VERSION ""

NS_ :

BS_:

BU_: BCM ELL ELR ERL ERR KHD N3P NAG NAP NCL NCP NPR NSP NVO PLG RSH RSL RSR SGW

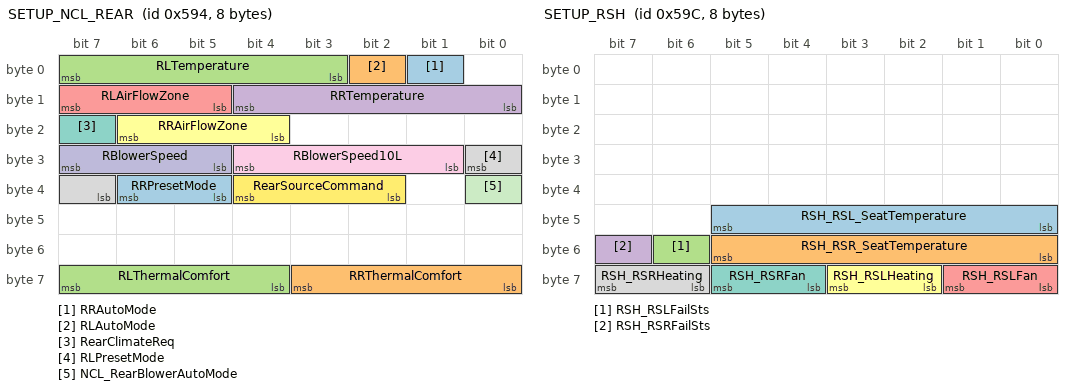
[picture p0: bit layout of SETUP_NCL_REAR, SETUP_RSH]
BO_ 1428 SETUP_NCL_REAR: 8 NCL
 SG_ RRAutoMode : 1|1@0+ (1,0) [0|1] ""  SGW
 SG_ RLAutoMode : 2|1@0+ (1,0) [0|1] ""  SGW
 SG_ RLTemperature : 7|5@0+ (0.5,15.5) [15.5|28.5] ""  SGW
 SG_ RRTemperature : 12|5@0+ (0.5,15.5) [15.5|28.5] ""  SGW
 SG_ RLAirFlowZone : 15|3@0+ (1,0) [0|7] ""  SGW
 SG_ RRAirFlowZone : 22|3@0+ (1,0) [0|7] ""  SGW
 SG_ RearClimateReq : 23|1@0+ (1,0) [0|1] ""  SGW
 SG_ RLPresetMode : 24|2@0+ (1,0) [0|3] ""  SGW
 SG_ RBlowerSpeed10L : 28|4@0+ (1,0) [0|15] ""  SGW
 SG_ RBlowerSpeed : 31|3@0+ (1,0) [0|7] ""  SGW
 SG_ NCL_RearBlowerAutoMode : 32|1@0+ (1,0) [0|1] ""  SGW
 SG_ RearSourceCommand : 36|3@0+ (1,0) [0|7] ""  SGW
 SG_ RRPresetMode : 38|2@0+ (1,0) [0|3] ""  SGW
 SG_ RRThermalComfort : 59|4@0+ (1,0) [0|15] ""  SGW
 SG_ RLThermalComfort : 63|4@0+ (1,0) [0|15] ""  SGW

BO_ 1429 SETUP_RSL: 8 RSL
 SG_ RSL_SeatTemperature : 1|6@0+ (1,-10) [-10|50] ""  NCL,SGW
 SG_ RSLHeating : 5|2@0+ (1,0) [0|3] ""  NCL,SGW
 SG_ RSLFans : 7|2@0+ (1,0) [0|3] ""  NCL,SGW

BO_ 1430 SETUP_RSR: 8 RSR
 SG_ RSR_SeatTemperature : 1|6@0+ (1,-10) [-10|50] ""  NCL,SGW
 SG_ RSRHeating : 5|2@0+ (1,0) [0|3] ""  NCL,SGW
 SG_ RSRFans : 7|2@0+ (1,0) [0|3] ""  NCL,SGW

BO_ 1431 SETUP_RSL_V3: 8 RSL
 SG_ RearSeatLeftBackRestPos : 18|11@0+ (1,0) [0|2047] ""  SGW
 SG_ RearSeatLeftLongitudinalPos : 39|11@0+ (1,0) [0|2047] ""  SGW
 SG_ RearSeatLeftTiltPos : 44|10@0+ (1,0) [0|1023] ""  SGW
 SG_ RearSeatLeftLiftPos : 50|11@0+ (1,0) [0|2047] ""  SGW

BO_ 1432 SETUP_RSR_V3: 8 RSR
 SG_ RearSeatRightBackRestPos : 18|11@0+ (1,0) [0|2047] ""  SGW
 SG_ RearSeatRightLongitudinalPos : 39|11@0+ (1,0) [0|2047] ""  SGW
 SG_ RearSeatRightTiltPos : 44|10@0+ (1,0) [0|1023] ""  SGW
 SG_ RearSeatRightLiftPos : 50|11@0+ (1,0) [0|2047] ""  SGW

BO_ 1436 SETUP_RSH: 8 RSH
 SG_ RSH_RSL_SeatTemperature : 45|6@0+ (1,-10) [-10|50] ""  NCL,SGW
 SG_ RSH_RSR_SeatTemperature : 53|6@0+ (1,-10) [-10|50] ""  NCL,SGW
 SG_ RSH_RSLFailSts : 54|1@0+ (1,0) [0|1] ""  SGW
 SG_ RSH_RSRFailSts : 55|1@0+ (1,0) [0|1] ""  SGW
 SG_ RSH_RSLFan : 57|2@0+ (1,0) [0|3] ""  NCL,SGW
 SG_ RSH_RSLHeating : 59|2@0+ (1,0) [0|3] ""  NCL,SGW
 SG_ RSH_RSRFan : 61|2@0+ (1,0) [0|3] ""  NCL,SGW
 SG_ RSH_RSRHeating : 63|2@0+ (1,0) [0|3] ""  NCL,SGW

BO_ 1441 PWT_STATUS_2: 8 SGW
 SG_ CRC_PWT_STATUS_2 : 7|8@0+ (1,0) [0|255] "" Vector__XXX
 SG_ ReducePowerAssist : 9|1@0+ (1,0) [0|1] "" Vector__XXX
 SG_ BatteryDisconnectionWarning : 10|1@0+ (1,0) [0|1] "" Vector__XXX
 SG_ VCU_EnergyProfileRqt : 13|3@0+ (1,0) [0|7] ""  NCL
 SG_ VehicleNotInUse : 15|2@0+ (1,0) [0|3] "" Vector__XXX
 SG_ EManettinoSts : 18|3@0+ (1,0) [0|7] ""  NCL
 SG_ EManettinoFailSts : 19|1@0+ (1,0) [0|1] ""  NCL
 SG_ EManettinoTransitionInfo : 22|3@0+ (1,0) [0|7] "" Vector__XXX
 SG_ MVLoadEnable_NPR : 23|1@0+ (1,0) [0|1] ""  NPR
 SG_ BatteryVoltageLevel : 30|7@0+ (0.16,0) [0|18] "volt"  KHD
 SG_ CruiseControlSts : 31|1@0+ (1,0) [0|1] "" Vector__XXX
 SG_ CruiseControlLampSts : 33|2@0+ (1,0) [0|3] "" Vector__XXX
 SG_ RechargeSts : 34|1@0+ (1,0) [0|1] "" Vector__XXX
 SG_ MsgCnt_PWT_STATUS_2 : 38|4@0+ (1,0) [0|15] "" Vector__XXX
 SG_ BatteryVoltageLevelFailSts : 39|1@0+ (1,0) [0|1] ""  KHD
 SG_ EngineSts : 45|2@0+ (1,0) [0|3] "" Vector__XXX
 SG_ StopStartSts : 47|2@0+ (1,0) [0|3] "" Vector__XXX
 SG_ PowertrainSts : 50|3@0+ (1,0) [0|7] "" Vector__XXX
 SG_ EDriveSts : 54|2@0+ (1,0) [0|3] "" Vector__XXX
 SG_ TargetSpeed : 63|8@0+ (1,0) [0|255] "km/h" Vector__XXX

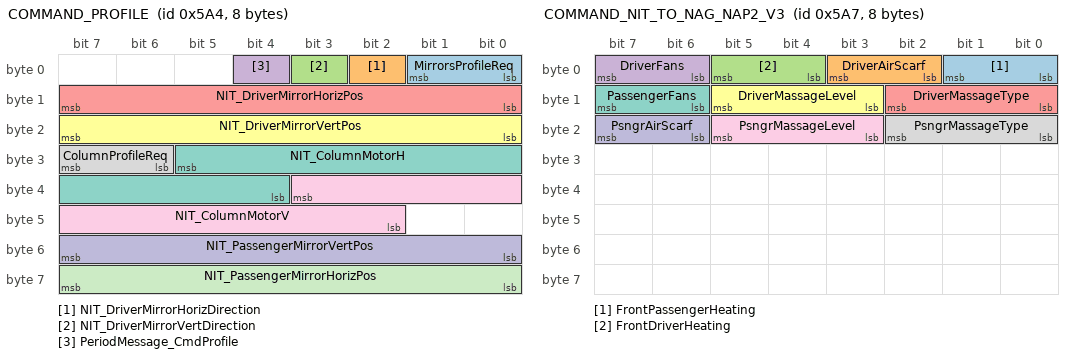
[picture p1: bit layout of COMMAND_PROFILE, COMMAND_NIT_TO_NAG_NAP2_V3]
BO_ 1444 COMMAND_PROFILE: 8 SGW
 SG_ MirrorsProfileReq : 1|2@0+ (1,0) [0|3] ""  BCM
 SG_ NIT_DriverMirrorHorizDirection : 2|1@0+ (1,0) [0|1] ""  BCM
 SG_ NIT_DriverMirrorVertDirection : 3|1@0+ (1,0) [0|1] ""  BCM
 SG_ PeriodMessage_CmdProfile : 4|1@0+ (1,0) [0|1] ""  BCM,NAG
 SG_ NIT_DriverMirrorHorizPos : 15|8@0+ (1,0) [0|255] ""  BCM
 SG_ NIT_DriverMirrorVertPos : 23|8@0+ (1,0) [0|255] ""  BCM
 SG_ NIT_ColumnMotorH : 29|10@0+ (1,0) [0|1023] ""  NAG
 SG_ ColumnProfileReq : 31|2@0+ (1,0) [0|3] ""  NAG
 SG_ NIT_ColumnMotorV : 35|10@0+ (1,0) [0|1023] ""  NAG
 SG_ NIT_PassengerMirrorVertPos : 55|8@0+ (1,0) [0|255] ""  BCM
 SG_ NIT_PassengerMirrorHorizPos : 63|8@0+ (1,0) [0|255] ""  BCM

BO_ 1446 COMMAND_NIT_TO_NBC: 8 SGW
 SG_ NITAmbientLightNightDay : 0|1@0+ (1,0) [0|1] ""  BCM
 SG_ NITAmbientLightNightDaySwitch : 1|1@0+ (1,0) [0|1] ""  BCM
 SG_ NITAmbientLightIntensityNight : 4|3@0+ (1,0) [0|7] ""  BCM
 SG_ NITAmbientLightIntensityDay : 7|3@0+ (1,0) [0|7] ""  BCM
 SG_ MirrorMovementReqCntrl : 8|1@0+ (1,0) [0|1] ""  BCM
 SG_ NITAmbientLightNightEnable : 10|1@0+ (1,0) [0|1] ""  BCM
 SG_ NITAmbientLightDayEnable : 11|1@0+ (1,0) [0|1] ""  BCM
 SG_ NITAmbientLightColour : 15|4@0+ (1,0) [0|15] ""  BCM
 SG_ NIT_DimmingLevelRoof2 : 34|3@0+ (1,0) [0|7] ""  BCM
 SG_ NIT_DimmingLevelRoof1 : 37|3@0+ (1,0) [0|7] ""  BCM
 SG_ IDC_Deactivation_DoorOpening_Swi : 40|1@0+ (1,0) [0|1] ""  BCM
 SG_ NITFailSts : 41|1@0+ (1,0) [0|1] ""  BCM
 SG_ NIT_DimmingLevelRoof4 : 44|3@0+ (1,0) [0|7] ""  BCM
 SG_ NIT_DimmingLevelRoof3 : 47|3@0+ (1,0) [0|7] ""  BCM
 SG_ NIT_DimmingLevelRoof6 : 50|3@0+ (1,0) [0|7] ""  BCM
 SG_ NIT_DimmingLevelRoof5 : 53|3@0+ (1,0) [0|7] ""  BCM
 SG_ IDC_Spot_RH_Button_Rear : 54|1@0+ (1,0) [0|1] ""  BCM
 SG_ IDC_Spot_LH_Button_Rear : 55|1@0+ (1,0) [0|1] ""  BCM
 SG_ ChargeButtonReq : 61|3@0+ (1,0) [0|7] ""  BCM
 SG_ IDC_RearLightCommand_Left : 62|1@0+ (1,0) [0|1] ""  BCM
 SG_ IDC_RearLightCommand_Right : 63|1@0+ (1,0) [0|1] ""  BCM

BO_ 1447 COMMAND_NIT_TO_NAG_NAP2_V3: 8 SGW
 SG_ FrontPassengerHeating : 1|2@0+ (1,0) [0|3] ""  NAG,NAP
 SG_ DriverAirScarf : 3|2@0+ (1,0) [0|3] ""  NAG,NAP
 SG_ FrontDriverHeating : 5|2@0+ (1,0) [0|3] ""  NAG,NAP
 SG_ DriverFans : 7|2@0+ (1,0) [0|3] ""  NAG,NAP
 SG_ DriverMassageType : 10|3@0+ (1,0) [0|7] ""  NAG,NAP
 SG_ DriverMassageLevel : 13|3@0+ (1,0) [0|7] ""  NAG,NAP
 SG_ PassengerFans : 15|2@0+ (1,0) [0|3] ""  NAG,NAP
 SG_ PsngrMassageType : 18|3@0+ (1,0) [0|7] ""  NAG,NAP
 SG_ PsngrMassageLevel : 21|3@0+ (1,0) [0|7] ""  NAG,NAP
 SG_ PsngrAirScarf : 23|2@0+ (1,0) [0|3] ""  NAG,NAP

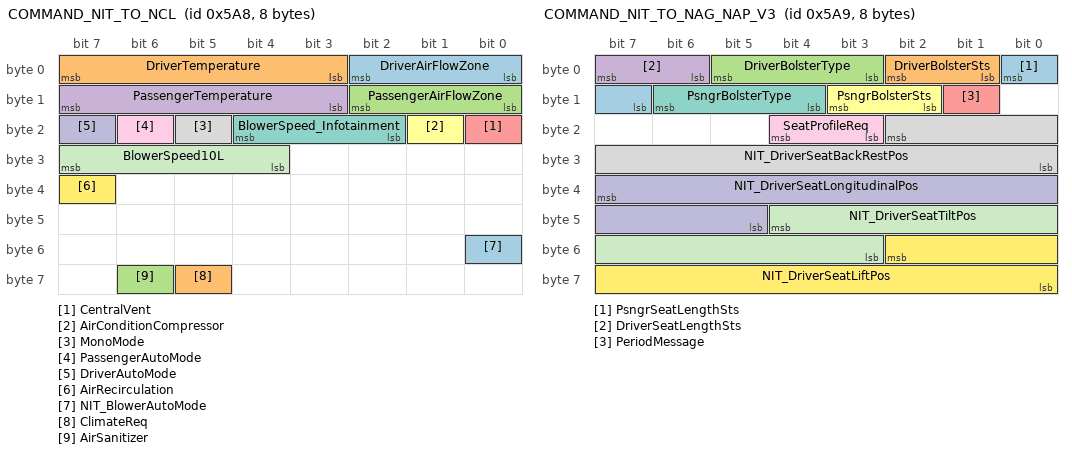
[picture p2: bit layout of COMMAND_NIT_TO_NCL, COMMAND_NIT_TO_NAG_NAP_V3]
BO_ 1448 COMMAND_NIT_TO_NCL: 8 SGW
 SG_ DriverAirFlowZone : 2|3@0+ (1,0) [0|7] ""  NCL
 SG_ DriverTemperature : 7|5@0+ (0.5,15.5) [15.5|28.5] ""  NCL
 SG_ PassengerAirFlowZone : 10|3@0+ (1,0) [0|7] ""  NCL
 SG_ PassengerTemperature : 15|5@0+ (0.5,15.5) [15.5|28.5] ""  NCL
 SG_ CentralVent : 16|1@0+ (1,0) [0|1] ""  NCL
 SG_ AirConditionCompressor : 17|1@0+ (1,0) [0|1] ""  NCL
 SG_ BlowerSpeed_Infotainment : 20|3@0+ (1,0) [0|7] ""  NCL
 SG_ MonoMode : 21|1@0+ (1,0) [0|1] ""  NCL
 SG_ PassengerAutoMode : 22|1@0+ (1,0) [0|1] ""  NCL
 SG_ DriverAutoMode : 23|1@0+ (1,0) [0|1] ""  NCL
 SG_ BlowerSpeed10L : 31|4@0+ (1,0) [0|15] ""  NCL
 SG_ AirRecirculation : 39|1@0+ (1,0) [0|1] ""  NCL
 SG_ NIT_BlowerAutoMode : 48|1@0+ (1,0) [0|1] ""  NCL
 SG_ ClimateReq : 61|1@0+ (1,0) [0|1] ""  NCL
 SG_ AirSanitizer : 62|1@0+ (1,0) [0|1] ""  NCL

BO_ 1449 COMMAND_NIT_TO_NAG_NAP_V3: 8 SGW
 SG_ PsngrSeatLengthSts : 0|2@0+ (1,0) [0|3] ""  NAG,NAP
 SG_ DriverBolsterSts : 2|2@0+ (1,0) [0|3] ""  NAG,NAP
 SG_ DriverBolsterType : 5|3@0+ (1,0) [0|7] ""  NAG,NAP
 SG_ DriverSeatLengthSts : 7|2@0+ (1,0) [0|3] ""  NAG,NAP
 SG_ PeriodMessage : 9|1@0+ (1,0) [0|1] ""  NAG,NAP
 SG_ PsngrBolsterSts : 11|2@0+ (1,0) [0|3] ""  NAG,NAP
 SG_ PsngrBolsterType : 14|3@0+ (1,0) [0|7] ""  NAG,NAP
 SG_ NIT_DriverSeatBackRestPos : 18|11@0+ (1,0) [0|2047] ""  NAG
 SG_ SeatProfileReq : 20|2@0+ (1,0) [0|3] ""  NAG
 SG_ NIT_DriverSeatLongitudinalPos : 39|11@0+ (1,0) [0|2047] ""  NAG
 SG_ NIT_DriverSeatTiltPos : 44|10@0+ (1,0) [0|1023] ""  NAG
 SG_ NIT_DriverSeatLiftPos : 50|11@0+ (1,0) [0|2047] ""  NAG

BO_ 1450 SETUP_NCL: 8 NCL
 SG_ AirRecirculation : 0|1@0+ (1,0) [0|1] ""  SGW
 SG_ PassengerAutoMode : 1|1@0+ (1,0) [0|1] ""  SGW
 SG_ DriverAutoMode : 2|1@0+ (1,0) [0|1] ""  SGW
 SG_ DriverTemperature : 7|5@0+ (0.5,15.5) [15.5|28.5] ""  SGW
 SG_ PassengerTemperature : 12|5@0+ (0.5,15.5) [15.5|28.5] ""  SGW
 SG_ DriverAirFlowZone : 15|3@0+ (1,0) [0|7] ""  SGW
 SG_ AirConditionCompressor : 16|1@0+ (1,0) [0|1] ""  SGW
 SG_ BlowerSpeed : 19|3@0+ (1,0) [0|7] ""  BCM,SGW
 SG_ PassengerAirFlowZone : 22|3@0+ (1,0) [0|7] ""  SGW
 SG_ MonoMode : 23|1@0+ (1,0) [0|1] ""  SGW
 SG_ BlowerSpeed10L : 28|4@0+ (1,0) [0|15] ""  SGW
 SG_ CentralVent : 29|1@0+ (1,0) [0|1] ""  SGW
 SG_ NCL_BlowerAutoMode : 33|1@0+ (1,0) [0|1] ""  SGW
 SG_ SourceCommand : 36|3@0+ (1,0) [0|7] ""  SGW
 SG_ Temp_Req_Down_Driver : 43|4@0+ (1,0) [0|15] ""  SGW
 SG_ Temp_Req_Up_Driver : 47|4@0+ (1,0) [0|15] ""  SGW
 SG_ AirSanitizer : 52|1@0+ (1,0) [0|1] ""  SGW
 SG_ ClimateReq : 56|1@0+ (1,0) [0|1] ""  SGW

BO_ 1451 COMMAND_NIT_TO_RSL_RSR: 8 SGW
 SG_ NIT_RLHeating : 5|2@0+ (1,0) [0|3] ""  RSH,RSL,RSR
 SG_ NIT_RLFans : 7|2@0+ (1,0) [0|3] ""  RSH,RSL,RSR
 SG_ NIT_RRHeating : 13|2@0+ (1,0) [0|3] ""  RSH,RSL,RSR
 SG_ NIT_RRFans : 15|2@0+ (1,0) [0|3] ""  RSH,RSL,RSR

BO_ 1452 COMMAND_NIT_TO_NCL_REAR: 8 SGW
 SG_ NIT_RLAirFlowZone : 2|3@0+ (1,0) [0|7] ""  NCL
 SG_ NIT_RLTemperature : 7|5@0+ (0.5,15.5) [15.5|28.5] ""  NCL
 SG_ NIT_RRAirFlowZone : 10|3@0+ (1,0) [0|7] ""  NCL
 SG_ NIT_RRTemperature : 15|5@0+ (0.5,15.5) [15.5|28.5] ""  NCL
 SG_ RearClimateReq : 16|1@0+ (1,0) [0|1] ""  NCL
 SG_ NIT_RearBlowerSpeed : 20|3@0+ (1,0) [0|7] ""  NCL
 SG_ NIT_RRAutoMode : 22|1@0+ (1,0) [0|1] ""  NCL
 SG_ NIT_RLAutoMode : 23|1@0+ (1,0) [0|1] ""  NCL
 SG_ NIT_RRPresetMode : 25|2@0+ (1,0) [0|3] ""  NCL
 SG_ NIT_RLPresetMode : 27|2@0+ (1,0) [0|3] ""  NCL
 SG_ NIT_RearBlowerSpeed10L : 31|4@0+ (1,0) [0|15] ""  NCL
 SG_ NIT_RLAirFlowZonePersPreset : 33|3@0+ (1,0) [0|7] ""  NCL
 SG_ NIT_RLTemperaturePersPreset : 38|5@0+ (0.5,15.5) [15.5|28.5] ""  NCL
 SG_ NIT_RearBlowerAutoMode : 39|1@0+ (1,0) [0|1] ""  NCL
 SG_ NIT_RRAirFlowZonePersPreset : 42|3@0+ (1,0) [0|7] ""  NCL
 SG_ NIT_RearBlowerSpeed10LPersPreset : 46|4@0+ (1,0) [0|15] ""  NCL
 SG_ NIT_RRTemperaturePersPreset : 55|5@0+ (0.5,15.5) [15.5|28.5] ""  NCL

BO_ 1454 COMMAND_MKF_TO_NBC: 8 Vector__XXX
 SG_ MKF_DimmingLevelRoof1 : 6|3@0+ (1,0) [0|7] ""  NCL
 SG_ MKF_RimHeatingCommand : 7|1@0+ (1,0) [0|1] ""  NCL

BO_ 1457 SETUP_NBC: 8 BCM
 SG_ NBCAmbientLightNightDay : 0|1@0+ (1,0) [0|1] ""  SGW
 SG_ NBCAmbientLightNightDaySwitch : 1|1@0+ (1,0) [0|1] ""  SGW
 SG_ NBCAmbientLightIntensityNight : 4|3@0+ (1,0) [0|7] ""  SGW
 SG_ NBCAmbientLightIntensityDay : 7|3@0+ (1,0) [0|7] ""  SGW
 SG_ NBCAmbientLightDayEnable : 8|1@0+ (1,0) [0|1] ""  SGW
 SG_ NBC_DimmingLevelRoof1 : 11|3@0+ (1,0) [0|7] ""  NCL,SGW
 SG_ NBCAmbientLightColour : 15|4@0+ (1,0) [0|15] ""  SGW
 SG_ NBCAmbientLightNightEnable : 17|1@0+ (1,0) [0|1] ""  SGW
 SG_ NBC_DimmingLevelRoof3 : 20|3@0+ (1,0) [0|7] ""  SGW
 SG_ NBC_DimmingLevelRoof2 : 23|3@0+ (1,0) [0|7] ""  SGW
 SG_ NBCAmbientLightResponseError : 24|1@0+ (1,0) [0|1] ""  SGW
 SG_ NBCAmbientLightEnable : 25|1@0+ (1,0) [0|1] ""  SGW
 SG_ NBC_DimmingLevelRoof5 : 28|3@0+ (1,0) [0|7] ""  SGW
 SG_ NBC_DimmingLevelRoof4 : 31|3@0+ (1,0) [0|7] ""  SGW
 SG_ NBCAmbientLightGenericFailSts : 32|1@0+ (1,0) [0|1] ""  SGW
 SG_ NBCAmbientLightCurrentFailSts : 33|1@0+ (1,0) [0|1] ""  SGW
 SG_ WiperWaterLevelLampSts : 34|1@0+ (1,0) [0|1] ""  SGW
 SG_ WiperWaterLowLevel : 35|1@0+ (1,0) [0|1] ""  SGW
 SG_ NBC_DimmingLevelRoof6 : 39|3@0+ (1,0) [0|7] ""  SGW
 SG_ NVDFailSts : 43|1@0+ (1,0) [0|1] ""  SGW

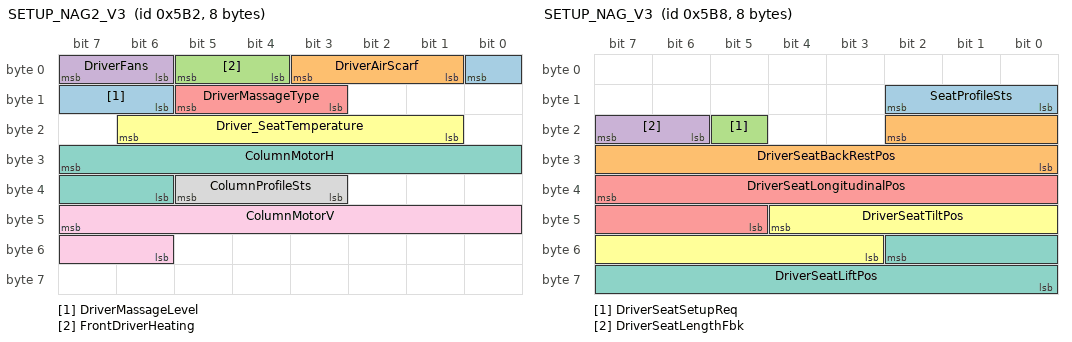
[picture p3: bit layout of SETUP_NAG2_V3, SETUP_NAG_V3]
BO_ 1458 SETUP_NAG2_V3: 8 NAG
 SG_ DriverMassageLevel : 0|3@0+ (1,0) [0|7] ""  NCL,SGW
 SG_ DriverAirScarf : 3|3@0+ (1,0) [0|7] ""  SGW
 SG_ FrontDriverHeating : 5|2@0+ (1,0) [0|3] ""  NCL,SGW
 SG_ DriverFans : 7|2@0+ (1,0) [0|3] ""  NCL,SGW
 SG_ DriverMassageType : 13|3@0+ (1,0) [0|7] ""  SGW
 SG_ Driver_SeatTemperature : 22|6@0+ (1,-10) [-10|50] ""  NCL,SGW
 SG_ ColumnMotorH : 31|10@0+ (1,0) [0|1023] ""  SGW
 SG_ ColumnProfileSts : 37|3@0+ (1,0) [0|7] ""  SGW
 SG_ ColumnMotorV : 47|10@0+ (1,0) [0|1023] ""  SGW

BO_ 1463 SETUP_NAP2: 8 NAP
 SG_ PsngrMassageLevel : 0|3@0+ (1,0) [0|7] ""  NCL,SGW
 SG_ PsngrAirScarf : 3|3@0+ (1,0) [0|7] ""  SGW
 SG_ FrontPassengerHeating : 5|2@0+ (1,0) [0|3] ""  NCL,SGW
 SG_ PassengerFans : 7|2@0+ (1,0) [0|3] ""  NCL,SGW
 SG_ PsngrMassageType : 13|3@0+ (1,0) [0|7] ""  SGW
 SG_ Psngr_SeatTemperature : 22|6@0+ (1,-10) [-10|50] ""  NCL,SGW

BO_ 1464 SETUP_NAG_V3: 8 NAG
 SG_ SeatProfileSts : 10|3@0+ (1,0) [0|7] ""  SGW
 SG_ DriverSeatBackRestPos : 18|11@0+ (1,0) [0|2047] ""  SGW
 SG_ DriverSeatSetupReq : 21|1@0+ (1,0) [0|1] ""  SGW
 SG_ DriverSeatLengthFbk : 23|2@0+ (1,0) [0|3] ""  SGW
 SG_ DriverSeatLongitudinalPos : 39|11@0+ (1,0) [0|2047] ""  SGW
 SG_ DriverSeatTiltPos : 44|10@0+ (1,0) [0|1023] ""  SGW
 SG_ DriverSeatLiftPos : 50|11@0+ (1,0) [0|2047] ""  SGW

BO_ 1465 SETUP_NAP_V3: 8 NAP
 SG_ PsngrSeatBackRestPos : 18|11@0+ (1,0) [0|2047] ""  SGW
 SG_ PsngrSeatSetupReq : 21|1@0+ (1,0) [0|1] ""  SGW
 SG_ PsngrSeatLengthFbk : 23|2@0+ (1,0) [0|3] ""  SGW
 SG_ PsngrSeatLongitudinalPos : 39|11@0+ (1,0) [0|2047] ""  SGW
 SG_ PsngrSeatTiltPos : 44|10@0+ (1,0) [0|1023] ""  SGW
 SG_ PsngrSeatLiftPos : 50|11@0+ (1,0) [0|2047] ""  SGW

BO_ 1485 HVB_HMI_STS: 8 SGW
 SG_ CRC_HVB_HMI_STS : 7|8@0+ (1,0) [0|255] ""  NCL
 SG_ LongParkingInfoForDisplay : 10|3@0+ (1,0) [0|7] "" Vector__XXX
 SG_ HVBBuzzerReq : 11|1@0+ (1,0) [0|1] "" Vector__XXX
 SG_ MsgCnt_HVB_HMI_STS : 15|4@0+ (1,0) [0|14] ""  NCL
 SG_ HVBChargeWarningForDisplay : 20|5@0+ (1,0) [0|31] "" Vector__XXX
 SG_ LongParkingSts : 21|1@0+ (1,0) [0|1] "" Vector__XXX
 SG_ HVBSOC_Status_HMI : 23|2@0+ (1,0) [0|3] "" Vector__XXX
 SG_ HVB_SOC_BEV_HMI : 31|8@0+ (0.392156862745098,0) [0|100] "%"  NCL
 SG_ HVB_TemperatureFailSts : 33|2@0+ (1,0) [0|3] "" Vector__XXX
 SG_ BatPrecondSts : 35|2@0+ (1,0) [0|3] "" Vector__XXX
 SG_ HVSysWarningForDisplay : 39|4@0+ (1,0) [0|15] "" Vector__XXX
 SG_ BatEstTimeToTarget : 46|7@0+ (1,0) [0|127] "min" Vector__XXX
 SG_ MILrequest : 47|1@0+ (1,0) [0|1] "" Vector__XXX
 SG_ BatPrecondProgress : 55|8@0+ (0.5,0) [0|127.5] "%" Vector__XXX
 SG_ HVBWarningForDisplay : 60|5@0+ (1,0) [0|31] "" Vector__XXX
 SG_ HVBStatus : 62|2@0+ (1,0) [0|3] "" Vector__XXX
 SG_ HVBSOC_Status_China_HMI : 63|1@0+ (1,0) [0|1] "" Vector__XXX

BO_ 1533 LIN_MIRROR_FEEDBACK: 8 BCM
 SG_ Fdbk_Pos_Hor_LH_Exmi : 7|8@0+ (1,0) [0|255] "Position Value"  SGW
 SG_ Fdbk_Pos_Ver_LH_Exmi : 15|8@0+ (1,0) [0|255] "Position Value"  SGW
 SG_ Fdbk_Pos_Hor_RH_Exmi : 23|8@0+ (1,0) [0|255] "Position Value"  SGW
 SG_ Fdbk_Pos_Ver_RH_Exmi : 31|8@0+ (1,0) [0|255] "Position Value"  SGW
 SG_ MirrorsProfileSts : 37|3@0+ (1,0) [0|7] ""  SGW

BO_ 1539 TRIP_A_E_B: 8 SGW
 SG_ TotalOdometer : 11|20@0+ (1,0) [0|999999] "km"  BCM,ELL,ELR,ERL,ERR,KHD,N3P,NCL,NCP,NPR,RSH

BO_ 1566 NIT_TO_NVO_DEBUG_MESSAGE: 8 SGW
 SG_ CommandWord : 7|8@0+ (1,0) [0|255] "" Vector__XXX
 SG_ CommandParameter1 : 15|8@0+ (1,0) [0|255] "" Vector__XXX
 SG_ CommandParameter2 : 23|8@0+ (1,0) [0|255] "" Vector__XXX
 SG_ CommandParameter3 : 31|8@0+ (1,0) [0|255] "" Vector__XXX
 SG_ CommandParameter4 : 39|8@0+ (1,0) [0|255] "" Vector__XXX
 SG_ CommandParameter5 : 47|8@0+ (1,0) [0|255] "" Vector__XXX
 SG_ CommandParameter6 : 55|8@0+ (1,0) [0|255] "" Vector__XXX

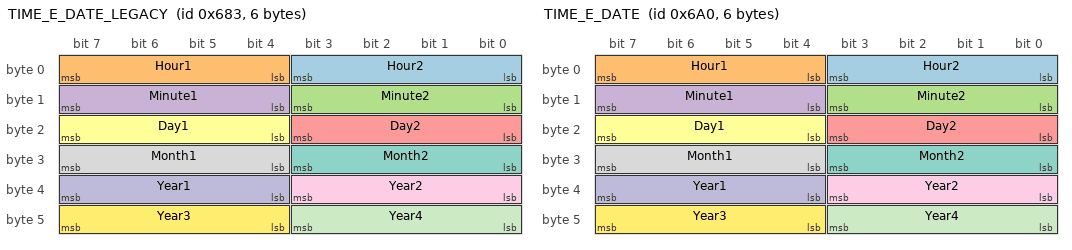
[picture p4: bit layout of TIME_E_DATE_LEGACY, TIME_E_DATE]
BO_ 1667 TIME_E_DATE_LEGACY: 6 BCM
 SG_ Hour2 : 3|4@0+ (1,0) [0|9] ""  ELL,ELR,ERL,ERR
 SG_ Hour1 : 7|4@0+ (1,0) [0|9] ""  ELL,ELR,ERL,ERR
 SG_ Minute2 : 11|4@0+ (1,0) [0|9] ""  ELL,ELR,ERL,ERR
 SG_ Minute1 : 15|4@0+ (1,0) [0|9] ""  ELL,ELR,ERL,ERR
 SG_ Day2 : 19|4@0+ (1,0) [0|9] ""  ELL,ELR,ERL,ERR
 SG_ Day1 : 23|4@0+ (1,0) [0|9] ""  ELL,ELR,ERL,ERR
 SG_ Month2 : 27|4@0+ (1,0) [0|9] ""  ELL,ELR,ERL,ERR
 SG_ Month1 : 31|4@0+ (1,0) [0|9] ""  ELL,ELR,ERL,ERR
 SG_ Year2 : 35|4@0+ (1,0) [0|9] ""  ELL,ELR,ERL,ERR
 SG_ Year1 : 39|4@0+ (1,0) [0|9] ""  ELL,ELR,ERL,ERR
 SG_ Year4 : 43|4@0+ (1,0) [0|9] ""  ELL,ELR,ERL,ERR
 SG_ Year3 : 47|4@0+ (1,0) [0|9] ""  ELL,ELR,ERL,ERR

BO_ 1671 NCL_TO_AUDIO_MSG1: 8 NCL
 SG_ LateralVentRgt : 21|6@0+ (2,0) [0|126] ""  SGW
 SG_ LateralVentLft : 29|6@0+ (2,0) [0|126] ""  SGW
 SG_ CentralVentRgt : 39|8@0+ (1,0) [0|255] ""  SGW
 SG_ CentralVentLft : 47|8@0+ (1,0) [0|255] ""  SGW
 SG_ BlwrPWMRr : 55|8@0+ (1,0) [0|255] ""  SGW
 SG_ BlwrPWM : 63|8@0+ (1,0) [0|255] ""  SGW

BO_ 1672 NCL_TO_AUDIO_MSG2: 8 NCL
 SG_ RHVACDistrib : 37|6@0+ (2,0) [0|126] ""  SGW
 SG_ TunnelDistrib : 45|6@0+ (2,0) [0|126] ""  SGW
 SG_ FloorRgt : 53|6@0+ (2,0) [0|126] ""  SGW
 SG_ FloorLft : 61|6@0+ (2,0) [0|126] ""  SGW

BO_ 1673 NCL_INFO: 8 NCL
 SG_ AirQualityIndexExternal : 0|9@0+ (1,0) [0|511] ""  SGW
 SG_ CabinTemperature : 23|8@0+ (1,-40) [-40|100] ""  NAG,NAP,SGW
 SG_ DriverCabinTemperatureFbk : 31|8@0+ (0.5,-20) [-20|60] "°C"  SGW
 SG_ PassengerCabinTemperatureFbk : 39|8@0+ (0.5,-20) [-20|60] "°C"  SGW
 SG_ NCL_EnergyProfileFbk : 42|3@0+ (1,0) [0|7] ""  SGW
 SG_ RLCabinTemperatureFbk : 55|8@0+ (0.5,-20) [-20|60] ""  SGW
 SG_ RRCabinTemperatureFbk : 63|8@0+ (0.5,-20) [-20|60] ""  SGW

BO_ 1674 NCL_Message2: 8 NCL
 SG_ CabTempFilt : 40|7@0+ (1,0) [0|127] "°C" Vector__XXX

BO_ 1696 TIME_E_DATE: 6 SGW
 SG_ Hour2 : 3|4@0+ (1,0) [0|9] ""  ELL,ELR,ERL,ERR,KHD,N3P,NCL,NCP,RSH
 SG_ Hour1 : 7|4@0+ (1,0) [0|9] ""  ELL,ELR,ERL,ERR,KHD,N3P,NCL,NCP,RSH
 SG_ Minute2 : 11|4@0+ (1,0) [0|9] ""  ELL,ELR,ERL,ERR,KHD,N3P,NCL,NCP,RSH
 SG_ Minute1 : 15|4@0+ (1,0) [0|9] ""  ELL,ELR,ERL,ERR,KHD,N3P,NCL,NCP,RSH
 SG_ Day2 : 19|4@0+ (1,0) [0|9] ""  ELL,ELR,ERL,ERR,KHD,N3P,NCL,NCP,RSH
 SG_ Day1 : 23|4@0+ (1,0) [0|9] ""  ELL,ELR,ERL,ERR,KHD,N3P,NCL,NCP,RSH
 SG_ Month2 : 27|4@0+ (1,0) [0|9] ""  ELL,ELR,ERL,ERR,KHD,N3P,NCL,NCP,RSH
 SG_ Month1 : 31|4@0+ (1,0) [0|9] ""  ELL,ELR,ERL,ERR,KHD,N3P,NCL,NCP,RSH
 SG_ Year2 : 35|4@0+ (1,0) [0|9] ""  ELL,ELR,ERL,ERR,KHD,N3P,NCL,NCP,RSH
 SG_ Year1 : 39|4@0+ (1,0) [0|9] ""  ELL,ELR,ERL,ERR,KHD,N3P,NCL,NCP,RSH
 SG_ Year4 : 43|4@0+ (1,0) [0|9] ""  ELL,ELR,ERL,ERR,KHD,N3P,NCL,NCP,RSH
 SG_ Year3 : 47|4@0+ (1,0) [0|9] ""  ELL,ELR,ERL,ERR,KHD,N3P,NCL,NCP,RSH

BO_ 1726 NIT_VEHICLE_SETUP_3: 8 SGW
 SG_ CabinLightNightDaySwitch : 8|1@0+ (1,0) [0|1] ""  BCM
 SG_ CabinLight_Feet_Enable : 9|1@0+ (1,0) [0|1] ""  BCM
 SG_ CabinLight_DoorPanel_Enable : 10|1@0+ (1,0) [0|1] ""  BCM
 SG_ AutoDoorsAlert : 11|1@0+ (1,0) [0|1] ""  BCM
 SG_ EManettinoPreset : 14|3@0+ (1,0) [0|7] ""  BCM
 SG_ SmartOverbrakingEnable : 15|1@0+ (1,0) [0|1] ""  BCM
 SG_ CabinLight_Feet_Level : 19|4@0+ (1,0) [0|15] ""  BCM
 SG_ CabinLight_DoorPanel_Level : 23|4@0+ (1,0) [0|15] ""  BCM
 SG_ InternalLightEnable : 24|1@0+ (1,0) [0|1] ""  BCM
 SG_ ChargePlugAutoUnlock : 27|2@0+ (1,0) [0|3] ""  BCM
 SG_ ActiveProfile : 31|4@0+ (1,0) [0|15] ""  BCM
 SG_ User_Max_SOC : 38|7@0+ (1,0) [0|100] "%"  BCM
 SG_ PassiveEntryEnable : 39|1@0+ (1,0) [0|1] ""  BCM
 SG_ PresentProfile : 41|11@0+ (1,0) [0|2047] ""  BCM
 SG_ PersonalDataConsentSts : 57|2@0+ (1,0) [0|3] ""  BCM
 SG_ StealthModeActive : 58|1@0+ (1,0) [0|1] ""  BCM
 SG_ User_SOC_Preset : 60|2@0+ (1,0) [0|3] ""  BCM
 SG_ ChargeFlapUnlock : 61|1@0+ (1,0) [0|1] ""  BCM
 SG_ AntiTiltAlarmCommand : 62|1@0+ (1,0) [0|1] ""  BCM

BO_ 1728 EOL_CONFIGURATION_V4: 8 BCM
 SG_ BatteryType : 13|4@0+ (1,0) [0|15] ""  NAG,NAP,RSL,RSR
 SG_ Profile : 36|1@0+ (1,0) [0|1] ""  NAG

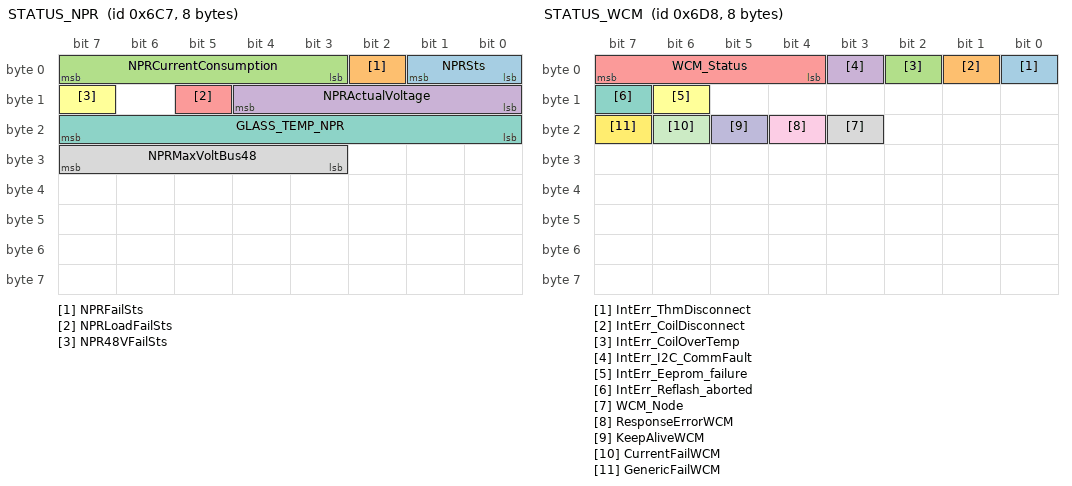
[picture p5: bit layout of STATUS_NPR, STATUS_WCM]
BO_ 1735 STATUS_NPR: 8 NPR
 SG_ NPRSts : 1|2@0+ (1,0) [0|3] ""  NCL,SGW
 SG_ NPRFailSts : 2|1@0+ (1,0) [0|1] ""  NCL,SGW
 SG_ NPRCurrentConsumption : 7|5@0+ (1,0) [0|31] "A"  SGW
 SG_ NPRActualVoltage : 12|5@0+ (2,0) [0|62] "V"  NCL,SGW
 SG_ NPRLoadFailSts : 13|1@0+ (1,0) [0|1] ""  SGW
 SG_ NPR48VFailSts : 15|1@0+ (1,0) [0|1] ""  SGW
 SG_ GLASS_TEMP_NPR : 23|8@0+ (0.5,-40) [-40|87.5] "°C"  NCL,SGW
 SG_ NPRMaxVoltBus48 : 31|5@0+ (2,0) [0|62] "V"  NCL,SGW

BO_ 1752 STATUS_WCM: 8 SGW
 SG_ IntErr_ThmDisconnect : 0|1@0+ (1,0) [0|1] "" Vector__XXX
 SG_ IntErr_CoilDisconnect : 1|1@0+ (1,0) [0|1] "" Vector__XXX
 SG_ IntErr_CoilOverTemp : 2|1@0+ (1,0) [0|1] "" Vector__XXX
 SG_ IntErr_I2C_CommFault : 3|1@0+ (1,0) [0|1] "" Vector__XXX
 SG_ WCM_Status : 7|4@0+ (1,0) [0|15] "" Vector__XXX
 SG_ IntErr_Eeprom_failure : 14|1@0+ (1,0) [0|1] "" Vector__XXX
 SG_ IntErr_Reflash_aborted : 15|1@0+ (1,0) [0|1] "" Vector__XXX
 SG_ WCM_Node : 19|1@0+ (1,0) [0|1] "" Vector__XXX
 SG_ ResponseErrorWCM : 20|1@0+ (1,0) [0|1] "" Vector__XXX
 SG_ KeepAliveWCM : 21|1@0+ (1,0) [0|1] "" Vector__XXX
 SG_ CurrentFailWCM : 22|1@0+ (1,0) [0|1] "" Vector__XXX
 SG_ GenericFailWCM : 23|1@0+ (1,0) [0|1] "" Vector__XXX

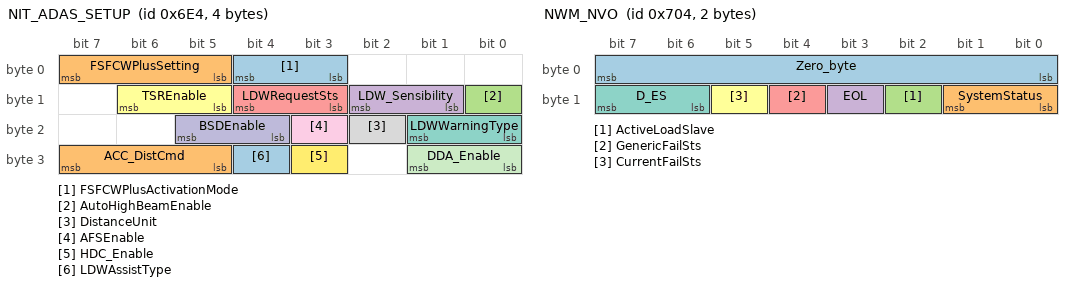
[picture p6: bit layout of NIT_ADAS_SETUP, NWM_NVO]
BO_ 1764 NIT_ADAS_SETUP: 4 SGW
 SG_ FSFCWPlusActivationMode : 4|2@0+ (1,0) [0|3] "" Vector__XXX
 SG_ FSFCWPlusSetting : 7|3@0+ (1,0) [0|7] "" Vector__XXX
 SG_ AutoHighBeamEnable : 8|1@0+ (1,0) [0|1] ""  BCM
 SG_ LDW_Sensibility : 10|2@0+ (1,0) [0|3] "" Vector__XXX
 SG_ LDWRequestSts : 12|2@0+ (1,0) [0|3] "" Vector__XXX
 SG_ TSREnable : 14|2@0+ (1,0) [0|3] "" Vector__XXX
 SG_ LDWWarningType : 17|2@0+ (1,0) [0|3] "" Vector__XXX
 SG_ DistanceUnit : 18|1@0+ (1,0) [0|1] "" Vector__XXX
 SG_ AFSEnable : 19|1@0+ (1,0) [0|1] ""  BCM
 SG_ BSDEnable : 21|2@0+ (1,0) [0|3] "" Vector__XXX
 SG_ DDA_Enable : 25|2@0+ (1,0) [0|3] "" Vector__XXX
 SG_ HDC_Enable : 27|1@0+ (1,0) [0|1] ""  NVO
 SG_ LDWAssistType : 28|1@0+ (1,0) [0|1] "" Vector__XXX
 SG_ ACC_DistCmd : 31|3@0+ (1,0) [0|7] "" Vector__XXX

BO_ 1767 NIT_VEHICLE_SETUP: 8 SGW
 SG_ LanguageSelection : 5|6@0+ (1,0) [0|63] ""  BCM
 SG_ TemperatureUnit : 6|1@0+ (1,0) [0|1] ""  BCM,NCL
 SG_ DistanceUnit : 7|1@0+ (1,0) [0|1] ""  BCM
 SG_ AutomaticMirrorFoldingEnable : 8|1@0+ (1,0) [0|1] ""  BCM
 SG_ HourMode : 9|1@0+ (1,0) [0|1] ""  BCM
 SG_ WiperRLSSensibility : 11|2@0+ (1,0) [0|3] ""  BCM
 SG_ WelcomeInCarEnable : 12|1@0+ (1,0) [0|1] ""  BCM
 SG_ BuzzerVolumeWarning : 15|3@0+ (1,0) [0|7] ""  BCM
 SG_ SpeedThreshold : 21|6@0+ (5,0) [0|250] "Km/h or mph"  BCM
 SG_ LockTimeout : 25|2@0+ (1,0) [0|3] ""  BCM
 SG_ ResetTripAReq : 26|1@0+ (1,0) [0|1] ""  BCM
 SG_ DriverDoorUnlockEnable : 27|1@0+ (1,0) [0|1] ""  BCM
 SG_ SpeedLockDoorEnable : 28|1@0+ (1,0) [0|1] ""  BCM
 SG_ ExternalLightSensorLevel : 33|2@0+ (1,0) [0|3] ""  BCM
 SG_ SpeedThresholdEnable : 34|1@0+ (1,0) [0|1] ""  BCM
 SG_ WalkAwayEnabled : 35|1@0+ (1,0) [0|1] ""  BCM
 SG_ GloveBoxUnlockEnable : 39|1@0+ (1,0) [0|1] ""  BCM
 SG_ Stop_GoEnable : 40|1@0+ (1,0) [0|1] ""  BCM,NSP
 SG_ EngineSpeedDisplayLedEnable : 43|1@0+ (1,0) [0|1] ""  BCM
 SG_ SnowChainMode : 44|1@0+ (1,0) [0|1] ""  BCM
 SG_ PressureUnit : 46|1@0+ (1,0) [0|1] ""  BCM
 SG_ RPMAreaColor : 50|3@0+ (1,0) [0|7] ""  BCM
 SG_ NTPCalibrationReqSts : 51|1@0+ (1,0) [0|1] ""  BCM
 SG_ EmergencyStopSignallingEnable : 54|1@0+ (1,0) [0|1] ""  BCM
 SG_ RearAutoDoorAlert : 56|1@0+ (1,0) [0|1] ""  BCM,ERL,ERR
 SG_ MirrorAutoTiltEnable : 57|1@0+ (1,0) [0|1] ""  BCM
 SG_ SpeedLimitSignEnable : 58|1@0+ (1,0) [0|1] ""  BCM
 SG_ TrafficChangeEnable : 62|2@0+ (1,0) [0|3] ""  BCM
 SG_ AutolockEnable : 63|1@0+ (1,0) [0|1] ""  BCM

BO_ 1772 NIT_VEHICLE_SETUP_2: 8 SGW
 SG_ SingleDoorUnlockEnable : 8|1@0+ (1,0) [0|1] ""  BCM
 SG_ LongParkingSetting : 17|2@0+ (1,0) [0|3] "" Vector__XXX
 SG_ FeetLightKeyOnActivation : 23|2@0+ (1,0) [0|3] ""  BCM
 SG_ AmbientLightEnable : 24|1@0+ (1,0) [0|1] ""  BCM
 SG_ ShowOnDisplay_Seats : 26|2@0+ (1,0) [0|3] "" Vector__XXX
 SG_ ShowOnDisplay_Climate : 28|2@0+ (1,0) [0|3] "" Vector__XXX
 SG_ ShowOnDisplay_Time_Temperature : 29|1@0+ (1,0) [0|1] "" Vector__XXX
 SG_ EasyEntrySet : 31|2@0+ (1,0) [0|3] ""  NAG
 SG_ NIT_PassengerExtendedClimate : 33|2@0+ (1,0) [0|3] "" Vector__XXX
 SG_ NIT_DriverExtendedClimate : 35|2@0+ (1,0) [0|3] "" Vector__XXX
 SG_ RimHeating_Profile : 37|1@0+ (1,0) [0|1] ""  NCL
 SG_ LiftGateAlertEnable : 39|1@0+ (1,0) [0|1] ""  PLG
 SG_ NIT_RearPassengerExtendedClimate : 47|2@0+ (1,0) [0|3] "" Vector__XXX
 SG_ Battery_Saving : 48|1@0+ (1,0) [0|1] "" Vector__XXX
 SG_ RimHeatingCommand : 52|1@0+ (1,0) [0|1] ""  BCM
 SG_ GmeterReset : 53|1@0+ (1,0) [0|1] "" Vector__XXX
 SG_ SoundFeedbackLevel : 55|2@0+ (1,0) [0|3] "" Vector__XXX
 SG_ LongParkingUserAction : 63|1@0+ (1,0) [0|1] "" Vector__XXX

BO_ 1792 NWM_NBC: 6 BCM
 SG_ Zero_byte : 7|8@0+ (1,0) [0|0] ""  ELL,ELR,ERL,ERR,KHD,N3P,NAG,NAP,NCL,NCP,NPR,NSP,NVO,PLG,RSH,RSL,RSR,SGW
 SG_ SystemCommand : 9|2@0+ (1,0) [0|3] ""  ELL,ELR,ERL,ERR,KHD,N3P,NAG,NAP,NCL,NCP,NPR,NSP,NVO,PLG,RSH,RSL,RSR,SGW
 SG_ ActiveLoadMaster : 10|1@0+ (1,0) [0|1] ""  ELL,ELR,ERL,ERR,KHD,N3P,NAG,NAP,NCL,NCP,NPR,NSP,NVO,PLG,RSH,RSL,RSR,SGW
 SG_ EOL : 11|1@0+ (1,0) [0|1] ""  ELL,ELR,ERL,ERR,KHD,N3P,NAG,NAP,NCL,NCP,NPR,NSP,NVO,PLG,RSH,RSL,RSR,SGW
 SG_ GenericFailSts : 12|1@0+ (1,0) [0|1] ""  ELL,ELR,ERL,ERR,KHD,N3P,NAG,NAP,NCL,NCP,NPR,NSP,NVO,PLG,RSH,RSL,RSR,SGW
 SG_ P_ES : 13|1@0+ (1,0) [0|1] ""  ELL,ELR,ERL,ERR,KHD,N3P,NAG,NAP,NCL,NCP,NPR,NSP,NVO,PLG,RSH,RSL,RSR,SGW
 SG_ D_ES : 15|2@0+ (1,0) [0|3] ""  ELL,ELR,ERL,ERR,KHD,N3P,NAG,NAP,NCL,NCP,NPR,NSP,NVO,PLG,RSH,RSL,RSR,SGW
 SG_ Node_24 : 16|1@0+ (1,0) [0|1] ""  ELL,ELR,ERL,ERR,KHD,N3P,NAG,NAP,NCL,NCP,NPR,NSP,NVO,PLG,RSH,RSL,RSR,SGW
 SG_ Node_25 : 17|1@0+ (1,0) [0|1] ""  ELL,ELR,ERL,ERR,KHD,N3P,NAG,NAP,NCL,NCP,NPR,NSP,NVO,PLG,RSH,RSL,RSR,SGW
 SG_ Node_26 : 18|1@0+ (1,0) [0|1] ""  ELL,ELR,ERL,ERR,KHD,N3P,NAG,NAP,NCL,NCP,NPR,NSP,NVO,PLG,RSH,RSL,RSR,SGW
 SG_ Node_27 : 19|1@0+ (1,0) [0|1] ""  ELL,ELR,ERL,ERR,KHD,N3P,NAG,NAP,NCL,NCP,NPR,NSP,NVO,PLG,RSH,RSL,RSR,SGW
 SG_ Node_28 : 20|1@0+ (1,0) [0|1] ""  ELL,ELR,ERL,ERR,KHD,N3P,NAG,NAP,NCL,NCP,NPR,NSP,NVO,PLG,RSH,RSL,RSR,SGW
 SG_ Node_29 : 21|1@0+ (1,0) [0|1] ""  ELL,ELR,ERL,ERR,KHD,N3P,NAG,NAP,NCL,NCP,NPR,NSP,NVO,PLG,RSH,RSL,RSR,SGW
 SG_ Node_30 : 22|1@0+ (1,0) [0|1] ""  ELL,ELR,ERL,ERR,KHD,N3P,NAG,NAP,NCL,NCP,NPR,NSP,NVO,PLG,RSH,RSL,RSR,SGW
 SG_ Node_31 : 23|1@0+ (1,0) [0|1] ""  ELL,ELR,ERL,ERR,KHD,N3P,NAG,NAP,NCL,NCP,NPR,NSP,NVO,PLG,RSH,RSL,RSR,SGW
 SG_ Node_16 : 24|1@0+ (1,0) [0|1] ""  ELL,ELR,ERL,ERR,KHD,N3P,NAG,NAP,NCL,NCP,NPR,NSP,NVO,PLG,RSH,RSL,RSR,SGW
 SG_ Node_17 : 25|1@0+ (1,0) [0|1] ""  ELL,ELR,ERL,ERR,KHD,N3P,NAG,NAP,NCL,NCP,NPR,NSP,NVO,PLG,RSH,RSL,RSR,SGW
 SG_ Node_18 : 26|1@0+ (1,0) [0|1] ""  ELL,ELR,ERL,ERR,KHD,N3P,NAG,NAP,NCL,NCP,NPR,NSP,NVO,PLG,RSH,RSL,RSR,SGW
 SG_ Node_19 : 27|1@0+ (1,0) [0|1] ""  ELL,ELR,ERL,ERR,KHD,N3P,NAG,NAP,NCL,NCP,NPR,NSP,NVO,PLG,RSH,RSL,RSR,SGW
 SG_ Node_20 : 28|1@0+ (1,0) [0|1] ""  ELL,ELR,ERL,ERR,KHD,N3P,NAG,NAP,NCL,NCP,NPR,NSP,NVO,PLG,RSH,RSL,RSR,SGW
 SG_ Node_21 : 29|1@0+ (1,0) [0|1] ""  ELL,ELR,ERL,ERR,KHD,N3P,NAG,NAP,NCL,NCP,NPR,NSP,NVO,PLG,RSH,RSL,RSR,SGW
 SG_ Node_22 : 30|1@0+ (1,0) [0|1] ""  ELL,ELR,ERL,ERR,KHD,N3P,NAG,NAP,NCL,NCP,NPR,NSP,NVO,PLG,RSH,RSL,RSR,SGW
 SG_ Node_23 : 31|1@0+ (1,0) [0|1] ""  ELL,ELR,ERL,ERR,KHD,N3P,NAG,NAP,NCL,NCP,NPR,NSP,NVO,PLG,RSH,RSL,RSR,SGW
 SG_ Node_08 : 32|1@0+ (1,0) [0|1] ""  ELL,ELR,ERL,ERR,KHD,N3P,NAG,NAP,NCL,NCP,NPR,NSP,NVO,PLG,RSH,RSL,RSR,SGW
 SG_ Node_09 : 33|1@0+ (1,0) [0|1] ""  ELL,ELR,ERL,ERR,KHD,N3P,NAG,NAP,NCL,NCP,NPR,NSP,NVO,PLG,RSH,RSL,RSR,SGW
 SG_ Node_10 : 34|1@0+ (1,0) [0|1] ""  ELL,ELR,ERL,ERR,KHD,N3P,NAG,NAP,NCL,NCP,NPR,NSP,NVO,PLG,RSH,RSL,RSR,SGW
 SG_ Node_11 : 35|1@0+ (1,0) [0|1] ""  ELL,ELR,ERL,ERR,KHD,N3P,NAG,NAP,NCL,NCP,NPR,NSP,NVO,PLG,RSH,RSL,RSR,SGW
 SG_ Node_12 : 36|1@0+ (1,0) [0|1] ""  ELL,ELR,ERL,ERR,KHD,N3P,NAG,NAP,NCL,NCP,NPR,NSP,NVO,PLG,RSH,RSL,RSR,SGW
 SG_ Node_13 : 37|1@0+ (1,0) [0|1] ""  ELL,ELR,ERL,ERR,KHD,N3P,NAG,NAP,NCL,NCP,NPR,NSP,NVO,PLG,RSH,RSL,RSR,SGW
 SG_ Node_14 : 38|1@0+ (1,0) [0|1] ""  ELL,ELR,ERL,ERR,KHD,N3P,NAG,NAP,NCL,NCP,NPR,NSP,NVO,PLG,RSH,RSL,RSR,SGW
 SG_ Node_15 : 39|1@0+ (1,0) [0|1] ""  ELL,ELR,ERL,ERR,KHD,N3P,NAG,NAP,NCL,NCP,NPR,NSP,NVO,PLG,RSH,RSL,RSR,SGW
 SG_ Node_00 : 40|1@0+ (1,0) [0|1] ""  ELL,ELR,ERL,ERR,KHD,N3P,NAG,NAP,NCL,NCP,NPR,NSP,NVO,PLG,RSH,RSL,RSR,SGW
 SG_ Node_01 : 41|1@0+ (1,0) [0|1] ""  ELL,ELR,ERL,ERR,KHD,N3P,NAG,NAP,NCL,NCP,NPR,NSP,NVO,PLG,RSH,RSL,RSR,SGW
 SG_ Node_02 : 42|1@0+ (1,0) [0|1] ""  ELL,ELR,ERL,ERR,KHD,N3P,NAG,NAP,NCL,NCP,NPR,NSP,NVO,PLG,RSH,RSL,RSR,SGW
 SG_ Node_03 : 43|1@0+ (1,0) [0|1] ""  ELL,ELR,ERL,ERR,KHD,N3P,NAG,NAP,NCL,NCP,NPR,NSP,NVO,PLG,RSH,RSL,RSR,SGW
 SG_ Node_04 : 44|1@0+ (1,0) [0|1] ""  ELL,ELR,ERL,ERR,KHD,N3P,NAG,NAP,NCL,NCP,NPR,NSP,NVO,PLG,RSH,RSL,RSR,SGW
 SG_ Node_05 : 45|1@0+ (1,0) [0|1] ""  ELL,ELR,ERL,ERR,KHD,N3P,NAG,NAP,NCL,NCP,NPR,NSP,NVO,PLG,RSH,RSL,RSR,SGW
 SG_ Node_06 : 46|1@0+ (1,0) [0|1] ""  ELL,ELR,ERL,ERR,KHD,N3P,NAG,NAP,NCL,NCP,NPR,NSP,NVO,PLG,RSH,RSL,RSR,SGW
 SG_ Node_07 : 47|1@0+ (1,0) [0|1] ""  ELL,ELR,ERL,ERR,KHD,N3P,NAG,NAP,NCL,NCP,NPR,NSP,NVO,PLG,RSH,RSL,RSR,SGW

BO_ 1796 NWM_NVO: 2 NVO
 SG_ Zero_byte : 7|8@0+ (1,0) [0|0] ""  BCM
 SG_ SystemStatus : 9|2@0+ (1,0) [0|3] ""  BCM
 SG_ ActiveLoadSlave : 10|1@0+ (1,0) [0|1] ""  BCM
 SG_ EOL : 11|1@0+ (1,0) [0|1] ""  BCM
 SG_ GenericFailSts : 12|1@0+ (1,0) [0|1] ""  BCM
 SG_ CurrentFailSts : 13|1@0+ (1,0) [0|1] ""  BCM
 SG_ D_ES : 15|2@0+ (1,0) [0|3] ""  BCM

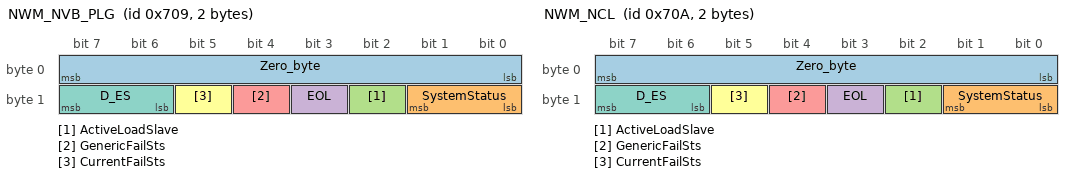
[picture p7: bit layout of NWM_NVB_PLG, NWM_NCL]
BO_ 1801 NWM_NVB_PLG: 2 PLG
 SG_ Zero_byte : 7|8@0+ (1,0) [0|0] ""  BCM
 SG_ SystemStatus : 9|2@0+ (1,0) [0|3] ""  BCM
 SG_ ActiveLoadSlave : 10|1@0+ (1,0) [0|1] ""  BCM
 SG_ EOL : 11|1@0+ (1,0) [0|1] ""  BCM
 SG_ GenericFailSts : 12|1@0+ (1,0) [0|1] ""  BCM
 SG_ CurrentFailSts : 13|1@0+ (1,0) [0|1] ""  BCM
 SG_ D_ES : 15|2@0+ (1,0) [0|3] ""  BCM

BO_ 1802 NWM_NCL: 2 NCL
 SG_ Zero_byte : 7|8@0+ (1,0) [0|0] ""  BCM
 SG_ SystemStatus : 9|2@0+ (1,0) [0|3] ""  BCM
 SG_ ActiveLoadSlave : 10|1@0+ (1,0) [0|1] ""  BCM
 SG_ EOL : 11|1@0+ (1,0) [0|1] ""  BCM
 SG_ GenericFailSts : 12|1@0+ (1,0) [0|1] ""  BCM
 SG_ CurrentFailSts : 13|1@0+ (1,0) [0|1] ""  BCM
 SG_ D_ES : 15|2@0+ (1,0) [0|3] ""  BCM

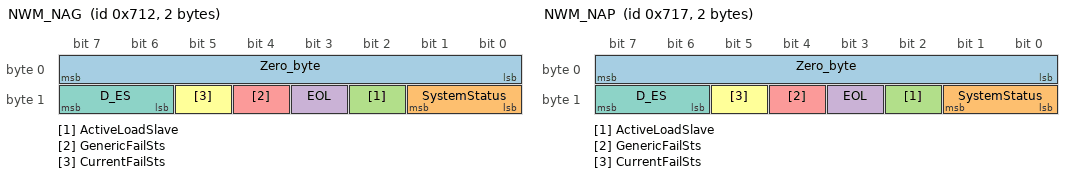
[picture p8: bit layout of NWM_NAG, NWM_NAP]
BO_ 1810 NWM_NAG: 2 NAG
 SG_ Zero_byte : 7|8@0+ (1,0) [0|0] ""  BCM
 SG_ SystemStatus : 9|2@0+ (1,0) [0|3] ""  BCM
 SG_ ActiveLoadSlave : 10|1@0+ (1,0) [0|1] ""  BCM
 SG_ EOL : 11|1@0+ (1,0) [0|1] ""  BCM
 SG_ GenericFailSts : 12|1@0+ (1,0) [0|1] ""  BCM
 SG_ CurrentFailSts : 13|1@0+ (1,0) [0|1] ""  BCM
 SG_ D_ES : 15|2@0+ (1,0) [0|3] ""  BCM

BO_ 1815 NWM_NAP: 2 NAP
 SG_ Zero_byte : 7|8@0+ (1,0) [0|0] ""  BCM
 SG_ SystemStatus : 9|2@0+ (1,0) [0|3] ""  BCM
 SG_ ActiveLoadSlave : 10|1@0+ (1,0) [0|1] ""  BCM
 SG_ EOL : 11|1@0+ (1,0) [0|1] ""  BCM
 SG_ GenericFailSts : 12|1@0+ (1,0) [0|1] ""  BCM
 SG_ CurrentFailSts : 13|1@0+ (1,0) [0|1] ""  BCM
 SG_ D_ES : 15|2@0+ (1,0) [0|3] ""  BCM

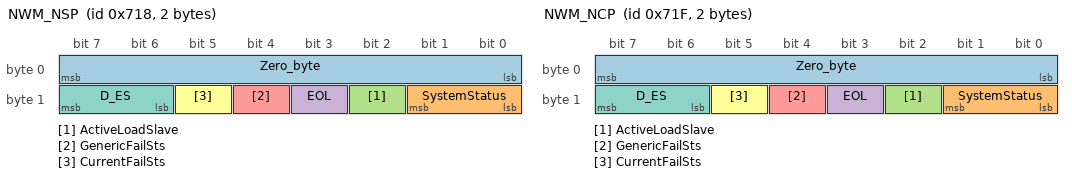
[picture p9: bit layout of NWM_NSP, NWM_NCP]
BO_ 1816 NWM_NSP: 2 NSP
 SG_ Zero_byte : 7|8@0+ (1,0) [0|0] ""  BCM
 SG_ SystemStatus : 9|2@0+ (1,0) [0|3] ""  BCM
 SG_ ActiveLoadSlave : 10|1@0+ (1,0) [0|1] ""  BCM
 SG_ EOL : 11|1@0+ (1,0) [0|1] ""  BCM
 SG_ GenericFailSts : 12|1@0+ (1,0) [0|1] ""  BCM
 SG_ CurrentFailSts : 13|1@0+ (1,0) [0|1] ""  BCM
 SG_ D_ES : 15|2@0+ (1,0) [0|3] ""  BCM

BO_ 1823 NWM_NCP: 2 NCP
 SG_ Zero_byte : 7|8@0+ (1,0) [0|0] ""  BCM
 SG_ SystemStatus : 9|2@0+ (1,0) [0|3] ""  BCM
 SG_ ActiveLoadSlave : 10|1@0+ (1,0) [0|1] ""  BCM
 SG_ EOL : 11|1@0+ (1,0) [0|1] ""  BCM
 SG_ GenericFailSts : 12|1@0+ (1,0) [0|1] ""  BCM
 SG_ CurrentFailSts : 13|1@0+ (1,0) [0|1] ""  BCM
 SG_ D_ES : 15|2@0+ (1,0) [0|3] ""  BCM

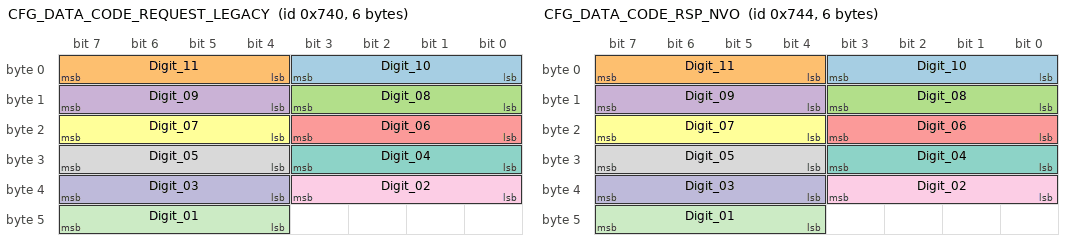
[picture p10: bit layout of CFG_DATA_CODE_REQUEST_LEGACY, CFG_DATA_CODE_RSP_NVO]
BO_ 1856 CFG_DATA_CODE_REQUEST_LEGACY: 6 BCM
 SG_ Digit_10 : 3|4@0+ (1,0) [0|15] ""  ELL,ELR,ERL,ERR,NSP,PLG,SGW
 SG_ Digit_11 : 7|4@0+ (1,0) [0|15] ""  ELL,ELR,ERL,ERR,NSP,PLG,SGW
 SG_ Digit_08 : 11|4@0+ (1,0) [0|15] ""  ELL,ELR,ERL,ERR,NSP,PLG,SGW
 SG_ Digit_09 : 15|4@0+ (1,0) [0|15] ""  ELL,ELR,ERL,ERR,NSP,PLG,SGW
 SG_ Digit_06 : 19|4@0+ (1,0) [0|15] ""  ELL,ELR,ERL,ERR,NSP,PLG,SGW
 SG_ Digit_07 : 23|4@0+ (1,0) [0|15] ""  ELL,ELR,ERL,ERR,NSP,PLG,SGW
 SG_ Digit_04 : 27|4@0+ (1,0) [0|15] ""  ELL,ELR,ERL,ERR,NSP,PLG,SGW
 SG_ Digit_05 : 31|4@0+ (1,0) [0|15] ""  ELL,ELR,ERL,ERR,NSP,PLG,SGW
 SG_ Digit_02 : 35|4@0+ (1,0) [0|15] ""  ELL,ELR,ERL,ERR,NSP,PLG,SGW
 SG_ Digit_03 : 39|4@0+ (1,0) [0|15] ""  ELL,ELR,ERL,ERR,NSP,PLG,SGW
 SG_ Digit_01 : 47|4@0+ (1,0) [0|15] ""  ELL,ELR,ERL,ERR,NSP,PLG,SGW

BO_ 1860 CFG_DATA_CODE_RSP_NVO: 6 NVO
 SG_ Digit_10 : 3|4@0+ (1,0) [0|15] ""  BCM
 SG_ Digit_11 : 7|4@0+ (1,0) [0|15] ""  BCM
 SG_ Digit_08 : 11|4@0+ (1,0) [0|15] ""  BCM
 SG_ Digit_09 : 15|4@0+ (1,0) [0|15] ""  BCM
 SG_ Digit_06 : 19|4@0+ (1,0) [0|15] ""  BCM
 SG_ Digit_07 : 23|4@0+ (1,0) [0|15] ""  BCM
 SG_ Digit_04 : 27|4@0+ (1,0) [0|15] ""  BCM
 SG_ Digit_05 : 31|4@0+ (1,0) [0|15] ""  BCM
 SG_ Digit_02 : 35|4@0+ (1,0) [0|15] ""  BCM
 SG_ Digit_03 : 39|4@0+ (1,0) [0|15] ""  BCM
 SG_ Digit_01 : 47|4@0+ (1,0) [0|15] ""  BCM

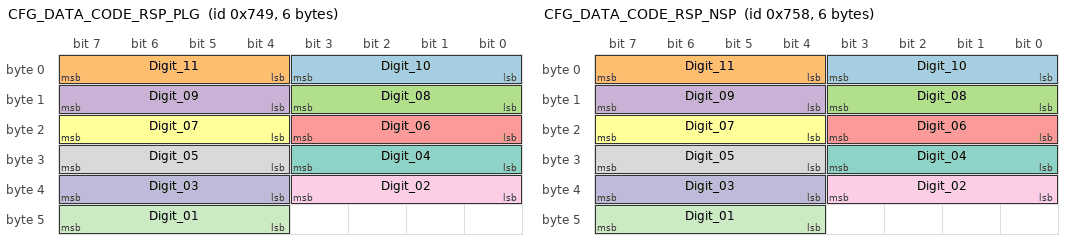
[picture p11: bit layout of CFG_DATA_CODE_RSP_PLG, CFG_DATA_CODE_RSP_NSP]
BO_ 1865 CFG_DATA_CODE_RSP_PLG: 6 PLG
 SG_ Digit_10 : 3|4@0+ (1,0) [0|9] ""  BCM
 SG_ Digit_11 : 7|4@0+ (1,0) [0|15] ""  BCM
 SG_ Digit_08 : 11|4@0+ (1,0) [0|15] ""  BCM
 SG_ Digit_09 : 15|4@0+ (1,0) [0|15] ""  BCM
 SG_ Digit_06 : 19|4@0+ (1,0) [0|15] ""  BCM
 SG_ Digit_07 : 23|4@0+ (1,0) [0|15] ""  BCM
 SG_ Digit_04 : 27|4@0+ (1,0) [0|15] ""  BCM
 SG_ Digit_05 : 31|4@0+ (1,0) [0|15] ""  BCM
 SG_ Digit_02 : 35|4@0+ (1,0) [0|15] ""  BCM
 SG_ Digit_03 : 39|4@0+ (1,0) [0|15] ""  BCM
 SG_ Digit_01 : 47|4@0+ (1,0) [0|15] ""  BCM

BO_ 1880 CFG_DATA_CODE_RSP_NSP: 6 NSP
 SG_ Digit_10 : 3|4@0+ (1,0) [0|15] ""  BCM
 SG_ Digit_11 : 7|4@0+ (1,0) [0|15] ""  BCM
 SG_ Digit_08 : 11|4@0+ (1,0) [0|15] ""  BCM
 SG_ Digit_09 : 15|4@0+ (1,0) [0|15] ""  BCM
 SG_ Digit_06 : 19|4@0+ (1,0) [0|15] ""  BCM
 SG_ Digit_07 : 23|4@0+ (1,0) [0|15] ""  BCM
 SG_ Digit_04 : 27|4@0+ (1,0) [0|15] ""  BCM
 SG_ Digit_05 : 31|4@0+ (1,0) [0|15] ""  BCM
 SG_ Digit_02 : 35|4@0+ (1,0) [0|15] ""  BCM
 SG_ Digit_03 : 39|4@0+ (1,0) [0|15] ""  BCM
 SG_ Digit_01 : 47|4@0+ (1,0) [0|15] ""  BCM

BO_ 2510948864 NCL_Debug1: 8 NCL
 SG_ ModAirTempFiltLft : 7|8@0- (1,0) [-128|127] "°C" Vector__XXX
 SG_ ModAirTempTargRrRgt : 15|8@0- (1,0) [-128|127] "°C" Vector__XXX
 SG_ ModAirTempFiltRgt : 23|8@0- (1,0) [-128|127] "°C" Vector__XXX
 SG_ ModAirTempFiltRrLft : 31|8@0- (1,0) [-128|127] "°C" Vector__XXX
 SG_ ModAirTempTargLft : 39|8@0- (1,0) [-128|127] "°C" Vector__XXX
 SG_ ModAirTempTargRrLft : 47|8@0- (1,0) [-128|127] "°C" Vector__XXX
 SG_ ModAirTempTargRgt : 55|8@0- (1,0) [-128|127] "°C" Vector__XXX
 SG_ ModAirTempFiltRrRgt : 63|8@0- (1,0) [-128|127] "°C" Vector__XXX

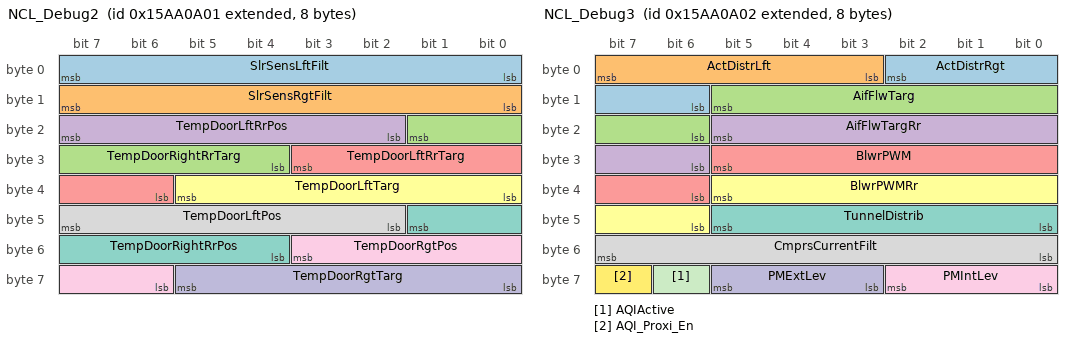
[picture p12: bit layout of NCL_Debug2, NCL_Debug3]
BO_ 2510948865 NCL_Debug2: 8 NCL
 SG_ SlrSensLftFilt : 7|8@0+ (4,0) [0|1020] "" Vector__XXX
 SG_ SlrSensRgtFilt : 15|8@0+ (4,0) [0|1020] "" Vector__XXX
 SG_ TempDoorRightRrTarg : 17|6@0+ (2,0) [0|126] "" Vector__XXX
 SG_ TempDoorLftRrPos : 23|6@0+ (2,0) [0|126] "" Vector__XXX
 SG_ TempDoorLftRrTarg : 27|6@0+ (2,0) [0|126] "" Vector__XXX
 SG_ TempDoorLftTarg : 37|6@0+ (2,0) [0|126] "" Vector__XXX
 SG_ TempDoorRightRrPos : 41|6@0+ (2,0) [0|126] "" Vector__XXX
 SG_ TempDoorLftPos : 47|6@0+ (2,0) [0|126] "" Vector__XXX
 SG_ TempDoorRgtPos : 51|6@0+ (2,0) [0|126] "" Vector__XXX
 SG_ TempDoorRgtTarg : 61|6@0+ (2,0) [0|126] "" Vector__XXX

BO_ 2510948866 NCL_Debug3: 8 NCL
 SG_ ActDistrRgt : 2|5@0+ (1,0) [0|31] "" Vector__XXX
 SG_ ActDistrLft : 7|5@0+ (1,0) [0|31] "" Vector__XXX
 SG_ AifFlwTarg : 13|8@0+ (2,0) [0|510] "m3/h" Vector__XXX
 SG_ AifFlwTargRr : 21|8@0+ (2,0) [0|510] "m3/h" Vector__XXX
 SG_ BlwrPWM : 29|8@0+ (1,0) [0|255] "" Vector__XXX
 SG_ BlwrPWMRr : 37|8@0+ (1,0) [0|255] "" Vector__XXX
 SG_ TunnelDistrib : 45|6@0+ (2,0) [0|126] "" Vector__XXX
 SG_ CmprsCurrentFilt : 55|8@0+ (4,0) [0|1020] "" Vector__XXX
 SG_ PMIntLev : 58|3@0+ (1,0) [0|7] "" Vector__XXX
 SG_ PMExtLev : 61|3@0+ (1,0) [0|7] "" Vector__XXX
 SG_ AQIActive : 62|1@0+ (1,0) [0|1] "" Vector__XXX
 SG_ AQI_Proxi_En : 63|1@0+ (1,0) [0|1] "" Vector__XXX

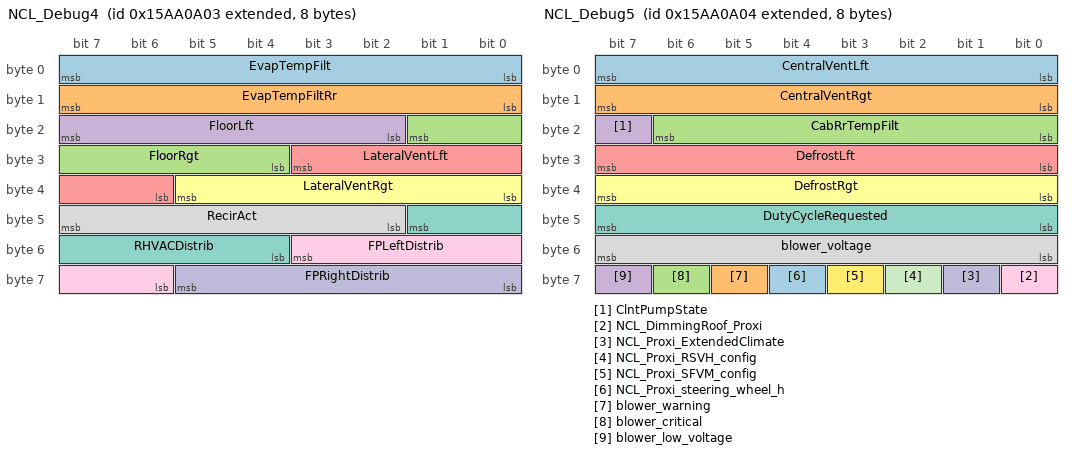
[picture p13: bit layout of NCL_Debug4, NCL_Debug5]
BO_ 2510948867 NCL_Debug4: 8 NCL
 SG_ EvapTempFilt : 7|8@0- (0.5,0) [-64|63.5] "°C" Vector__XXX
 SG_ EvapTempFiltRr : 15|8@0- (0.5,0) [-64|63.5] "°C" Vector__XXX
 SG_ FloorRgt : 17|6@0+ (2,0) [0|126] "" Vector__XXX
 SG_ FloorLft : 23|6@0+ (2,0) [0|126] "" Vector__XXX
 SG_ LateralVentLft : 27|6@0+ (2,0) [0|126] "" Vector__XXX
 SG_ LateralVentRgt : 37|6@0+ (2,0) [0|126] "" Vector__XXX
 SG_ RHVACDistrib : 41|6@0+ (2,0) [0|126] "" Vector__XXX
 SG_ RecirAct : 47|6@0+ (2,0) [0|126] "" Vector__XXX
 SG_ FPLeftDistrib : 51|6@0+ (2,0) [0|126] "" Vector__XXX
 SG_ FPRightDistrib : 61|6@0+ (2,0) [0|126] "" Vector__XXX

BO_ 2510948868 NCL_Debug5: 8 NCL
 SG_ CentralVentLft : 7|8@0+ (1,0) [0|255] "" Vector__XXX
 SG_ CentralVentRgt : 15|8@0+ (1,0) [0|255] "" Vector__XXX
 SG_ CabRrTempFilt : 22|7@0+ (1,0) [0|127] "°C" Vector__XXX
 SG_ ClntPumpState : 23|1@0+ (1,0) [0|1] "" Vector__XXX
 SG_ DefrostLft : 31|8@0+ (1,0) [0|255] "" Vector__XXX
 SG_ DefrostRgt : 39|8@0+ (1,0) [0|255] "" Vector__XXX
 SG_ DutyCycleRequested : 47|8@0+ (1,0) [0|255] "" Vector__XXX
 SG_ blower_voltage : 55|8@0+ (1,0) [0|255] "" Vector__XXX
 SG_ NCL_DimmingRoof_Proxi : 56|1@0+ (1,0) [0|1] "" Vector__XXX
 SG_ NCL_Proxi_ExtendedClimate : 57|1@0+ (1,0) [0|1] "" Vector__XXX
 SG_ NCL_Proxi_RSVH_config : 58|1@0+ (1,0) [0|1] "" Vector__XXX
 SG_ NCL_Proxi_SFVM_config : 59|1@0+ (1,0) [0|1] "" Vector__XXX
 SG_ NCL_Proxi_steering_wheel_h : 60|1@0+ (1,0) [0|1] "" Vector__XXX
 SG_ blower_warning : 61|1@0+ (1,0) [0|1] "" Vector__XXX
 SG_ blower_critical : 62|1@0+ (1,0) [0|1] "" Vector__XXX
 SG_ blower_low_voltage : 63|1@0+ (1,0) [0|1] "" Vector__XXX

BO_ 2510948869 NCL_Debug6: 8 NCL
 SG_ EvapTempTarget00 m0 : 7|16@0- (0.00390625,0) [-128|127] "°C" Vector__XXX
 SG_ EvapTempTarget01 m1 : 7|16@0- (0.00390625,0) [-128|127] "°C" Vector__XXX
 SG_ EvapTempTarget02 m2 : 7|16@0- (0.00390625,0) [-128|127] "°C" Vector__XXX
 SG_ CompState00 m0 : 23|8@0+ (1,0) [0|255] "" Vector__XXX
 SG_ CompState01 m1 : 23|8@0+ (1,0) [0|255] "" Vector__XXX
 SG_ CompState02 m2 : 23|8@0+ (1,0) [0|255] "" Vector__XXX
 SG_ BattVolt00 m0 : 31|8@0+ (0.1,0) [0|25.5] "" Vector__XXX
 SG_ BattVolt01 m1 : 31|8@0+ (0.1,0) [0|25.5] "" Vector__XXX
 SG_ BattVolt02 m2 : 31|8@0+ (0.1,0) [0|25.5] "" Vector__XXX
 SG_ RawRightWaterValve00 m0 : 39|10@0+ (1,0) [0|1023] "" Vector__XXX
 SG_ RawRightWaterValve01 m1 : 39|10@0+ (1,0) [0|1023] "" Vector__XXX
 SG_ blowerRr_rpm_fbck02 m2 : 39|8@0+ (1,0) [0|255] "rpm" Vector__XXX
 SG_ RawLeftWaterValve00 m0 : 45|10@0+ (1,0) [0|1023] "" Vector__XXX
 SG_ RawLeftWaterValve01 m1 : 45|10@0+ (1,0) [0|1023] "" Vector__XXX
 SG_ blower_rpm_fbck02 m2 : 47|8@0+ (1,0) [0|255] "rpm" Vector__XXX
 SG_ MMI_Temp_Count02 m2 : 51|4@0+ (1,0) [0|15] "count" Vector__XXX
 SG_ RawPowerModule00 m0 : 51|10@0+ (1,0) [0|1023] "" Vector__XXX
 SG_ RawPowerModule01 m1 : 51|10@0+ (1,0) [0|1023] "" Vector__XXX
 SG_ Roof_Present02 m2 : 52|1@0+ (1,0) [0|1] "" Vector__XXX
 SG_ EVDC_enabled02 m2 : 53|1@0+ (1,0) [0|1] "" Vector__XXX
 SG_ stop_and_start02 m2 : 54|1@0+ (1,0) [0|1] "" Vector__XXX
 SG_ driver_side02 m2 : 55|1@0+ (1,0) [0|1] "" Vector__XXX
 SG_ CarModel M : 57|2@0+ (1,0) [0|3] "" Vector__XXX
 SG_ MMI_buttons_type_2_count02 m2 : 60|3@0+ (1,0) [0|7] "" Vector__XXX
 SG_ MMI_buttons_type_1_count02 m2 : 63|3@0+ (1,0) [0|7] "" Vector__XXX

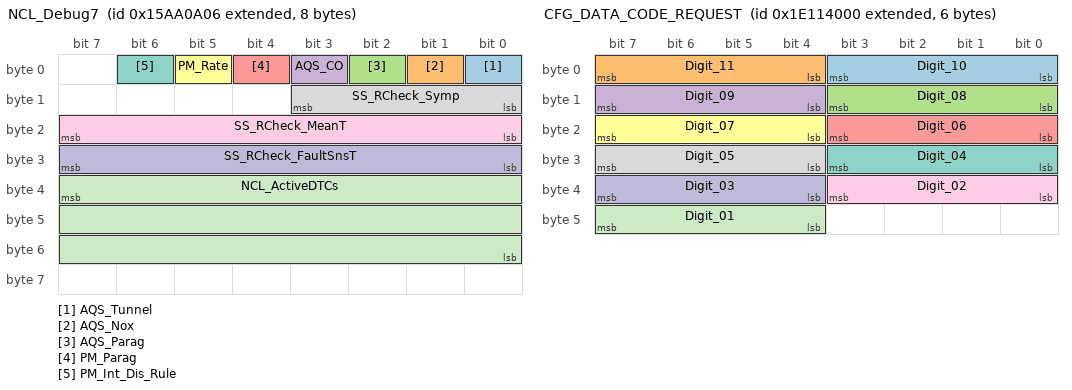
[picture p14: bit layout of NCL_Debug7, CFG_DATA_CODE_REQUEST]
BO_ 2510948870 NCL_Debug7: 8 NCL
 SG_ AQS_Tunnel : 0|1@0+ (1,0) [0|1] "" Vector__XXX
 SG_ AQS_Nox : 1|1@0+ (1,0) [0|1] "" Vector__XXX
 SG_ AQS_Parag : 2|1@0+ (1,0) [0|1] "" Vector__XXX
 SG_ AQS_CO : 3|1@0+ (1,0) [0|1] "" Vector__XXX
 SG_ PM_Parag : 4|1@0+ (1,0) [0|1] "" Vector__XXX
 SG_ PM_Rate : 5|1@0+ (1,0) [0|1] "" Vector__XXX
 SG_ PM_Int_Dis_Rule : 6|1@0+ (1,0) [0|1] "" Vector__XXX
 SG_ SS_RCheck_Symp : 11|4@0+ (1,0) [0|15] "" Vector__XXX
 SG_ SS_RCheck_MeanT : 23|8@0- (1,0) [-128|127] "" Vector__XXX
 SG_ SS_RCheck_FaultSnsT : 31|8@0- (1,0) [-128|127] "" Vector__XXX
 SG_ NCL_ActiveDTCs : 39|24@0+ (1,0) [0|16777215] "" Vector__XXX

BO_ 2510948871 NCL_Debug8: 8 NCL
 SG_ TPDU_NCL_Dbg_08 : 7|64@0+ (1,0) [0|1.84467440737096E+019] "" Vector__XXX

BO_ 2564425969 UDS_SGW_NCL_PhyReq_Data: 8 SGW
 SG_ UDS_SGW_NCL_PhyReq_Data : 7|64@0+ (1,0) [0|1.84467440737096E+019] ""  NCL

BO_ 2564426225 UDS_SGW_RCL_PhyReq_Data: 8 SGW
 SG_ UDS_SGW_RCL_PhyReq_Data : 7|64@0+ (1,0) [0|1.84467440737096E+019] ""  NCL

BO_ 2564430577 UDS_SGW_NAG_PhyReq_Data: 8 SGW
 SG_ UDS_SGW_NAG_PhysReq_Data : 7|64@0+ (1,0) [0|1.84467440737096E+019] ""  NAG

BO_ 2564444657 UDS_SGW_NPR_PhyReq_Data: 8 SGW
 SG_ UDS_SGW_NPR_PhyReq_Data : 7|64@0+ (1,0) [0|1.84467440737096E+019] ""  NPR

BO_ 2564447985 UDS_SGW_RSL_PhyReq_Data: 8 SGW
 SG_ UDS_SGW_RSL_PhyReq_Data : 7|64@0+ (1,0) [0|1.84467440737096E+019] ""  RSL

BO_ 2564448241 UDS_SGW_RSR_PhyReq_Data: 8 SGW
 SG_ UDS_SGW_RSR_PhyReq_Data : 7|64@0+ (1,0) [0|1.84467440737096E+019] ""  RSR

BO_ 2564449265 UDS_SGW_KHD_PhyReq_Data: 8 SGW
 SG_ UDS_SGW_KHD_PhysReq_Data : 7|64@0+ (1,0) [0|1.84467440737096E+019] ""  KHD

BO_ 2564453105 UDS_SGW_ELR_PhyReq_Data: 8 SGW
 SG_ UDS_SGW_ELR_PhysReq_Data : 7|64@0+ (1,0) [0|1.84467440737096E+019] ""  ELR

BO_ 2564453361 UDS_SGW_ELL_PhyReq_Data: 8 SGW
 SG_ UDS_SGW_ELL_PhysReq_Data : 7|64@0+ (1,0) [0|1.84467440737096E+019] ""  ELL

BO_ 2564455665 UDS_SGW_ERL_PhyReq_Data: 8 SGW
 SG_ UDS_SGW_ERL_PhysReq_Data : 7|64@0+ (1,0) [0|1.84467440737096E+019] ""  ERL

BO_ 2564455921 UDS_SGW_ERR_PhyReq_Data: 8 SGW
 SG_ UDS_SGW_ERR_PhysReq_Data : 7|64@0+ (1,0) [0|1.84467440737096E+019] ""  ERR

BO_ 2564458225 UDS_SGW_NSP_PhyReq_Data: 8 SGW
 SG_ UDS_SGW_NSP_PhyReq_Data : 7|64@0+ (1,0) [0|1.84467440737096E+019] ""  NSP

BO_ 2564459249 UDS_SGW_PLG_PhyReq_Data: 8 SGW
 SG_ UDS_SGW_PLG_PhyReq_Data : 7|64@0+ (1,0) [0|1.84467440737096E+019] ""  PLG

BO_ 2564460529 UDS_SGW_NVO_PhyReq_Data: 8 SGW
 SG_ UDS_SGW_NVO_PhyReq_Data : 7|64@0+ (1,0) [0|1.84467440737096E+019] ""  NVO

BO_ 2564463601 UDS_SGW_NAP_PhyReq_Data: 8 SGW
 SG_ UDS_SGW_NAP_PhyReq_Data : 7|64@0+ (1,0) [0|1.84467440737096E+019] ""  NAP

BO_ 2564481777 UDS_SGW_N3P_PhyReq_Data: 8 SGW
 SG_ UDS_SGW_N3P_PhysReq_Data : 7|64@0+ (1,0) [0|1.84467440737096E+019] ""  N3P

BO_ 2564482033 UDS_SGW_RSH_PhyReq_Data: 8 SGW
 SG_ UDS_SGW_RSH_PhyReq_Data : 7|64@0+ (1,0) [0|1.84467440737096E+019] ""  RSH

BO_ 2564485384 UDS_NCL_SGW_PhyRes_Data: 8 NCL
 SG_ UDS_NCL_SGW_PhyRes_Data : 7|64@0+ (1,0) [0|1.84467440737096E+019] ""  SGW

BO_ 2564485385 UDS_RCL_SGW_PhyRes_Data: 8 NCL
 SG_ UDS_RCL_SGW_PhyRes_Data : 7|64@0+ (1,0) [0|1.84467440737096E+019] ""  SGW

BO_ 2564485402 UDS_NAG_SGW_PhyRes_Data: 8 NAG
 SG_ UDS_NAG_SGW_PhyRes_Data : 7|64@0+ (1,0) [0|1.84467440737096E+019] ""  SGW

BO_ 2564485457 UDS_NPR_SGW_PhyRes_Data: 8 NPR
 SG_ UDS_NPR_SGW_PhyRes_Data : 7|64@0+ (1,0) [0|1.84467440737096E+019] ""  SGW

BO_ 2564485470 UDS_RSL_SGW_PhyRes_Data: 8 RSL
 SG_ UDS_RSL_SGW_PhyRes_Data : 7|64@0+ (1,0) [0|1.84467440737096E+019] ""  SGW

BO_ 2564485471 UDS_RSR_SGW_PhyRes_Data: 8 RSR
 SG_ UDS_RSR_SGW_PhyRes_Data : 7|64@0+ (1,0) [0|1.84467440737096E+019] ""  SGW

BO_ 2564485475 UDS_KHD_SGW_PhyRes_Data: 8 KHD
 SG_ UDS_KHD_SGW_PhyRes_Data : 7|64@0+ (1,0) [0|1.84467440737096E+019] ""  SGW

BO_ 2564485490 UDS_ELR_SGW_PhyRes_Data: 8 ELR
 SG_ UDS_ELR_SGW_PhyRes_Data : 7|64@0+ (1,0) [0|1.84467440737096E+019] ""  SGW

BO_ 2564485491 UDS_ELL_SGW_PhyRes_Data: 8 ELL
 SG_ UDS_ELL_SGW_PhyRes_Data : 7|64@0+ (1,0) [0|1.84467440737096E+019] ""  SGW

BO_ 2564485500 UDS_ERL_SGW_PhyRes_Data: 8 ERL
 SG_ UDS_ERL_SGW_PhyRes_Data : 7|64@0+ (1,0) [0|1.84467440737096E+019] ""  SGW

BO_ 2564485501 UDS_ERR_SGW_PhyRes_Data: 8 ERR
 SG_ UDS_ERR_SGW_PhyRes_Data : 7|64@0+ (1,0) [0|1.84467440737096E+019] ""  SGW

BO_ 2564485510 UDS_NSP_SGW_PhyRes_Data: 8 NSP
 SG_ UDS_NSP_SGW_PhyRes_Data : 7|64@0+ (1,0) [0|1.84467440737096E+019] ""  SGW

BO_ 2564485514 UDS_PLG_SGW_PhyRes_Data: 8 PLG
 SG_ UDS_PLG_SGW_PhyRes_Data : 7|64@0+ (1,0) [0|1.84467440737096E+019] ""  SGW

BO_ 2564485519 UDS_NVO_SGW_PhyRes_Data: 8 NVO
 SG_ UDS_NVO_SGW_PhyRes_Data : 7|64@0+ (1,0) [0|1.84467440737096E+019] ""  SGW

BO_ 2564485531 UDS_NAP_SGW_PhyRes_Data: 8 NAP
 SG_ UDS_NAP_SGW_PhyRes_Data : 7|64@0+ (1,0) [0|1.84467440737096E+019] ""  SGW

BO_ 2564485602 UDS_N3P_SGW_PhyRes_Data_BH_CAN: 8 N3P
 SG_ UDS_N3P_SGW_PhyRes_Data : 7|64@0+ (1,0) [0|1.84467440737096E+019] ""  SGW

BO_ 2564485603 UDS_RSH_SGW_PhyRes_Data: 8 RSH
 SG_ UDS_RSH_SGW_PhyRes_Data : 7|64@0+ (1,0) [0|1.84467440737096E+019] ""  SGW

BO_ 2564554481 UDS_SGW_to_ALL_Func_Data: 8 SGW
 SG_ UDS_OBD_to_ALL_FunctionalRequest : 7|64@0+ (1,0) [0|1.84467440737096E+019] ""  ELL,ELR,ERL,ERR,KHD,N3P,NAG,NAP,NCL,NPR,NSP,NVO,PLG,RSH,RSL,RSR

BO_ 2651930624 CFG_DATA_CODE_REQUEST: 6 BCM
 SG_ Digit_10 : 3|4@0+ (1,0) [0|15] ""  NCL,NSP,NVO
 SG_ Digit_11 : 7|4@0+ (1,0) [0|15] ""  NCL,NSP,NVO
 SG_ Digit_08 : 11|4@0+ (1,0) [0|15] ""  NCL,NSP,NVO
 SG_ Digit_09 : 15|4@0+ (1,0) [0|15] ""  NCL,NSP,NVO
 SG_ Digit_06 : 19|4@0+ (1,0) [0|15] ""  NCL,NSP,NVO
 SG_ Digit_07 : 23|4@0+ (1,0) [0|15] ""  NCL,NSP,NVO
 SG_ Digit_04 : 27|4@0+ (1,0) [0|15] ""  NCL,NSP,NVO
 SG_ Digit_05 : 31|4@0+ (1,0) [0|15] ""  NCL,NSP,NVO
 SG_ Digit_02 : 35|4@0+ (1,0) [0|15] ""  NCL,NSP,NVO
 SG_ Digit_03 : 39|4@0+ (1,0) [0|15] ""  NCL,NSP,NVO
 SG_ Digit_01 : 47|4@0+ (1,0) [0|15] ""  NCL,NSP,NVO

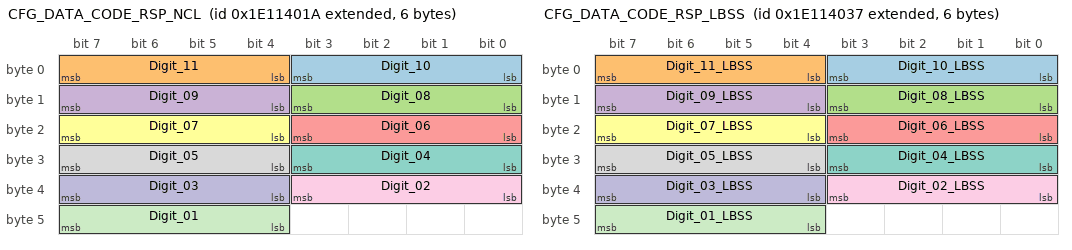
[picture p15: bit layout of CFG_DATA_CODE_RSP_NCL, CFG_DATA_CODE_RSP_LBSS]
BO_ 2651930650 CFG_DATA_CODE_RSP_NCL: 6 NCL
 SG_ Digit_10 : 3|4@0+ (1,0) [0|15] ""  BCM
 SG_ Digit_11 : 7|4@0+ (1,0) [0|15] ""  BCM
 SG_ Digit_08 : 11|4@0+ (1,0) [0|15] ""  BCM
 SG_ Digit_09 : 15|4@0+ (1,0) [0|15] ""  BCM
 SG_ Digit_06 : 19|4@0+ (1,0) [0|15] ""  BCM
 SG_ Digit_07 : 23|4@0+ (1,0) [0|15] ""  BCM
 SG_ Digit_04 : 27|4@0+ (1,0) [0|15] ""  BCM
 SG_ Digit_05 : 31|4@0+ (1,0) [0|15] ""  BCM
 SG_ Digit_02 : 35|4@0+ (1,0) [0|15] ""  BCM
 SG_ Digit_03 : 39|4@0+ (1,0) [0|15] ""  BCM
 SG_ Digit_01 : 47|4@0+ (1,0) [0|15] ""  BCM

BO_ 2651930679 CFG_DATA_CODE_RSP_LBSS: 6 SGW
 SG_ Digit_10_LBSS : 3|4@0+ (1,0) [0|15] ""  BCM
 SG_ Digit_11_LBSS : 7|4@0+ (1,0) [0|15] ""  BCM
 SG_ Digit_08_LBSS : 11|4@0+ (1,0) [0|15] ""  BCM
 SG_ Digit_09_LBSS : 15|4@0+ (1,0) [0|15] ""  BCM
 SG_ Digit_06_LBSS : 19|4@0+ (1,0) [0|15] ""  BCM
 SG_ Digit_07_LBSS : 23|4@0+ (1,0) [0|15] ""  BCM
 SG_ Digit_04_LBSS : 27|4@0+ (1,0) [0|15] ""  BCM
 SG_ Digit_05_LBSS : 31|4@0+ (1,0) [0|15] ""  BCM
 SG_ Digit_02_LBSS : 35|4@0+ (1,0) [0|15] ""  BCM
 SG_ Digit_03_LBSS : 39|4@0+ (1,0) [0|15] ""  BCM
 SG_ Digit_01_LBSS : 47|4@0+ (1,0) [0|15] ""  BCM

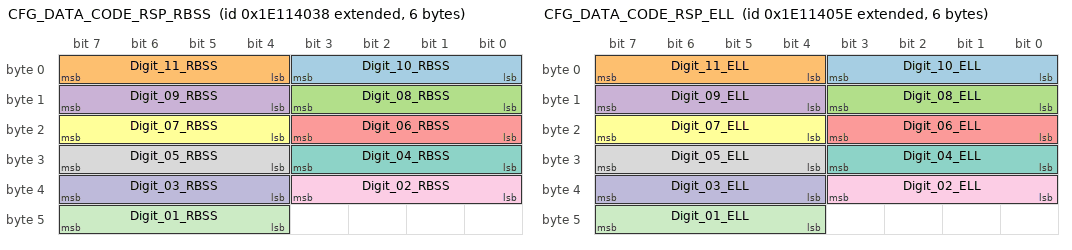
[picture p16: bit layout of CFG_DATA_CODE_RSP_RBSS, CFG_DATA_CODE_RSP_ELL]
BO_ 2651930680 CFG_DATA_CODE_RSP_RBSS: 6 SGW
 SG_ Digit_10_RBSS : 3|4@0+ (1,0) [0|15] ""  BCM
 SG_ Digit_11_RBSS : 7|4@0+ (1,0) [0|15] ""  BCM
 SG_ Digit_08_RBSS : 11|4@0+ (1,0) [0|15] ""  BCM
 SG_ Digit_09_RBSS : 15|4@0+ (1,0) [0|15] ""  BCM
 SG_ Digit_06_RBSS : 19|4@0+ (1,0) [0|15] ""  BCM
 SG_ Digit_07_RBSS : 23|4@0+ (1,0) [0|15] ""  BCM
 SG_ Digit_04_RBSS : 27|4@0+ (1,0) [0|15] ""  BCM
 SG_ Digit_05_RBSS : 31|4@0+ (1,0) [0|15] ""  BCM
 SG_ Digit_02_RBSS : 35|4@0+ (1,0) [0|15] ""  BCM
 SG_ Digit_03_RBSS : 39|4@0+ (1,0) [0|15] ""  BCM
 SG_ Digit_01_RBSS : 47|4@0+ (1,0) [0|15] ""  BCM

BO_ 2651930718 CFG_DATA_CODE_RSP_ELL: 6 ELL
 SG_ Digit_10_ELL : 3|4@0+ (1,0) [0|15] ""  BCM
 SG_ Digit_11_ELL : 7|4@0+ (1,0) [0|15] ""  BCM
 SG_ Digit_08_ELL : 11|4@0+ (1,0) [0|15] ""  BCM
 SG_ Digit_09_ELL : 15|4@0+ (1,0) [0|15] ""  BCM
 SG_ Digit_06_ELL : 19|4@0+ (1,0) [0|15] ""  BCM
 SG_ Digit_07_ELL : 23|4@0+ (1,0) [0|15] ""  BCM
 SG_ Digit_04_ELL : 27|4@0+ (1,0) [0|15] ""  BCM
 SG_ Digit_05_ELL : 31|4@0+ (1,0) [0|15] ""  BCM
 SG_ Digit_02_ELL : 35|4@0+ (1,0) [0|15] ""  BCM
 SG_ Digit_03_ELL : 39|4@0+ (1,0) [0|15] ""  BCM
 SG_ Digit_01_ELL : 47|4@0+ (1,0) [0|15] ""  BCM

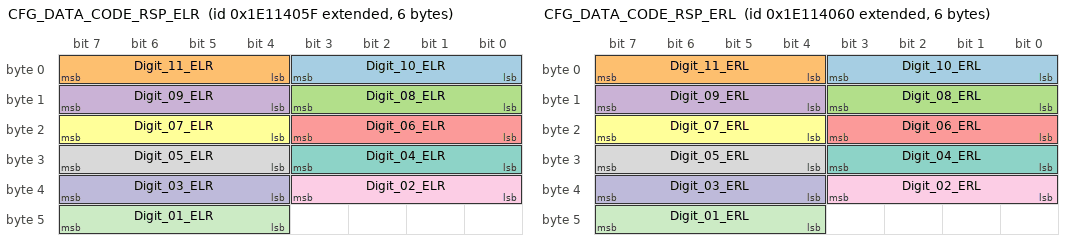
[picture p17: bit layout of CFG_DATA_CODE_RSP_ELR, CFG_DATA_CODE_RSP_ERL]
BO_ 2651930719 CFG_DATA_CODE_RSP_ELR: 6 ELR
 SG_ Digit_10_ELR : 3|4@0+ (1,0) [0|15] ""  BCM
 SG_ Digit_11_ELR : 7|4@0+ (1,0) [0|15] ""  BCM
 SG_ Digit_08_ELR : 11|4@0+ (1,0) [0|15] ""  BCM
 SG_ Digit_09_ELR : 15|4@0+ (1,0) [0|15] ""  BCM
 SG_ Digit_06_ELR : 19|4@0+ (1,0) [0|9] ""  BCM
 SG_ Digit_07_ELR : 23|4@0+ (1,0) [0|15] ""  BCM
 SG_ Digit_04_ELR : 27|4@0+ (1,0) [0|15] ""  BCM
 SG_ Digit_05_ELR : 31|4@0+ (1,0) [0|15] ""  BCM
 SG_ Digit_02_ELR : 35|4@0+ (1,0) [0|15] ""  BCM
 SG_ Digit_03_ELR : 39|4@0+ (1,0) [0|15] ""  BCM
 SG_ Digit_01_ELR : 47|4@0+ (1,0) [0|15] ""  BCM

BO_ 2651930720 CFG_DATA_CODE_RSP_ERL: 6 ERL
 SG_ Digit_10_ERL : 3|4@0+ (1,0) [0|15] ""  BCM
 SG_ Digit_11_ERL : 7|4@0+ (1,0) [0|15] ""  BCM
 SG_ Digit_08_ERL : 11|4@0+ (1,0) [0|15] ""  BCM
 SG_ Digit_09_ERL : 15|4@0+ (1,0) [0|15] ""  BCM
 SG_ Digit_06_ERL : 19|4@0+ (1,0) [0|15] ""  BCM
 SG_ Digit_07_ERL : 23|4@0+ (1,0) [0|15] ""  BCM
 SG_ Digit_04_ERL : 27|4@0+ (1,0) [0|15] ""  BCM
 SG_ Digit_05_ERL : 31|4@0+ (1,0) [0|15] ""  BCM
 SG_ Digit_02_ERL : 35|4@0+ (1,0) [0|15] ""  BCM
 SG_ Digit_03_ERL : 39|4@0+ (1,0) [0|15] ""  BCM
 SG_ Digit_01_ERL : 47|4@0+ (1,0) [0|15] ""  BCM

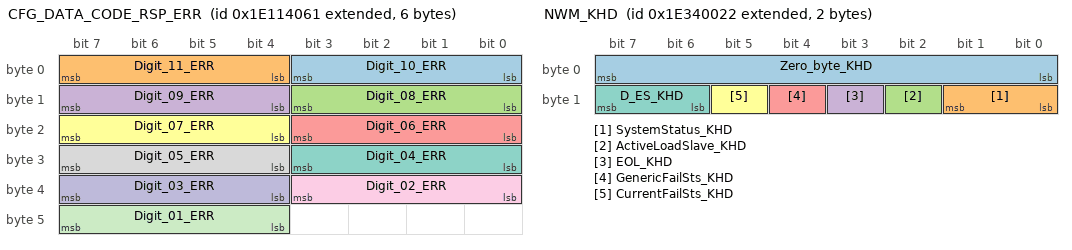
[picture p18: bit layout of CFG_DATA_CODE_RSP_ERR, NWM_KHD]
BO_ 2651930721 CFG_DATA_CODE_RSP_ERR: 6 ERR
 SG_ Digit_10_ERR : 3|4@0+ (1,0) [0|15] ""  BCM
 SG_ Digit_11_ERR : 7|4@0+ (1,0) [0|15] ""  BCM
 SG_ Digit_08_ERR : 11|4@0+ (1,0) [0|15] ""  BCM
 SG_ Digit_09_ERR : 15|4@0+ (1,0) [0|15] ""  BCM
 SG_ Digit_06_ERR : 19|4@0+ (1,0) [0|15] ""  BCM
 SG_ Digit_07_ERR : 23|4@0+ (1,0) [0|15] ""  BCM
 SG_ Digit_04_ERR : 27|4@0+ (1,0) [0|15] ""  BCM
 SG_ Digit_05_ERR : 31|4@0+ (1,0) [0|15] ""  BCM
 SG_ Digit_02_ERR : 35|4@0+ (1,0) [0|15] ""  BCM
 SG_ Digit_03_ERR : 39|4@0+ (1,0) [0|15] ""  BCM
 SG_ Digit_01_ERR : 47|4@0+ (1,0) [0|15] ""  BCM

BO_ 2654208034 NWM_KHD: 2 KHD
 SG_ Zero_byte_KHD : 7|8@0+ (1,0) [0|0] ""  BCM
 SG_ SystemStatus_KHD : 9|2@0+ (1,0) [0|3] ""  BCM
 SG_ ActiveLoadSlave_KHD : 10|1@0+ (1,0) [0|1] ""  BCM
 SG_ EOL_KHD : 11|1@0+ (1,0) [0|1] ""  BCM
 SG_ GenericFailSts_KHD : 12|1@0+ (1,0) [0|1] ""  BCM
 SG_ CurrentFailSts_KHD : 13|1@0+ (1,0) [0|1] ""  BCM
 SG_ D_ES_KHD : 15|2@0+ (1,0) [0|3] ""  BCM

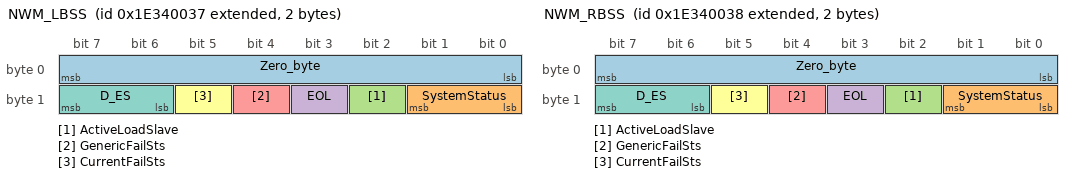
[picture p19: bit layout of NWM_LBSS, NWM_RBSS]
BO_ 2654208055 NWM_LBSS: 2 SGW
 SG_ Zero_byte : 7|8@0+ (1,0) [0|0] ""  BCM
 SG_ SystemStatus : 9|2@0+ (1,0) [0|3] ""  BCM
 SG_ ActiveLoadSlave : 10|1@0+ (1,0) [0|1] ""  BCM
 SG_ EOL : 11|1@0+ (1,0) [0|1] ""  BCM
 SG_ GenericFailSts : 12|1@0+ (1,0) [0|1] ""  BCM
 SG_ CurrentFailSts : 13|1@0+ (1,0) [0|1] ""  BCM
 SG_ D_ES : 15|2@0+ (1,0) [0|3] ""  BCM

BO_ 2654208056 NWM_RBSS: 2 SGW
 SG_ Zero_byte : 7|8@0+ (1,0) [0|0] ""  BCM
 SG_ SystemStatus : 9|2@0+ (1,0) [0|3] ""  BCM
 SG_ ActiveLoadSlave : 10|1@0+ (1,0) [0|1] ""  BCM
 SG_ EOL : 11|1@0+ (1,0) [0|1] ""  BCM
 SG_ GenericFailSts : 12|1@0+ (1,0) [0|1] ""  BCM
 SG_ CurrentFailSts : 13|1@0+ (1,0) [0|1] ""  BCM
 SG_ D_ES : 15|2@0+ (1,0) [0|3] ""  BCM

BO_ 2654208081 NWM_RSL: 2 RSL
 SG_ Zero_byte_RSL : 7|8@0+ (1,0) [0|0] ""  BCM
 SG_ SystemStatus_RSL : 9|2@0+ (1,0) [0|3] ""  BCM
 SG_ ActiveLoadSlave_RSL : 10|1@0+ (1,0) [0|1] ""  BCM
 SG_ EOL_RSL : 11|1@0+ (1,0) [0|1] ""  BCM
 SG_ GenericFailSts_RSL : 12|1@0+ (1,0) [0|1] ""  BCM
 SG_ CurrentFailSts_RSL : 13|1@0+ (1,0) [0|1] ""  BCM
 SG_ D_ES_RSL : 15|2@0+ (1,0) [0|3] ""  BCM

BO_ 2654208082 NWM_RSR: 2 RSR
 SG_ Zero_byte_RSR : 7|8@0+ (1,0) [0|0] ""  BCM
 SG_ SystemStatus_RSR : 9|2@0+ (1,0) [0|3] ""  BCM
 SG_ ActiveLoadSlave_RSR : 10|1@0+ (1,0) [0|1] ""  BCM
 SG_ EOL_RSR : 11|1@0+ (1,0) [0|1] ""  BCM
 SG_ GenericFailSts_RSR : 12|1@0+ (1,0) [0|1] ""  BCM
 SG_ CurrentFailSts_RSR : 13|1@0+ (1,0) [0|1] ""  BCM
 SG_ D_ES_RSR : 15|2@0+ (1,0) [0|3] ""  BCM

BO_ 2654208094 NWM_ELL: 2 ELL
 SG_ Zero_byte_ELL : 7|8@0+ (1,0) [0|0] ""  BCM
 SG_ SystemStatus_ELL : 9|2@0+ (1,0) [0|3] ""  BCM
 SG_ ActiveLoadSlave_ELL : 10|1@0+ (1,0) [0|1] ""  BCM
 SG_ EOL_ELL : 11|1@0+ (1,0) [0|1] ""  BCM
 SG_ GenericFailSts_ELL : 12|1@0+ (1,0) [0|1] ""  BCM
 SG_ CurrentFailSts_ELL : 13|1@0+ (1,0) [0|1] ""  BCM
 SG_ D_ES_ELL : 15|2@0+ (1,0) [0|3] ""  BCM

BO_ 2654208095 NWM_ELR: 2 ELR
 SG_ Zero_byte_ELR : 7|8@0+ (1,0) [0|0] ""  BCM
 SG_ SystemStatus_ELR : 9|2@0+ (1,0) [0|3] ""  BCM
 SG_ ActiveLoadSlave_ELR : 10|1@0+ (1,0) [0|1] ""  BCM
 SG_ EOL_ELR : 11|1@0+ (1,0) [0|1] ""  BCM
 SG_ GenericFailSts_ELR : 12|1@0+ (1,0) [0|1] ""  BCM
 SG_ CurrentFailSts_ELR : 13|1@0+ (1,0) [0|1] ""  BCM
 SG_ D_ES_ELR : 15|2@0+ (1,0) [0|3] ""  BCM

BO_ 2654208096 NWM_ERL: 2 ERL
 SG_ Zero_byte_ERL : 7|8@0+ (1,0) [0|0] ""  BCM
 SG_ SystemStatus_ERL : 9|2@0+ (1,0) [0|3] ""  BCM
 SG_ ActiveLoadSlave_ERL : 10|1@0+ (1,0) [0|1] ""  BCM
 SG_ EOL_ERL : 11|1@0+ (1,0) [0|1] ""  BCM
 SG_ GenericFailSts_ERL : 12|1@0+ (1,0) [0|1] ""  BCM
 SG_ CurrentFailSts_ERL : 13|1@0+ (1,0) [0|1] ""  BCM
 SG_ D_ES_ERL : 15|2@0+ (1,0) [0|3] ""  BCM

BO_ 2654208097 NWM_ERR: 2 ERR
 SG_ Zero_byte_ERR : 7|8@0+ (1,0) [0|0] ""  BCM
 SG_ SystemStatus_ERR : 9|2@0+ (1,0) [0|3] ""  BCM
 SG_ ActiveLoadSlave_ERR : 10|1@0+ (1,0) [0|1] ""  BCM
 SG_ EOL_ERR : 11|1@0+ (1,0) [0|1] ""  BCM
 SG_ GenericFailSts_ERR : 12|1@0+ (1,0) [0|1] ""  BCM
 SG_ CurrentFailSts_ERR : 13|1@0+ (1,0) [0|1] ""  BCM
 SG_ D_ES_ERR : 15|2@0+ (1,0) [0|3] ""  BCM

BO_ 2654208120 NWM_NPR: 2 NPR
 SG_ Zero_byte_NPR : 7|8@0+ (1,0) [0|0] ""  BCM
 SG_ SystemStatus_NPR : 9|2@0+ (1,0) [0|3] ""  BCM
 SG_ ActiveLoadSlave_NPR : 10|1@0+ (1,0) [0|1] ""  BCM
 SG_ EOL_NPR : 11|1@0+ (1,0) [0|1] ""  BCM
 SG_ GenericFailSts_NPR : 12|1@0+ (1,0) [0|1] ""  BCM
 SG_ CurrentFailSts_NPR : 13|1@0+ (1,0) [0|1] ""  BCM
 SG_ D_ES_NPR : 15|2@0+ (1,0) [0|3] ""  BCM

BO_ 2654208121 NWM_N3P: 2 N3P
 SG_ Zero_byte_N3P : 7|8@0+ (1,0) [0|0] ""  BCM
 SG_ SystemStatus_N3P : 9|2@0+ (1,0) [0|3] ""  BCM
 SG_ ActiveLoadSlave_N3P : 10|1@0+ (1,0) [0|1] ""  BCM
 SG_ EOL_N3P : 11|1@0+ (1,0) [0|1] ""  BCM
 SG_ GenericFailSts_N3P : 12|1@0+ (1,0) [0|1] ""  BCM
 SG_ CurrentFailSts_N3P : 13|1@0+ (1,0) [0|1] ""  BCM
 SG_ D_ES_N3P : 15|2@0+ (1,0) [0|3] ""  BCM

BO_ 2654208122 NWM_RSH: 2 RSH
 SG_ Zero_byte_RSH : 7|8@0+ (1,0) [0|0] ""  BCM
 SG_ SystemStatus_RSH : 9|2@0+ (1,0) [0|3] ""  BCM
 SG_ ActiveLoadSlave_RSH : 10|1@0+ (1,0) [0|1] ""  BCM
 SG_ EOL_RSH : 11|1@0+ (1,0) [0|1] ""  BCM
 SG_ GenericFailSts_RSH : 12|1@0+ (1,0) [0|1] ""  BCM
 SG_ CurrentFailSts_RSH : 13|1@0+ (1,0) [0|1] ""  BCM
 SG_ D_ES_RSH : 15|2@0+ (1,0) [0|3] ""  BCM

CM_ SG_ 1441 BatteryDisconnectionWarning "signal used to inform the driver to don't disconnect the Battery";
CM_ SG_ 1441 EngineSts "This signal indicates the engine state.";
CM_ SG_ 1441 StopStartSts "Engine restart: active 80 mSec before restart, 3 seconds after engine ON";
CM_ SG_ 1450 CentralVent "HMI: FOCUS represents the CLOSED position while DIFFUSE is the OPENED position. ";
CM_ BO_ 1464 "{For Dlc_SnaxV2: Size = 1}";
CM_ BO_ 1465 "{For Dlc_SnaxV2: Size = 1}";
CM_ SG_ 1485 MILrequest "request mil lamp";
CM_ SG_ 1696 Hour2 "BCD CODED 
Hour always in 24 format";
CM_ SG_ 1696 Hour1 "BCD CODED 
Hour always in 24 format";
CM_ SG_ 1696 Minute2 "BCD CODED";
CM_ SG_ 1696 Minute1 "BCD CODED";
CM_ SG_ 1696 Day2 "BCD CODED";
CM_ SG_ 1696 Day1 "BCD CODED";
CM_ SG_ 1696 Month2 "BCD CODED";
CM_ SG_ 1696 Month1 "BCD CODED";
CM_ SG_ 1696 Year2 "BCD CODED";
CM_ SG_ 1696 Year1 "BCD CODED";
CM_ SG_ 1696 Year4 "BCD CODED";
CM_ SG_ 1696 Year3 "BCD CODED";
CM_ SG_ 1728 BatteryType "PROXI byte 87, bit 0-3";
CM_ SG_ 1752 IntErr_ThmDisconnect "Failure of temp sensors";
CM_ SG_ 1752 IntErr_CoilDisconnect "Charging coil has been disconnected from main board; Error=[1]";
CM_ SG_ 1752 IntErr_CoilOverTemp "WCPM has Overheated;  Error=[1]";
CM_ SG_ 1752 IntErr_I2C_CommFault "Communication failure on internal I2C bus;  Error=[1]";
CM_ SG_ 1752 IntErr_Eeprom_failure "Failed to access the Memory";
CM_ SG_ 1752 IntErr_Reflash_aborted "Failure during reflashing (CRC error)";
CM_ SG_ 1764 LDWWarningType "{For F175: Startup/Default = 1}";
CM_ SG_ 1764 LDWAssistType "{For F175: Startup/Default = 1}";
CM_ SG_ 1767 HourMode "Not present in 937";
CM_ SG_ 1767 BuzzerVolumeWarning "Not present in 937";
CM_ SG_ 1767 SpeedThreshold "Not present in 937";
CM_ SG_ 1767 DriverDoorUnlockEnable "Not present in 937";
CM_ SG_ 1767 SpeedLockDoorEnable "Not present in 937";
CM_ SG_ 1767 ExternalLightSensorLevel "Bit position 26-25 for FIAT 07325";
CM_ SG_ 1767 SpeedThresholdEnable "Bit position 24 for FIAT 07325";
CM_ SG_ 1792 Node_09 "NVB and PLG are mutually exclusive";
CM_ SG_ 1792 Node_11 "NCA and NCR are mutually exclusive";
CM_ SG_ 1792 Node_14 "NIM and HVB are mutually exclusive";
CM_ SG_ 1860 Digit_10 "BCD CODED";
CM_ SG_ 1860 Digit_11 "(MSB) BCD CODED";
CM_ SG_ 1860 Digit_08 "BCD CODED";
CM_ SG_ 1860 Digit_09 "BCD CODED";
CM_ SG_ 1860 Digit_06 "BCD CODED";
CM_ SG_ 1860 Digit_07 "BCD CODED";
CM_ SG_ 1860 Digit_04 "BCD CODED";
CM_ SG_ 1860 Digit_05 "BCD CODED";
CM_ SG_ 1860 Digit_02 "BCD CODED";
CM_ SG_ 1860 Digit_03 "BCD CODED";
CM_ SG_ 1860 Digit_01 "(LSB) BCD CODED";
CM_ SG_ 1865 Digit_10 "BCD CODED";
CM_ SG_ 1865 Digit_11 "(MSB) BCD CODED";
CM_ SG_ 1865 Digit_08 "BCD CODED";
CM_ SG_ 1865 Digit_09 "BCD CODED";
CM_ SG_ 1865 Digit_06 "BCD CODED";
CM_ SG_ 1865 Digit_07 "BCD CODED";
CM_ SG_ 1865 Digit_04 "BCD CODED";
CM_ SG_ 1865 Digit_05 "BCD CODED";
CM_ SG_ 1865 Digit_02 "BCD CODED";
CM_ SG_ 1865 Digit_03 "BCD CODED";
CM_ SG_ 1865 Digit_01 "(LSB) BCD CODED";
CM_ SG_ 1880 Digit_10 "BCD CODED";
CM_ SG_ 1880 Digit_11 "(MSB) BCD CODED";
CM_ SG_ 1880 Digit_08 "BCD CODED";
CM_ SG_ 1880 Digit_09 "BCD CODED";
CM_ SG_ 1880 Digit_06 "BCD CODED";
CM_ SG_ 1880 Digit_07 "BCD CODED";
CM_ SG_ 1880 Digit_04 "BCD CODED";
CM_ SG_ 1880 Digit_05 "BCD CODED";
CM_ SG_ 1880 Digit_02 "BCD CODED";
CM_ SG_ 1880 Digit_03 "BCD CODED";
CM_ SG_ 1880 Digit_01 "(LSB) BCD CODED";
CM_ BO_ 2510948867 "in F173 project NOT used for ECU CAN ID limitation";
CM_ BO_ 2510948868 "in F173 project NOT used for ECU CAN ID limitation";
CM_ SG_ 2510948868 blower_voltage "the blower voltage feedback";
CM_ BO_ 2510948869 "in F173 project NOT used for ECU CAN ID limitation";
CM_ SG_ 2510948869 blowerRr_rpm_fbck02 "the blower rpm command";
CM_ SG_ 2510948869 blower_rpm_fbck02 "the blower rpm feedback";
CM_ BO_ 2510948870 "in F173 project NOT used for ECU CAN ID limitation";
CM_ BO_ 2510948871 "in F173 project NOT used for ECU CAN ID limitation";
CM_ SG_ 2651930650 Digit_10 "BCD CODED";
CM_ SG_ 2651930650 Digit_11 "(MSB) BCD CODED";
CM_ SG_ 2651930650 Digit_08 "BCD CODED";
CM_ SG_ 2651930650 Digit_09 "BCD CODED";
CM_ SG_ 2651930650 Digit_06 "BCD CODED";
CM_ SG_ 2651930650 Digit_07 "BCD CODED";
CM_ SG_ 2651930650 Digit_04 "BCD CODED";
CM_ SG_ 2651930650 Digit_05 "BCD CODED";
CM_ SG_ 2651930650 Digit_02 "BCD CODED";
CM_ SG_ 2651930650 Digit_03 "BCD CODED";
CM_ SG_ 2651930650 Digit_01 "(LSB) BCD CODED";
BA_DEF_ SG_  "GenSigSendType" ENUM  "NotUsed","OnWrite","OnWriteWithRepetition","OnChange","OnChangeWithRepetition","IfActive","IfActiveWithRepetition","NoSigSendType";
BA_DEF_ SG_  "GenSigInactiveValue" INT 0 2147483647;
BA_DEF_ SG_  "GenSigStartValue" INT 0 2147483647;
BA_DEF_ BO_  "DiagState" ENUM  "No","Yes";
BA_DEF_ BO_  "GenMsgDelayTime" INT 0 65535;
BA_DEF_ BO_  "GenMsgCycleTimeFast" INT 0 65535;
BA_DEF_ BO_  "GenMsgStartDelayTime" INT 0 65535;
BA_DEF_ BO_  "GenMsgILSupport" ENUM  "No","Yes";
BA_DEF_ BO_  "GenMsgTimeoutTime" INT 0 10000;
BA_DEF_ BO_  "GenMsgSendType" ENUM  "Cyclic","NotUsed","NotUsed","NotUsed","NotUsed","NotUsed","NotUsed","NotUsed","NoMsgSendType";
BA_DEF_ BO_  "NmMessage" ENUM  "No","Yes";
BA_DEF_ BO_  "Type" ENUM  "P","C","PE","COC","PE_Cntrl","E","E_Cntrl","OC","S","BAF","DC","EM","MM","-";
BA_DEF_ BO_  "Period" INT 0 65535;
BA_DEF_ SG_  "EventTrans" ENUM  "Yes","No";
BA_DEF_ SG_  "Accuracy" STRING ;
BA_DEF_ SG_  "SignalAge" INT 0 100000;
BA_DEF_ SG_  "InitialValue" INT -65536 65535;
BA_DEF_ BO_  "DiagResponse" ENUM  "No","Yes";
BA_DEF_ BO_  "DiagRequest" ENUM  "No","Yes";
BA_DEF_ BO_  "GenMsgCycleTime" INT 0 10000;
BA_DEF_ SG_  "SystemSignalLongSymbol" STRING ;
BA_DEF_DEF_  "GenSigSendType" "NoSigSendType";
BA_DEF_DEF_  "GenSigInactiveValue" 0;
BA_DEF_DEF_  "GenSigStartValue" 0;
BA_DEF_DEF_  "DiagState" "No";
BA_DEF_DEF_  "GenMsgDelayTime" 0;
BA_DEF_DEF_  "GenMsgCycleTimeFast" 0;
BA_DEF_DEF_  "GenMsgStartDelayTime" 0;
BA_DEF_DEF_  "GenMsgILSupport" "No";
BA_DEF_DEF_  "GenMsgTimeoutTime" 0;
BA_DEF_DEF_  "GenMsgSendType" "NoMsgSendType";
BA_DEF_DEF_  "NmMessage" "No";
BA_DEF_DEF_  "Type" "-";
BA_DEF_DEF_  "Period" 0;
BA_DEF_DEF_  "EventTrans" "No";
BA_DEF_DEF_  "Accuracy" "";
BA_DEF_DEF_  "SignalAge" 0;
BA_DEF_DEF_  "InitialValue" 0;
BA_DEF_DEF_  "DiagResponse" "No";
BA_DEF_DEF_  "DiagRequest" "No";
BA_DEF_DEF_  "GenMsgCycleTime" 0;
BA_DEF_DEF_  "SystemSignalLongSymbol" "";
BA_ "Type" BO_ 1428 3;
BA_ "Period" BO_ 1428 100;
BA_ "GenMsgTimeoutTime" BO_ 1428 2500;
BA_ "GenMsgStartDelayTime" BO_ 1428 10;
BA_ "GenMsgSendType" BO_ 1428 0;
BA_ "GenMsgILSupport" BO_ 1428 1;
BA_ "GenMsgCycleTimeFast" BO_ 1428 100;
BA_ "GenMsgCycleTime" BO_ 1428 100;
BA_ "Type" BO_ 1429 3;
BA_ "Period" BO_ 1429 100;
BA_ "GenMsgTimeoutTime" BO_ 1429 2500;
BA_ "GenMsgStartDelayTime" BO_ 1429 10;
BA_ "GenMsgSendType" BO_ 1429 0;
BA_ "GenMsgILSupport" BO_ 1429 1;
BA_ "GenMsgCycleTimeFast" BO_ 1429 100;
BA_ "GenMsgCycleTime" BO_ 1429 100;
BA_ "Type" BO_ 1430 3;
BA_ "Period" BO_ 1430 100;
BA_ "GenMsgTimeoutTime" BO_ 1430 2500;
BA_ "GenMsgStartDelayTime" BO_ 1430 10;
BA_ "GenMsgSendType" BO_ 1430 0;
BA_ "GenMsgILSupport" BO_ 1430 1;
BA_ "GenMsgCycleTimeFast" BO_ 1430 100;
BA_ "GenMsgCycleTime" BO_ 1430 100;
BA_ "Type" BO_ 1431 3;
BA_ "Period" BO_ 1431 100;
BA_ "GenMsgTimeoutTime" BO_ 1431 2500;
BA_ "GenMsgStartDelayTime" BO_ 1431 10;
BA_ "GenMsgSendType" BO_ 1431 0;
BA_ "GenMsgILSupport" BO_ 1431 1;
BA_ "GenMsgCycleTimeFast" BO_ 1431 100;
BA_ "GenMsgCycleTime" BO_ 1431 100;
BA_ "Type" BO_ 1432 3;
BA_ "Period" BO_ 1432 100;
BA_ "GenMsgTimeoutTime" BO_ 1432 2500;
BA_ "GenMsgStartDelayTime" BO_ 1432 10;
BA_ "GenMsgSendType" BO_ 1432 0;
BA_ "GenMsgILSupport" BO_ 1432 1;
BA_ "GenMsgCycleTimeFast" BO_ 1432 100;
BA_ "GenMsgCycleTime" BO_ 1432 100;
BA_ "Type" BO_ 1436 3;
BA_ "Period" BO_ 1436 100;
BA_ "GenMsgTimeoutTime" BO_ 1436 2500;
BA_ "GenMsgStartDelayTime" BO_ 1436 10;
BA_ "GenMsgSendType" BO_ 1436 0;
BA_ "GenMsgILSupport" BO_ 1436 1;
BA_ "GenMsgCycleTime" BO_ 1436 100;
BA_ "Type" BO_ 1441 1;
BA_ "Period" BO_ 1441 50;
BA_ "GenMsgTimeoutTime" BO_ 1441 2500;
BA_ "GenMsgSendType" BO_ 1441 0;
BA_ "GenMsgILSupport" BO_ 1441 1;
BA_ "GenMsgCycleTime" BO_ 1441 50;
BA_ "Type" BO_ 1444 10;
BA_ "Period" BO_ 1444 500;
BA_ "GenMsgTimeoutTime" BO_ 1444 2500;
BA_ "GenMsgSendType" BO_ 1444 0;
BA_ "GenMsgILSupport" BO_ 1444 1;
BA_ "GenMsgCycleTimeFast" BO_ 1444 50;
BA_ "GenMsgCycleTime" BO_ 1444 500;
BA_ "Type" BO_ 1446 5;
BA_ "GenMsgTimeoutTime" BO_ 1446 2500;
BA_ "GenMsgILSupport" BO_ 1446 1;
BA_ "Type" BO_ 1447 5;
BA_ "GenMsgILSupport" BO_ 1447 1;
BA_ "Type" BO_ 1448 5;
BA_ "GenMsgTimeoutTime" BO_ 1448 2500;
BA_ "GenMsgILSupport" BO_ 1448 1;
BA_ "Type" BO_ 1449 10;
BA_ "Period" BO_ 1449 500;
BA_ "GenMsgTimeoutTime" BO_ 1449 2500;
BA_ "GenMsgSendType" BO_ 1449 0;
BA_ "GenMsgILSupport" BO_ 1449 1;
BA_ "GenMsgCycleTimeFast" BO_ 1449 50;
BA_ "GenMsgCycleTime" BO_ 1449 500;
BA_ "Type" BO_ 1450 3;
BA_ "Period" BO_ 1450 100;
BA_ "GenMsgTimeoutTime" BO_ 1450 2500;
BA_ "GenMsgSendType" BO_ 1450 0;
BA_ "GenMsgILSupport" BO_ 1450 1;
BA_ "GenMsgCycleTimeFast" BO_ 1450 100;
BA_ "GenMsgCycleTime" BO_ 1450 100;
BA_ "Type" BO_ 1451 5;
BA_ "GenMsgTimeoutTime" BO_ 1451 2500;
BA_ "GenMsgILSupport" BO_ 1451 1;
BA_ "Type" BO_ 1452 5;
BA_ "GenMsgTimeoutTime" BO_ 1452 2500;
BA_ "GenMsgILSupport" BO_ 1452 1;
BA_ "Type" BO_ 1454 5;
BA_ "GenMsgTimeoutTime" BO_ 1454 2500;
BA_ "GenMsgILSupport" BO_ 1454 1;
BA_ "Type" BO_ 1457 3;
BA_ "Period" BO_ 1457 100;
BA_ "GenMsgTimeoutTime" BO_ 1457 2500;
BA_ "GenMsgSendType" BO_ 1457 0;
BA_ "GenMsgILSupport" BO_ 1457 1;
BA_ "GenMsgCycleTimeFast" BO_ 1457 100;
BA_ "GenMsgCycleTime" BO_ 1457 100;
BA_ "Type" BO_ 1458 3;
BA_ "Period" BO_ 1458 100;
BA_ "GenMsgTimeoutTime" BO_ 1458 2500;
BA_ "GenMsgSendType" BO_ 1458 0;
BA_ "GenMsgILSupport" BO_ 1458 1;
BA_ "GenMsgCycleTimeFast" BO_ 1458 100;
BA_ "GenMsgCycleTime" BO_ 1458 100;
BA_ "Type" BO_ 1463 3;
BA_ "Period" BO_ 1463 100;
BA_ "GenMsgTimeoutTime" BO_ 1463 2500;
BA_ "GenMsgSendType" BO_ 1463 0;
BA_ "GenMsgILSupport" BO_ 1463 1;
BA_ "GenMsgCycleTimeFast" BO_ 1463 100;
BA_ "GenMsgCycleTime" BO_ 1463 100;
BA_ "Type" BO_ 1464 3;
BA_ "Period" BO_ 1464 100;
BA_ "GenMsgTimeoutTime" BO_ 1464 2500;
BA_ "GenMsgSendType" BO_ 1464 0;
BA_ "GenMsgILSupport" BO_ 1464 1;
BA_ "GenMsgCycleTimeFast" BO_ 1464 100;
BA_ "GenMsgCycleTime" BO_ 1464 100;
BA_ "Type" BO_ 1465 3;
BA_ "Period" BO_ 1465 100;
BA_ "GenMsgTimeoutTime" BO_ 1465 2500;
BA_ "GenMsgSendType" BO_ 1465 0;
BA_ "GenMsgILSupport" BO_ 1465 1;
BA_ "GenMsgCycleTimeFast" BO_ 1465 100;
BA_ "GenMsgCycleTime" BO_ 1465 100;
BA_ "Type" BO_ 1485 1;
BA_ "Period" BO_ 1485 500;
BA_ "GenMsgTimeoutTime" BO_ 1485 2500;
BA_ "GenMsgSendType" BO_ 1485 0;
BA_ "GenMsgILSupport" BO_ 1485 1;
BA_ "GenMsgCycleTime" BO_ 1485 500;
BA_ "Type" BO_ 1533 3;
BA_ "Period" BO_ 1533 250;
BA_ "GenMsgTimeoutTime" BO_ 1533 2500;
BA_ "GenMsgSendType" BO_ 1533 0;
BA_ "GenMsgILSupport" BO_ 1533 1;
BA_ "GenMsgCycleTime" BO_ 1533 250;
BA_ "Type" BO_ 1539 3;
BA_ "Period" BO_ 1539 1000;
BA_ "GenMsgTimeoutTime" BO_ 1539 2500;
BA_ "GenMsgSendType" BO_ 1539 0;
BA_ "GenMsgILSupport" BO_ 1539 1;
BA_ "GenMsgCycleTime" BO_ 1539 1000;
BA_ "Type" BO_ 1566 8;
BA_ "GenMsgTimeoutTime" BO_ 1566 2500;
BA_ "GenMsgILSupport" BO_ 1566 1;
BA_ "Type" BO_ 1667 3;
BA_ "Period" BO_ 1667 1000;
BA_ "GenMsgTimeoutTime" BO_ 1667 2500;
BA_ "GenMsgSendType" BO_ 1667 0;
BA_ "GenMsgILSupport" BO_ 1667 1;
BA_ "GenMsgDelayTime" BO_ 1667 10;
BA_ "GenMsgCycleTime" BO_ 1667 1000;
BA_ "Type" BO_ 1671 0;
BA_ "Period" BO_ 1671 1000;
BA_ "GenMsgTimeoutTime" BO_ 1671 2500;
BA_ "GenMsgSendType" BO_ 1671 0;
BA_ "GenMsgILSupport" BO_ 1671 1;
BA_ "GenMsgCycleTime" BO_ 1671 1000;
BA_ "Type" BO_ 1672 0;
BA_ "Period" BO_ 1672 1000;
BA_ "GenMsgTimeoutTime" BO_ 1672 2500;
BA_ "GenMsgSendType" BO_ 1672 0;
BA_ "GenMsgILSupport" BO_ 1672 1;
BA_ "GenMsgCycleTime" BO_ 1672 1000;
BA_ "Type" BO_ 1673 0;
BA_ "Period" BO_ 1673 1000;
BA_ "GenMsgTimeoutTime" BO_ 1673 2500;
BA_ "GenMsgSendType" BO_ 1673 0;
BA_ "GenMsgILSupport" BO_ 1673 1;
BA_ "GenMsgCycleTime" BO_ 1673 1000;
BA_ "Type" BO_ 1674 0;
BA_ "Period" BO_ 1674 1000;
BA_ "GenMsgTimeoutTime" BO_ 1674 2500;
BA_ "GenMsgSendType" BO_ 1674 0;
BA_ "GenMsgILSupport" BO_ 1674 1;
BA_ "GenMsgCycleTime" BO_ 1674 1000;
BA_ "Type" BO_ 1696 3;
BA_ "Period" BO_ 1696 1000;
BA_ "GenMsgTimeoutTime" BO_ 1696 2500;
BA_ "GenMsgSendType" BO_ 1696 0;
BA_ "GenMsgILSupport" BO_ 1696 1;
BA_ "GenMsgDelayTime" BO_ 1696 10;
BA_ "GenMsgCycleTime" BO_ 1696 1000;
BA_ "Type" BO_ 1726 3;
BA_ "Period" BO_ 1726 1000;
BA_ "GenMsgTimeoutTime" BO_ 1726 2500;
BA_ "GenMsgSendType" BO_ 1726 0;
BA_ "GenMsgILSupport" BO_ 1726 1;
BA_ "GenMsgCycleTime" BO_ 1726 1000;
BA_ "Type" BO_ 1728 1;
BA_ "Period" BO_ 1728 1000;
BA_ "GenMsgTimeoutTime" BO_ 1728 2500;
BA_ "GenMsgSendType" BO_ 1728 0;
BA_ "GenMsgILSupport" BO_ 1728 1;
BA_ "GenMsgCycleTime" BO_ 1728 1000;
BA_ "Type" BO_ 1735 1;
BA_ "Period" BO_ 1735 100;
BA_ "GenMsgTimeoutTime" BO_ 1735 2500;
BA_ "GenMsgSendType" BO_ 1735 0;
BA_ "GenMsgCycleTime" BO_ 1735 100;
BA_ "Type" BO_ 1752 1;
BA_ "Period" BO_ 1752 500;
BA_ "GenMsgTimeoutTime" BO_ 1752 2500;
BA_ "GenMsgSendType" BO_ 1752 0;
BA_ "GenMsgILSupport" BO_ 1752 1;
BA_ "GenMsgCycleTime" BO_ 1752 500;
BA_ "Type" BO_ 1764 3;
BA_ "Period" BO_ 1764 1000;
BA_ "GenMsgTimeoutTime" BO_ 1764 2500;
BA_ "GenMsgSendType" BO_ 1764 0;
BA_ "GenMsgILSupport" BO_ 1764 1;
BA_ "GenMsgCycleTime" BO_ 1764 1000;
BA_ "Type" BO_ 1767 3;
BA_ "Period" BO_ 1767 1000;
BA_ "GenMsgTimeoutTime" BO_ 1767 2500;
BA_ "GenMsgSendType" BO_ 1767 0;
BA_ "GenMsgILSupport" BO_ 1767 1;
BA_ "GenMsgCycleTime" BO_ 1767 1000;
BA_ "Type" BO_ 1772 3;
BA_ "Period" BO_ 1772 1000;
BA_ "GenMsgTimeoutTime" BO_ 1772 2500;
BA_ "GenMsgSendType" BO_ 1772 0;
BA_ "GenMsgILSupport" BO_ 1772 1;
BA_ "GenMsgCycleTime" BO_ 1772 1000;
BA_ "Type" BO_ 1792 3;
BA_ "Period" BO_ 1792 1000;
BA_ "NmMessage" BO_ 1792 1;
BA_ "GenMsgTimeoutTime" BO_ 1792 2500;
BA_ "GenMsgSendType" BO_ 1792 0;
BA_ "GenMsgCycleTime" BO_ 1792 1000;
BA_ "Type" BO_ 1796 3;
BA_ "Period" BO_ 1796 1000;
BA_ "NmMessage" BO_ 1796 1;
BA_ "GenMsgTimeoutTime" BO_ 1796 2500;
BA_ "GenMsgSendType" BO_ 1796 0;
BA_ "GenMsgCycleTime" BO_ 1796 1000;
BA_ "Type" BO_ 1801 3;
BA_ "Period" BO_ 1801 1000;
BA_ "NmMessage" BO_ 1801 1;
BA_ "GenMsgTimeoutTime" BO_ 1801 2500;
BA_ "GenMsgSendType" BO_ 1801 0;
BA_ "GenMsgCycleTime" BO_ 1801 1000;
BA_ "Type" BO_ 1802 3;
BA_ "Period" BO_ 1802 1000;
BA_ "NmMessage" BO_ 1802 1;
BA_ "GenMsgTimeoutTime" BO_ 1802 2500;
BA_ "GenMsgSendType" BO_ 1802 0;
BA_ "GenMsgCycleTime" BO_ 1802 1000;
BA_ "Type" BO_ 1810 3;
BA_ "Period" BO_ 1810 1000;
BA_ "NmMessage" BO_ 1810 1;
BA_ "GenMsgTimeoutTime" BO_ 1810 2500;
BA_ "GenMsgSendType" BO_ 1810 0;
BA_ "GenMsgCycleTime" BO_ 1810 1000;
BA_ "Type" BO_ 1815 3;
BA_ "Period" BO_ 1815 1000;
BA_ "NmMessage" BO_ 1815 1;
BA_ "GenMsgTimeoutTime" BO_ 1815 2500;
BA_ "GenMsgSendType" BO_ 1815 0;
BA_ "GenMsgCycleTime" BO_ 1815 1000;
BA_ "Type" BO_ 1816 3;
BA_ "Period" BO_ 1816 1000;
BA_ "NmMessage" BO_ 1816 1;
BA_ "GenMsgTimeoutTime" BO_ 1816 2500;
BA_ "GenMsgSendType" BO_ 1816 0;
BA_ "GenMsgCycleTime" BO_ 1816 1000;
BA_ "Type" BO_ 1823 3;
BA_ "Period" BO_ 1823 1000;
BA_ "NmMessage" BO_ 1823 1;
BA_ "GenMsgTimeoutTime" BO_ 1823 2500;
BA_ "GenMsgSendType" BO_ 1823 0;
BA_ "GenMsgCycleTime" BO_ 1823 1000;
BA_ "Type" BO_ 1856 8;
BA_ "GenMsgTimeoutTime" BO_ 1856 2500;
BA_ "GenMsgILSupport" BO_ 1856 1;
BA_ "Type" BO_ 1860 8;
BA_ "GenMsgTimeoutTime" BO_ 1860 2500;
BA_ "GenMsgILSupport" BO_ 1860 1;
BA_ "Type" BO_ 1865 8;
BA_ "GenMsgTimeoutTime" BO_ 1865 2500;
BA_ "GenMsgILSupport" BO_ 1865 1;
BA_ "Type" BO_ 1880 8;
BA_ "GenMsgTimeoutTime" BO_ 1880 2500;
BA_ "GenMsgILSupport" BO_ 1880 1;
BA_ "Type" BO_ 2510948864 0;
BA_ "Period" BO_ 2510948864 1000;
BA_ "GenMsgTimeoutTime" BO_ 2510948864 2500;
BA_ "GenMsgSendType" BO_ 2510948864 0;
BA_ "GenMsgILSupport" BO_ 2510948864 1;
BA_ "GenMsgCycleTime" BO_ 2510948864 1000;
BA_ "Type" BO_ 2510948865 0;
BA_ "Period" BO_ 2510948865 1000;
BA_ "GenMsgTimeoutTime" BO_ 2510948865 2500;
BA_ "GenMsgSendType" BO_ 2510948865 0;
BA_ "GenMsgILSupport" BO_ 2510948865 1;
BA_ "GenMsgCycleTime" BO_ 2510948865 1000;
BA_ "Type" BO_ 2510948866 0;
BA_ "Period" BO_ 2510948866 1000;
BA_ "GenMsgTimeoutTime" BO_ 2510948866 2500;
BA_ "GenMsgSendType" BO_ 2510948866 0;
BA_ "GenMsgILSupport" BO_ 2510948866 1;
BA_ "GenMsgCycleTime" BO_ 2510948866 1000;
BA_ "Type" BO_ 2510948867 0;
BA_ "Period" BO_ 2510948867 1000;
BA_ "GenMsgTimeoutTime" BO_ 2510948867 2500;
BA_ "GenMsgSendType" BO_ 2510948867 0;
BA_ "GenMsgILSupport" BO_ 2510948867 1;
BA_ "GenMsgCycleTime" BO_ 2510948867 1000;
BA_ "Type" BO_ 2510948868 0;
BA_ "Period" BO_ 2510948868 1000;
BA_ "GenMsgTimeoutTime" BO_ 2510948868 2500;
BA_ "GenMsgSendType" BO_ 2510948868 0;
BA_ "GenMsgILSupport" BO_ 2510948868 1;
BA_ "GenMsgCycleTime" BO_ 2510948868 1000;
BA_ "Type" BO_ 2510948869 0;
BA_ "Period" BO_ 2510948869 500;
BA_ "GenMsgTimeoutTime" BO_ 2510948869 2500;
BA_ "GenMsgSendType" BO_ 2510948869 0;
BA_ "GenMsgILSupport" BO_ 2510948869 1;
BA_ "GenMsgCycleTime" BO_ 2510948869 500;
BA_ "Type" BO_ 2510948870 0;
BA_ "Period" BO_ 2510948870 1000;
BA_ "GenMsgTimeoutTime" BO_ 2510948870 2500;
BA_ "GenMsgSendType" BO_ 2510948870 0;
BA_ "GenMsgILSupport" BO_ 2510948870 1;
BA_ "GenMsgCycleTime" BO_ 2510948870 1000;
BA_ "Type" BO_ 2510948871 0;
BA_ "Period" BO_ 2510948871 1000;
BA_ "GenMsgTimeoutTime" BO_ 2510948871 2500;
BA_ "GenMsgSendType" BO_ 2510948871 0;
BA_ "GenMsgILSupport" BO_ 2510948871 1;
BA_ "GenMsgCycleTime" BO_ 2510948871 1000;
BA_ "Type" BO_ 2564425969 8;
BA_ "DiagRequest" BO_ 2564425969 1;
BA_ "Type" BO_ 2564426225 8;
BA_ "DiagRequest" BO_ 2564426225 1;
BA_ "Type" BO_ 2564430577 8;
BA_ "DiagRequest" BO_ 2564430577 1;
BA_ "Type" BO_ 2564444657 8;
BA_ "DiagRequest" BO_ 2564444657 1;
BA_ "Type" BO_ 2564447985 8;
BA_ "DiagRequest" BO_ 2564447985 1;
BA_ "Type" BO_ 2564448241 8;
BA_ "DiagRequest" BO_ 2564448241 1;
BA_ "Type" BO_ 2564449265 8;
BA_ "DiagRequest" BO_ 2564449265 1;
BA_ "Type" BO_ 2564453105 8;
BA_ "DiagRequest" BO_ 2564453105 1;
BA_ "Type" BO_ 2564453361 8;
BA_ "DiagRequest" BO_ 2564453361 1;
BA_ "Type" BO_ 2564455665 8;
BA_ "DiagRequest" BO_ 2564455665 1;
BA_ "Type" BO_ 2564455921 8;
BA_ "DiagRequest" BO_ 2564455921 1;
BA_ "Type" BO_ 2564458225 8;
BA_ "DiagRequest" BO_ 2564458225 1;
BA_ "Type" BO_ 2564459249 8;
BA_ "DiagRequest" BO_ 2564459249 1;
BA_ "Type" BO_ 2564460529 8;
BA_ "DiagRequest" BO_ 2564460529 1;
BA_ "Type" BO_ 2564463601 8;
BA_ "DiagRequest" BO_ 2564463601 1;
BA_ "Type" BO_ 2564481777 8;
BA_ "DiagRequest" BO_ 2564481777 1;
BA_ "Type" BO_ 2564482033 8;
BA_ "DiagRequest" BO_ 2564482033 1;
BA_ "Type" BO_ 2564485384 8;
BA_ "DiagResponse" BO_ 2564485384 1;
BA_ "Type" BO_ 2564485385 8;
BA_ "DiagResponse" BO_ 2564485385 1;
BA_ "Type" BO_ 2564485402 8;
BA_ "DiagResponse" BO_ 2564485402 1;
BA_ "Type" BO_ 2564485457 8;
BA_ "DiagResponse" BO_ 2564485457 1;
BA_ "Type" BO_ 2564485470 8;
BA_ "DiagResponse" BO_ 2564485470 1;
BA_ "Type" BO_ 2564485471 8;
BA_ "DiagResponse" BO_ 2564485471 1;
BA_ "Type" BO_ 2564485475 8;
BA_ "DiagResponse" BO_ 2564485475 1;
BA_ "Type" BO_ 2564485490 8;
BA_ "DiagResponse" BO_ 2564485490 1;
BA_ "Type" BO_ 2564485491 8;
BA_ "DiagResponse" BO_ 2564485491 1;
BA_ "Type" BO_ 2564485500 8;
BA_ "DiagResponse" BO_ 2564485500 1;
BA_ "Type" BO_ 2564485501 8;
BA_ "DiagResponse" BO_ 2564485501 1;
BA_ "Type" BO_ 2564485510 8;
BA_ "DiagResponse" BO_ 2564485510 1;
BA_ "Type" BO_ 2564485514 8;
BA_ "DiagResponse" BO_ 2564485514 1;
BA_ "Type" BO_ 2564485519 8;
BA_ "DiagResponse" BO_ 2564485519 1;
BA_ "Type" BO_ 2564485531 8;
BA_ "DiagResponse" BO_ 2564485531 1;
BA_ "Type" BO_ 2564485602 8;
BA_ "DiagResponse" BO_ 2564485602 1;
BA_ "Type" BO_ 2564485603 8;
BA_ "DiagResponse" BO_ 2564485603 1;
BA_ "Type" BO_ 2564554481 8;
BA_ "DiagRequest" BO_ 2564554481 1;
BA_ "Type" BO_ 2651930624 8;
BA_ "GenMsgTimeoutTime" BO_ 2651930624 2500;
BA_ "GenMsgILSupport" BO_ 2651930624 1;
BA_ "Type" BO_ 2651930650 8;
BA_ "GenMsgTimeoutTime" BO_ 2651930650 2500;
BA_ "GenMsgILSupport" BO_ 2651930650 1;
BA_ "Type" BO_ 2651930679 8;
BA_ "GenMsgTimeoutTime" BO_ 2651930679 2500;
BA_ "GenMsgILSupport" BO_ 2651930679 1;
BA_ "Type" BO_ 2651930680 8;
BA_ "GenMsgTimeoutTime" BO_ 2651930680 2500;
BA_ "GenMsgILSupport" BO_ 2651930680 1;
BA_ "Type" BO_ 2651930718 8;
BA_ "GenMsgTimeoutTime" BO_ 2651930718 2500;
BA_ "GenMsgILSupport" BO_ 2651930718 1;
BA_ "Type" BO_ 2651930719 8;
BA_ "GenMsgTimeoutTime" BO_ 2651930719 2500;
BA_ "GenMsgILSupport" BO_ 2651930719 1;
BA_ "Type" BO_ 2651930720 8;
BA_ "GenMsgTimeoutTime" BO_ 2651930720 2500;
BA_ "GenMsgILSupport" BO_ 2651930720 1;
BA_ "Type" BO_ 2651930721 8;
BA_ "GenMsgTimeoutTime" BO_ 2651930721 2500;
BA_ "GenMsgILSupport" BO_ 2651930721 1;
BA_ "Type" BO_ 2654208034 3;
BA_ "Period" BO_ 2654208034 1000;
BA_ "NmMessage" BO_ 2654208034 1;
BA_ "GenMsgTimeoutTime" BO_ 2654208034 2500;
BA_ "GenMsgSendType" BO_ 2654208034 0;
BA_ "GenMsgCycleTime" BO_ 2654208034 1000;
BA_ "Type" BO_ 2654208055 3;
BA_ "Period" BO_ 2654208055 1000;
BA_ "NmMessage" BO_ 2654208055 1;
BA_ "GenMsgTimeoutTime" BO_ 2654208055 2500;
BA_ "GenMsgSendType" BO_ 2654208055 0;
BA_ "GenMsgCycleTime" BO_ 2654208055 1000;
BA_ "Type" BO_ 2654208056 3;
BA_ "Period" BO_ 2654208056 1000;
BA_ "NmMessage" BO_ 2654208056 1;
BA_ "GenMsgTimeoutTime" BO_ 2654208056 2500;
BA_ "GenMsgSendType" BO_ 2654208056 0;
BA_ "GenMsgCycleTime" BO_ 2654208056 1000;
BA_ "Type" BO_ 2654208081 3;
BA_ "Period" BO_ 2654208081 1000;
BA_ "NmMessage" BO_ 2654208081 1;
BA_ "GenMsgTimeoutTime" BO_ 2654208081 2500;
BA_ "GenMsgSendType" BO_ 2654208081 0;
BA_ "GenMsgCycleTime" BO_ 2654208081 1000;
BA_ "Type" BO_ 2654208082 3;
BA_ "Period" BO_ 2654208082 1000;
BA_ "NmMessage" BO_ 2654208082 1;
BA_ "GenMsgTimeoutTime" BO_ 2654208082 2500;
BA_ "GenMsgSendType" BO_ 2654208082 0;
BA_ "GenMsgCycleTime" BO_ 2654208082 1000;
BA_ "Type" BO_ 2654208094 3;
BA_ "Period" BO_ 2654208094 1000;
BA_ "NmMessage" BO_ 2654208094 1;
BA_ "GenMsgTimeoutTime" BO_ 2654208094 2500;
BA_ "GenMsgSendType" BO_ 2654208094 0;
BA_ "GenMsgCycleTime" BO_ 2654208094 1000;
BA_ "Type" BO_ 2654208095 3;
BA_ "Period" BO_ 2654208095 1000;
BA_ "NmMessage" BO_ 2654208095 1;
BA_ "GenMsgTimeoutTime" BO_ 2654208095 2500;
BA_ "GenMsgSendType" BO_ 2654208095 0;
BA_ "GenMsgCycleTime" BO_ 2654208095 1000;
BA_ "Type" BO_ 2654208096 3;
BA_ "Period" BO_ 2654208096 1000;
BA_ "NmMessage" BO_ 2654208096 1;
BA_ "GenMsgTimeoutTime" BO_ 2654208096 2500;
BA_ "GenMsgSendType" BO_ 2654208096 0;
BA_ "GenMsgCycleTime" BO_ 2654208096 1000;
BA_ "Type" BO_ 2654208097 3;
BA_ "Period" BO_ 2654208097 1000;
BA_ "NmMessage" BO_ 2654208097 1;
BA_ "GenMsgTimeoutTime" BO_ 2654208097 2500;
BA_ "GenMsgSendType" BO_ 2654208097 0;
BA_ "GenMsgCycleTime" BO_ 2654208097 1000;
BA_ "Type" BO_ 2654208120 3;
BA_ "Period" BO_ 2654208120 1000;
BA_ "NmMessage" BO_ 2654208120 1;
BA_ "GenMsgTimeoutTime" BO_ 2654208120 2500;
BA_ "GenMsgSendType" BO_ 2654208120 0;
BA_ "GenMsgCycleTime" BO_ 2654208120 1000;
BA_ "Type" BO_ 2654208121 3;
BA_ "Period" BO_ 2654208121 1000;
BA_ "NmMessage" BO_ 2654208121 1;
BA_ "GenMsgTimeoutTime" BO_ 2654208121 2500;
BA_ "GenMsgSendType" BO_ 2654208121 0;
BA_ "GenMsgCycleTime" BO_ 2654208121 1000;
BA_ "Type" BO_ 2654208122 3;
BA_ "Period" BO_ 2654208122 1000;
BA_ "NmMessage" BO_ 2654208122 1;
BA_ "GenMsgTimeoutTime" BO_ 2654208122 2500;
BA_ "GenMsgSendType" BO_ 2654208122 0;
BA_ "GenMsgCycleTime" BO_ 2654208122 1000;
BA_ "GenSigSendType" SG_ 1428 RRAutoMode 3;
BA_ "EventTrans" SG_ 1428 RRAutoMode 0;
BA_ "GenSigSendType" SG_ 1428 RLAutoMode 3;
BA_ "EventTrans" SG_ 1428 RLAutoMode 0;
BA_ "GenSigSendType" SG_ 1428 RLTemperature 3;
BA_ "EventTrans" SG_ 1428 RLTemperature 0;
BA_ "GenSigSendType" SG_ 1428 RRTemperature 3;
BA_ "EventTrans" SG_ 1428 RRTemperature 0;
BA_ "GenSigSendType" SG_ 1428 RLAirFlowZone 3;
BA_ "EventTrans" SG_ 1428 RLAirFlowZone 0;
BA_ "GenSigSendType" SG_ 1428 RRAirFlowZone 3;
BA_ "EventTrans" SG_ 1428 RRAirFlowZone 0;
BA_ "GenSigSendType" SG_ 1428 RearClimateReq 3;
BA_ "EventTrans" SG_ 1428 RearClimateReq 0;
BA_ "GenSigSendType" SG_ 1428 RLPresetMode 3;
BA_ "EventTrans" SG_ 1428 RLPresetMode 0;
BA_ "GenSigSendType" SG_ 1428 RBlowerSpeed10L 3;
BA_ "EventTrans" SG_ 1428 RBlowerSpeed10L 0;
BA_ "GenSigSendType" SG_ 1428 NCL_RearBlowerAutoMode 3;
BA_ "EventTrans" SG_ 1428 NCL_RearBlowerAutoMode 0;
BA_ "GenSigSendType" SG_ 1428 RearSourceCommand 3;
BA_ "EventTrans" SG_ 1428 RearSourceCommand 0;
BA_ "GenSigSendType" SG_ 1428 RRPresetMode 3;
BA_ "EventTrans" SG_ 1428 RRPresetMode 0;
BA_ "GenSigSendType" SG_ 1428 RRThermalComfort 3;
BA_ "EventTrans" SG_ 1428 RRThermalComfort 0;
BA_ "GenSigSendType" SG_ 1428 RLThermalComfort 3;
BA_ "EventTrans" SG_ 1428 RLThermalComfort 0;
BA_ "InitialValue" SG_ 1429 RSL_SeatTemperature -10;
BA_ "GenSigSendType" SG_ 1429 RSL_SeatTemperature 3;
BA_ "EventTrans" SG_ 1429 RSL_SeatTemperature 0;
BA_ "GenSigSendType" SG_ 1429 RSLHeating 3;
BA_ "EventTrans" SG_ 1429 RSLHeating 0;
BA_ "GenSigSendType" SG_ 1429 RSLFans 3;
BA_ "EventTrans" SG_ 1429 RSLFans 0;
BA_ "InitialValue" SG_ 1430 RSR_SeatTemperature -10;
BA_ "GenSigSendType" SG_ 1430 RSR_SeatTemperature 3;
BA_ "EventTrans" SG_ 1430 RSR_SeatTemperature 0;
BA_ "GenSigSendType" SG_ 1430 RSRHeating 3;
BA_ "EventTrans" SG_ 1430 RSRHeating 0;
BA_ "GenSigSendType" SG_ 1430 RSRFans 3;
BA_ "EventTrans" SG_ 1430 RSRFans 0;
BA_ "GenSigSendType" SG_ 1431 RearSeatLeftBackRestPos 3;
BA_ "EventTrans" SG_ 1431 RearSeatLeftBackRestPos 0;
BA_ "GenSigSendType" SG_ 1431 RearSeatLeftLongitudinalPos 3;
BA_ "EventTrans" SG_ 1431 RearSeatLeftLongitudinalPos 0;
BA_ "GenSigSendType" SG_ 1431 RearSeatLeftTiltPos 3;
BA_ "EventTrans" SG_ 1431 RearSeatLeftTiltPos 0;
BA_ "GenSigSendType" SG_ 1431 RearSeatLeftLiftPos 3;
BA_ "EventTrans" SG_ 1431 RearSeatLeftLiftPos 0;
BA_ "GenSigSendType" SG_ 1432 RearSeatRightBackRestPos 3;
BA_ "EventTrans" SG_ 1432 RearSeatRightBackRestPos 0;
BA_ "GenSigSendType" SG_ 1432 RearSeatRightLongitudinalPos 3;
BA_ "EventTrans" SG_ 1432 RearSeatRightLongitudinalPos 0;
BA_ "GenSigSendType" SG_ 1432 RearSeatRightTiltPos 3;
BA_ "EventTrans" SG_ 1432 RearSeatRightTiltPos 0;
BA_ "GenSigSendType" SG_ 1432 RearSeatRightLiftPos 3;
BA_ "EventTrans" SG_ 1432 RearSeatRightLiftPos 0;
BA_ "SignalAge" SG_ 1441 BatteryVoltageLevel 1000;
BA_ "Accuracy" SG_ 1441 BatteryVoltageLevel "±0,05V";
BA_ "InitialValue" SG_ 1441 RechargeSts 1;
BA_ "GenSigStartValue" SG_ 1441 RechargeSts 1;
BA_ "GenSigSendType" SG_ 1444 MirrorsProfileReq 3;
BA_ "EventTrans" SG_ 1444 MirrorsProfileReq 0;
BA_ "GenSigSendType" SG_ 1444 NIT_DriverMirrorHorizDirection 3;
BA_ "EventTrans" SG_ 1444 NIT_DriverMirrorHorizDirection 0;
BA_ "GenSigSendType" SG_ 1444 NIT_DriverMirrorVertDirection 3;
BA_ "EventTrans" SG_ 1444 NIT_DriverMirrorVertDirection 0;
BA_ "GenSigSendType" SG_ 1444 PeriodMessage_CmdProfile 5;
BA_ "GenSigSendType" SG_ 1444 NIT_DriverMirrorHorizPos 3;
BA_ "EventTrans" SG_ 1444 NIT_DriverMirrorHorizPos 0;
BA_ "GenSigSendType" SG_ 1444 NIT_DriverMirrorVertPos 3;
BA_ "EventTrans" SG_ 1444 NIT_DriverMirrorVertPos 0;
BA_ "GenSigSendType" SG_ 1444 NIT_ColumnMotorH 3;
BA_ "EventTrans" SG_ 1444 NIT_ColumnMotorH 0;
BA_ "GenSigSendType" SG_ 1444 ColumnProfileReq 3;
BA_ "EventTrans" SG_ 1444 ColumnProfileReq 0;
BA_ "GenSigSendType" SG_ 1444 NIT_ColumnMotorV 3;
BA_ "EventTrans" SG_ 1444 NIT_ColumnMotorV 0;
BA_ "GenSigSendType" SG_ 1444 NIT_PassengerMirrorVertPos 3;
BA_ "EventTrans" SG_ 1444 NIT_PassengerMirrorVertPos 0;
BA_ "GenSigSendType" SG_ 1444 NIT_PassengerMirrorHorizPos 3;
BA_ "EventTrans" SG_ 1444 NIT_PassengerMirrorHorizPos 0;
BA_ "InitialValue" SG_ 1446 NITAmbientLightNightDay 1;
BA_ "GenSigStartValue" SG_ 1446 NITAmbientLightNightDay 1;
BA_ "GenSigSendType" SG_ 1446 NITAmbientLightNightDay 3;
BA_ "EventTrans" SG_ 1446 NITAmbientLightNightDay 0;
BA_ "InitialValue" SG_ 1446 NITAmbientLightNightDaySwitch 1;
BA_ "GenSigStartValue" SG_ 1446 NITAmbientLightNightDaySwitch 1;
BA_ "GenSigSendType" SG_ 1446 NITAmbientLightNightDaySwitch 3;
BA_ "EventTrans" SG_ 1446 NITAmbientLightNightDaySwitch 0;
BA_ "GenSigSendType" SG_ 1446 NITAmbientLightIntensityNight 3;
BA_ "EventTrans" SG_ 1446 NITAmbientLightIntensityNight 0;
BA_ "GenSigSendType" SG_ 1446 NITAmbientLightIntensityDay 3;
BA_ "EventTrans" SG_ 1446 NITAmbientLightIntensityDay 0;
BA_ "GenSigSendType" SG_ 1446 MirrorMovementReqCntrl 3;
BA_ "EventTrans" SG_ 1446 MirrorMovementReqCntrl 0;
BA_ "InitialValue" SG_ 1446 NITAmbientLightNightEnable 1;
BA_ "GenSigStartValue" SG_ 1446 NITAmbientLightNightEnable 1;
BA_ "GenSigSendType" SG_ 1446 NITAmbientLightNightEnable 3;
BA_ "EventTrans" SG_ 1446 NITAmbientLightNightEnable 0;
BA_ "InitialValue" SG_ 1446 NITAmbientLightDayEnable 1;
BA_ "GenSigStartValue" SG_ 1446 NITAmbientLightDayEnable 1;
BA_ "GenSigSendType" SG_ 1446 NITAmbientLightDayEnable 3;
BA_ "EventTrans" SG_ 1446 NITAmbientLightDayEnable 0;
BA_ "GenSigSendType" SG_ 1446 NITAmbientLightColour 3;
BA_ "EventTrans" SG_ 1446 NITAmbientLightColour 0;
BA_ "GenSigSendType" SG_ 1446 NIT_DimmingLevelRoof2 1;
BA_ "EventTrans" SG_ 1446 NIT_DimmingLevelRoof2 0;
BA_ "GenSigSendType" SG_ 1446 NIT_DimmingLevelRoof1 1;
BA_ "EventTrans" SG_ 1446 NIT_DimmingLevelRoof1 0;
BA_ "GenSigSendType" SG_ 1446 IDC_Deactivation_DoorOpening_Swi 3;
BA_ "EventTrans" SG_ 1446 IDC_Deactivation_DoorOpening_Swi 0;
BA_ "SystemSignalLongSymbol" SG_ 1446 IDC_Deactivation_DoorOpening_Swi "IDC_Deactivation_DoorOpening_Switch";
BA_ "GenSigSendType" SG_ 1446 NITFailSts 3;
BA_ "EventTrans" SG_ 1446 NITFailSts 0;
BA_ "GenSigSendType" SG_ 1446 NIT_DimmingLevelRoof4 1;
BA_ "EventTrans" SG_ 1446 NIT_DimmingLevelRoof4 0;
BA_ "GenSigSendType" SG_ 1446 NIT_DimmingLevelRoof3 1;
BA_ "EventTrans" SG_ 1446 NIT_DimmingLevelRoof3 0;
BA_ "GenSigSendType" SG_ 1446 NIT_DimmingLevelRoof6 1;
BA_ "EventTrans" SG_ 1446 NIT_DimmingLevelRoof6 0;
BA_ "GenSigSendType" SG_ 1446 NIT_DimmingLevelRoof5 1;
BA_ "EventTrans" SG_ 1446 NIT_DimmingLevelRoof5 0;
BA_ "GenSigSendType" SG_ 1446 IDC_Spot_RH_Button_Rear 3;
BA_ "EventTrans" SG_ 1446 IDC_Spot_RH_Button_Rear 0;
BA_ "GenSigSendType" SG_ 1446 IDC_Spot_LH_Button_Rear 3;
BA_ "EventTrans" SG_ 1446 IDC_Spot_LH_Button_Rear 0;
BA_ "GenSigSendType" SG_ 1446 ChargeButtonReq 3;
BA_ "EventTrans" SG_ 1446 ChargeButtonReq 0;
BA_ "GenSigSendType" SG_ 1446 IDC_RearLightCommand_Left 3;
BA_ "EventTrans" SG_ 1446 IDC_RearLightCommand_Left 0;
BA_ "GenSigSendType" SG_ 1446 IDC_RearLightCommand_Right 3;
BA_ "EventTrans" SG_ 1446 IDC_RearLightCommand_Right 0;
BA_ "GenSigSendType" SG_ 1447 FrontPassengerHeating 1;
BA_ "EventTrans" SG_ 1447 FrontPassengerHeating 0;
BA_ "GenSigSendType" SG_ 1447 DriverAirScarf 1;
BA_ "EventTrans" SG_ 1447 DriverAirScarf 0;
BA_ "GenSigSendType" SG_ 1447 FrontDriverHeating 1;
BA_ "EventTrans" SG_ 1447 FrontDriverHeating 0;
BA_ "GenSigSendType" SG_ 1447 DriverFans 1;
BA_ "EventTrans" SG_ 1447 DriverFans 0;
BA_ "GenSigSendType" SG_ 1447 DriverMassageType 1;
BA_ "EventTrans" SG_ 1447 DriverMassageType 0;
BA_ "GenSigSendType" SG_ 1447 DriverMassageLevel 1;
BA_ "EventTrans" SG_ 1447 DriverMassageLevel 0;
BA_ "GenSigSendType" SG_ 1447 PassengerFans 1;
BA_ "EventTrans" SG_ 1447 PassengerFans 0;
BA_ "GenSigSendType" SG_ 1447 PsngrMassageType 1;
BA_ "EventTrans" SG_ 1447 PsngrMassageType 0;
BA_ "GenSigSendType" SG_ 1447 PsngrMassageLevel 1;
BA_ "EventTrans" SG_ 1447 PsngrMassageLevel 0;
BA_ "GenSigSendType" SG_ 1447 PsngrAirScarf 1;
BA_ "EventTrans" SG_ 1447 PsngrAirScarf 0;
BA_ "GenSigSendType" SG_ 1448 DriverAirFlowZone 1;
BA_ "EventTrans" SG_ 1448 DriverAirFlowZone 0;
BA_ "InitialValue" SG_ 1448 DriverTemperature 15;
BA_ "GenSigSendType" SG_ 1448 DriverTemperature 1;
BA_ "EventTrans" SG_ 1448 DriverTemperature 0;
BA_ "GenSigSendType" SG_ 1448 PassengerAirFlowZone 1;
BA_ "EventTrans" SG_ 1448 PassengerAirFlowZone 0;
BA_ "InitialValue" SG_ 1448 PassengerTemperature 15;
BA_ "GenSigSendType" SG_ 1448 PassengerTemperature 1;
BA_ "EventTrans" SG_ 1448 PassengerTemperature 0;
BA_ "GenSigSendType" SG_ 1448 CentralVent 1;
BA_ "EventTrans" SG_ 1448 CentralVent 0;
BA_ "GenSigSendType" SG_ 1448 AirConditionCompressor 1;
BA_ "EventTrans" SG_ 1448 AirConditionCompressor 0;
BA_ "GenSigSendType" SG_ 1448 BlowerSpeed_Infotainment 1;
BA_ "EventTrans" SG_ 1448 BlowerSpeed_Infotainment 0;
BA_ "GenSigSendType" SG_ 1448 MonoMode 1;
BA_ "EventTrans" SG_ 1448 MonoMode 0;
BA_ "GenSigSendType" SG_ 1448 PassengerAutoMode 1;
BA_ "EventTrans" SG_ 1448 PassengerAutoMode 0;
BA_ "GenSigSendType" SG_ 1448 DriverAutoMode 1;
BA_ "EventTrans" SG_ 1448 DriverAutoMode 0;
BA_ "GenSigSendType" SG_ 1448 BlowerSpeed10L 1;
BA_ "EventTrans" SG_ 1448 BlowerSpeed10L 0;
BA_ "GenSigSendType" SG_ 1448 AirRecirculation 1;
BA_ "EventTrans" SG_ 1448 AirRecirculation 0;
BA_ "GenSigSendType" SG_ 1448 NIT_BlowerAutoMode 1;
BA_ "EventTrans" SG_ 1448 NIT_BlowerAutoMode 0;
BA_ "GenSigSendType" SG_ 1448 ClimateReq 1;
BA_ "EventTrans" SG_ 1448 ClimateReq 0;
BA_ "GenSigSendType" SG_ 1448 AirSanitizer 1;
BA_ "EventTrans" SG_ 1448 AirSanitizer 0;
BA_ "GenSigSendType" SG_ 1449 PeriodMessage 5;
BA_ "GenSigSendType" SG_ 1449 SeatProfileReq 3;
BA_ "EventTrans" SG_ 1449 SeatProfileReq 0;
BA_ "GenSigSendType" SG_ 1450 AirRecirculation 3;
BA_ "EventTrans" SG_ 1450 AirRecirculation 0;
BA_ "GenSigSendType" SG_ 1450 PassengerAutoMode 3;
BA_ "EventTrans" SG_ 1450 PassengerAutoMode 0;
BA_ "GenSigSendType" SG_ 1450 DriverAutoMode 3;
BA_ "EventTrans" SG_ 1450 DriverAutoMode 0;
BA_ "InitialValue" SG_ 1450 DriverTemperature 15;
BA_ "GenSigSendType" SG_ 1450 DriverTemperature 3;
BA_ "GenSigInactiveValue" SG_ 1450 DriverTemperature 15;
BA_ "EventTrans" SG_ 1450 DriverTemperature 0;
BA_ "InitialValue" SG_ 1450 PassengerTemperature 15;
BA_ "GenSigSendType" SG_ 1450 PassengerTemperature 3;
BA_ "GenSigInactiveValue" SG_ 1450 PassengerTemperature 15;
BA_ "EventTrans" SG_ 1450 PassengerTemperature 0;
BA_ "GenSigSendType" SG_ 1450 DriverAirFlowZone 3;
BA_ "EventTrans" SG_ 1450 DriverAirFlowZone 0;
BA_ "GenSigSendType" SG_ 1450 AirConditionCompressor 3;
BA_ "EventTrans" SG_ 1450 AirConditionCompressor 0;
BA_ "GenSigSendType" SG_ 1450 BlowerSpeed 3;
BA_ "EventTrans" SG_ 1450 BlowerSpeed 0;
BA_ "GenSigSendType" SG_ 1450 PassengerAirFlowZone 3;
BA_ "EventTrans" SG_ 1450 PassengerAirFlowZone 0;
BA_ "GenSigSendType" SG_ 1450 MonoMode 3;
BA_ "EventTrans" SG_ 1450 MonoMode 0;
BA_ "GenSigSendType" SG_ 1450 BlowerSpeed10L 3;
BA_ "EventTrans" SG_ 1450 BlowerSpeed10L 0;
BA_ "GenSigSendType" SG_ 1450 CentralVent 3;
BA_ "EventTrans" SG_ 1450 CentralVent 0;
BA_ "GenSigSendType" SG_ 1450 NCL_BlowerAutoMode 3;
BA_ "EventTrans" SG_ 1450 NCL_BlowerAutoMode 0;
BA_ "GenSigSendType" SG_ 1450 SourceCommand 3;
BA_ "EventTrans" SG_ 1450 SourceCommand 0;
BA_ "GenSigSendType" SG_ 1450 Temp_Req_Down_Driver 3;
BA_ "EventTrans" SG_ 1450 Temp_Req_Down_Driver 0;
BA_ "GenSigSendType" SG_ 1450 Temp_Req_Up_Driver 3;
BA_ "EventTrans" SG_ 1450 Temp_Req_Up_Driver 0;
BA_ "GenSigSendType" SG_ 1450 AirSanitizer 3;
BA_ "EventTrans" SG_ 1450 AirSanitizer 0;
BA_ "GenSigSendType" SG_ 1450 ClimateReq 3;
BA_ "EventTrans" SG_ 1450 ClimateReq 0;
BA_ "GenSigSendType" SG_ 1451 NIT_RLHeating 1;
BA_ "EventTrans" SG_ 1451 NIT_RLHeating 0;
BA_ "GenSigSendType" SG_ 1451 NIT_RLFans 1;
BA_ "EventTrans" SG_ 1451 NIT_RLFans 0;
BA_ "GenSigSendType" SG_ 1451 NIT_RRHeating 1;
BA_ "EventTrans" SG_ 1451 NIT_RRHeating 0;
BA_ "GenSigSendType" SG_ 1451 NIT_RRFans 1;
BA_ "EventTrans" SG_ 1451 NIT_RRFans 0;
BA_ "GenSigSendType" SG_ 1452 NIT_RLAirFlowZone 1;
BA_ "EventTrans" SG_ 1452 NIT_RLAirFlowZone 0;
BA_ "GenSigSendType" SG_ 1452 NIT_RLTemperature 1;
BA_ "EventTrans" SG_ 1452 NIT_RLTemperature 0;
BA_ "GenSigSendType" SG_ 1452 NIT_RRAirFlowZone 1;
BA_ "EventTrans" SG_ 1452 NIT_RRAirFlowZone 0;
BA_ "GenSigSendType" SG_ 1452 NIT_RRTemperature 1;
BA_ "EventTrans" SG_ 1452 NIT_RRTemperature 0;
BA_ "GenSigSendType" SG_ 1452 RearClimateReq 1;
BA_ "EventTrans" SG_ 1452 RearClimateReq 0;
BA_ "GenSigSendType" SG_ 1452 NIT_RearBlowerSpeed 1;
BA_ "EventTrans" SG_ 1452 NIT_RearBlowerSpeed 0;
BA_ "GenSigSendType" SG_ 1452 NIT_RRAutoMode 1;
BA_ "EventTrans" SG_ 1452 NIT_RRAutoMode 0;
BA_ "GenSigSendType" SG_ 1452 NIT_RLAutoMode 1;
BA_ "EventTrans" SG_ 1452 NIT_RLAutoMode 0;
BA_ "GenSigSendType" SG_ 1452 NIT_RRPresetMode 1;
BA_ "EventTrans" SG_ 1452 NIT_RRPresetMode 0;
BA_ "GenSigSendType" SG_ 1452 NIT_RLPresetMode 1;
BA_ "EventTrans" SG_ 1452 NIT_RLPresetMode 0;
BA_ "GenSigSendType" SG_ 1452 NIT_RearBlowerSpeed10L 1;
BA_ "EventTrans" SG_ 1452 NIT_RearBlowerSpeed10L 0;
BA_ "GenSigSendType" SG_ 1452 NIT_RLAirFlowZonePersPreset 1;
BA_ "EventTrans" SG_ 1452 NIT_RLAirFlowZonePersPreset 0;
BA_ "GenSigSendType" SG_ 1452 NIT_RLTemperaturePersPreset 1;
BA_ "EventTrans" SG_ 1452 NIT_RLTemperaturePersPreset 0;
BA_ "GenSigSendType" SG_ 1452 NIT_RearBlowerAutoMode 1;
BA_ "EventTrans" SG_ 1452 NIT_RearBlowerAutoMode 0;
BA_ "GenSigSendType" SG_ 1452 NIT_RRAirFlowZonePersPreset 1;
BA_ "EventTrans" SG_ 1452 NIT_RRAirFlowZonePersPreset 0;
BA_ "GenSigSendType" SG_ 1452 NIT_RearBlowerSpeed10LPersPreset 1;
BA_ "EventTrans" SG_ 1452 NIT_RearBlowerSpeed10LPersPreset 0;
BA_ "GenSigSendType" SG_ 1452 NIT_RRTemperaturePersPreset 1;
BA_ "EventTrans" SG_ 1452 NIT_RRTemperaturePersPreset 0;
BA_ "GenSigSendType" SG_ 1454 MKF_DimmingLevelRoof1 3;
BA_ "EventTrans" SG_ 1454 MKF_DimmingLevelRoof1 0;
BA_ "InitialValue" SG_ 1454 MKF_RimHeatingCommand 1;
BA_ "GenSigStartValue" SG_ 1454 MKF_RimHeatingCommand 1;
BA_ "GenSigSendType" SG_ 1454 MKF_RimHeatingCommand 3;
BA_ "EventTrans" SG_ 1454 MKF_RimHeatingCommand 0;
BA_ "InitialValue" SG_ 1457 NBCAmbientLightNightDay 1;
BA_ "GenSigStartValue" SG_ 1457 NBCAmbientLightNightDay 1;
BA_ "GenSigSendType" SG_ 1457 NBCAmbientLightNightDay 3;
BA_ "EventTrans" SG_ 1457 NBCAmbientLightNightDay 0;
BA_ "InitialValue" SG_ 1457 NBCAmbientLightNightDaySwitch 1;
BA_ "GenSigStartValue" SG_ 1457 NBCAmbientLightNightDaySwitch 1;
BA_ "GenSigSendType" SG_ 1457 NBCAmbientLightNightDaySwitch 3;
BA_ "EventTrans" SG_ 1457 NBCAmbientLightNightDaySwitch 0;
BA_ "GenSigSendType" SG_ 1457 NBCAmbientLightIntensityNight 3;
BA_ "EventTrans" SG_ 1457 NBCAmbientLightIntensityNight 0;
BA_ "GenSigSendType" SG_ 1457 NBCAmbientLightIntensityDay 3;
BA_ "EventTrans" SG_ 1457 NBCAmbientLightIntensityDay 0;
BA_ "InitialValue" SG_ 1457 NBCAmbientLightDayEnable 1;
BA_ "GenSigStartValue" SG_ 1457 NBCAmbientLightDayEnable 1;
BA_ "GenSigSendType" SG_ 1457 NBCAmbientLightDayEnable 3;
BA_ "EventTrans" SG_ 1457 NBCAmbientLightDayEnable 0;
BA_ "GenSigSendType" SG_ 1457 NBC_DimmingLevelRoof1 3;
BA_ "EventTrans" SG_ 1457 NBC_DimmingLevelRoof1 0;
BA_ "GenSigSendType" SG_ 1457 NBCAmbientLightColour 3;
BA_ "EventTrans" SG_ 1457 NBCAmbientLightColour 0;
BA_ "InitialValue" SG_ 1457 NBCAmbientLightNightEnable 1;
BA_ "GenSigStartValue" SG_ 1457 NBCAmbientLightNightEnable 1;
BA_ "GenSigSendType" SG_ 1457 NBCAmbientLightNightEnable 3;
BA_ "EventTrans" SG_ 1457 NBCAmbientLightNightEnable 0;
BA_ "GenSigSendType" SG_ 1457 NBC_DimmingLevelRoof3 3;
BA_ "EventTrans" SG_ 1457 NBC_DimmingLevelRoof3 0;
BA_ "GenSigSendType" SG_ 1457 NBC_DimmingLevelRoof2 3;
BA_ "EventTrans" SG_ 1457 NBC_DimmingLevelRoof2 0;
BA_ "GenSigSendType" SG_ 1457 NBCAmbientLightResponseError 3;
BA_ "EventTrans" SG_ 1457 NBCAmbientLightResponseError 0;
BA_ "InitialValue" SG_ 1457 NBCAmbientLightEnable 1;
BA_ "GenSigStartValue" SG_ 1457 NBCAmbientLightEnable 1;
BA_ "GenSigSendType" SG_ 1457 NBCAmbientLightEnable 3;
BA_ "EventTrans" SG_ 1457 NBCAmbientLightEnable 0;
BA_ "GenSigSendType" SG_ 1457 NBC_DimmingLevelRoof5 3;
BA_ "EventTrans" SG_ 1457 NBC_DimmingLevelRoof5 0;
BA_ "GenSigSendType" SG_ 1457 NBC_DimmingLevelRoof4 3;
BA_ "EventTrans" SG_ 1457 NBC_DimmingLevelRoof4 0;
BA_ "GenSigSendType" SG_ 1457 NBCAmbientLightGenericFailSts 3;
BA_ "EventTrans" SG_ 1457 NBCAmbientLightGenericFailSts 0;
BA_ "GenSigSendType" SG_ 1457 NBCAmbientLightCurrentFailSts 3;
BA_ "EventTrans" SG_ 1457 NBCAmbientLightCurrentFailSts 0;
BA_ "GenSigSendType" SG_ 1457 WiperWaterLevelLampSts 3;
BA_ "EventTrans" SG_ 1457 WiperWaterLevelLampSts 0;
BA_ "GenSigSendType" SG_ 1457 WiperWaterLowLevel 3;
BA_ "EventTrans" SG_ 1457 WiperWaterLowLevel 0;
BA_ "GenSigSendType" SG_ 1457 NBC_DimmingLevelRoof6 3;
BA_ "EventTrans" SG_ 1457 NBC_DimmingLevelRoof6 0;
BA_ "GenSigSendType" SG_ 1457 NVDFailSts 3;
BA_ "EventTrans" SG_ 1457 NVDFailSts 0;
BA_ "GenSigSendType" SG_ 1458 DriverMassageLevel 3;
BA_ "EventTrans" SG_ 1458 DriverMassageLevel 0;
BA_ "GenSigSendType" SG_ 1458 DriverAirScarf 3;
BA_ "EventTrans" SG_ 1458 DriverAirScarf 0;
BA_ "GenSigSendType" SG_ 1458 FrontDriverHeating 3;
BA_ "EventTrans" SG_ 1458 FrontDriverHeating 0;
BA_ "GenSigSendType" SG_ 1458 DriverFans 3;
BA_ "EventTrans" SG_ 1458 DriverFans 0;
BA_ "GenSigSendType" SG_ 1458 DriverMassageType 3;
BA_ "EventTrans" SG_ 1458 DriverMassageType 0;
BA_ "InitialValue" SG_ 1458 Driver_SeatTemperature -10;
BA_ "GenSigSendType" SG_ 1458 Driver_SeatTemperature 3;
BA_ "EventTrans" SG_ 1458 Driver_SeatTemperature 0;
BA_ "GenSigSendType" SG_ 1458 ColumnProfileSts 3;
BA_ "EventTrans" SG_ 1458 ColumnProfileSts 0;
BA_ "GenSigSendType" SG_ 1463 PsngrMassageLevel 3;
BA_ "EventTrans" SG_ 1463 PsngrMassageLevel 0;
BA_ "GenSigSendType" SG_ 1463 PsngrAirScarf 3;
BA_ "EventTrans" SG_ 1463 PsngrAirScarf 0;
BA_ "GenSigSendType" SG_ 1463 FrontPassengerHeating 3;
BA_ "EventTrans" SG_ 1463 FrontPassengerHeating 0;
BA_ "GenSigSendType" SG_ 1463 PassengerFans 3;
BA_ "EventTrans" SG_ 1463 PassengerFans 0;
BA_ "GenSigSendType" SG_ 1463 PsngrMassageType 3;
BA_ "EventTrans" SG_ 1463 PsngrMassageType 0;
BA_ "InitialValue" SG_ 1463 Psngr_SeatTemperature -10;
BA_ "GenSigSendType" SG_ 1463 Psngr_SeatTemperature 3;
BA_ "EventTrans" SG_ 1463 Psngr_SeatTemperature 0;
BA_ "GenSigSendType" SG_ 1464 SeatProfileSts 3;
BA_ "EventTrans" SG_ 1464 SeatProfileSts 0;
BA_ "GenSigSendType" SG_ 1464 DriverSeatSetupReq 3;
BA_ "EventTrans" SG_ 1464 DriverSeatSetupReq 0;
BA_ "GenSigSendType" SG_ 1464 DriverSeatLengthFbk 3;
BA_ "EventTrans" SG_ 1464 DriverSeatLengthFbk 0;
BA_ "GenSigSendType" SG_ 1465 PsngrSeatBackRestPos 3;
BA_ "EventTrans" SG_ 1465 PsngrSeatBackRestPos 0;
BA_ "GenSigSendType" SG_ 1465 PsngrSeatSetupReq 3;
BA_ "EventTrans" SG_ 1465 PsngrSeatSetupReq 0;
BA_ "GenSigSendType" SG_ 1465 PsngrSeatLengthFbk 3;
BA_ "EventTrans" SG_ 1465 PsngrSeatLengthFbk 0;
BA_ "GenSigSendType" SG_ 1465 PsngrSeatLongitudinalPos 3;
BA_ "EventTrans" SG_ 1465 PsngrSeatLongitudinalPos 0;
BA_ "GenSigSendType" SG_ 1465 PsngrSeatTiltPos 3;
BA_ "EventTrans" SG_ 1465 PsngrSeatTiltPos 0;
BA_ "GenSigSendType" SG_ 1465 PsngrSeatLiftPos 3;
BA_ "EventTrans" SG_ 1465 PsngrSeatLiftPos 0;
BA_ "InitialValue" SG_ 1485 LongParkingSts 1;
BA_ "GenSigStartValue" SG_ 1485 LongParkingSts 1;
BA_ "InitialValue" SG_ 1533 Fdbk_Pos_Hor_LH_Exmi 255;
BA_ "GenSigStartValue" SG_ 1533 Fdbk_Pos_Hor_LH_Exmi 255;
BA_ "InitialValue" SG_ 1533 Fdbk_Pos_Ver_LH_Exmi 255;
BA_ "GenSigStartValue" SG_ 1533 Fdbk_Pos_Ver_LH_Exmi 255;
BA_ "InitialValue" SG_ 1533 Fdbk_Pos_Hor_RH_Exmi 255;
BA_ "GenSigStartValue" SG_ 1533 Fdbk_Pos_Hor_RH_Exmi 255;
BA_ "InitialValue" SG_ 1533 Fdbk_Pos_Ver_RH_Exmi 255;
BA_ "GenSigStartValue" SG_ 1533 Fdbk_Pos_Ver_RH_Exmi 255;
BA_ "GenSigSendType" SG_ 1533 MirrorsProfileSts 3;
BA_ "EventTrans" SG_ 1533 MirrorsProfileSts 0;
BA_ "SignalAge" SG_ 1539 TotalOdometer 1000;
BA_ "Accuracy" SG_ 1539 TotalOdometer "N/A";
BA_ "GenSigSendType" SG_ 1566 CommandWord 1;
BA_ "EventTrans" SG_ 1566 CommandWord 0;
BA_ "GenSigSendType" SG_ 1566 CommandParameter1 1;
BA_ "EventTrans" SG_ 1566 CommandParameter1 0;
BA_ "GenSigSendType" SG_ 1566 CommandParameter2 1;
BA_ "EventTrans" SG_ 1566 CommandParameter2 0;
BA_ "GenSigSendType" SG_ 1566 CommandParameter3 1;
BA_ "EventTrans" SG_ 1566 CommandParameter3 0;
BA_ "GenSigSendType" SG_ 1566 CommandParameter4 1;
BA_ "EventTrans" SG_ 1566 CommandParameter4 0;
BA_ "GenSigSendType" SG_ 1566 CommandParameter5 1;
BA_ "EventTrans" SG_ 1566 CommandParameter5 0;
BA_ "GenSigSendType" SG_ 1566 CommandParameter6 1;
BA_ "EventTrans" SG_ 1566 CommandParameter6 0;
BA_ "GenSigStartValue" SG_ 1673 CabinTemperature 40;
BA_ "GenSigSendType" SG_ 1696 Hour2 3;
BA_ "EventTrans" SG_ 1696 Hour2 0;
BA_ "GenSigSendType" SG_ 1696 Hour1 3;
BA_ "EventTrans" SG_ 1696 Hour1 0;
BA_ "GenSigSendType" SG_ 1696 Minute2 3;
BA_ "EventTrans" SG_ 1696 Minute2 0;
BA_ "GenSigSendType" SG_ 1696 Minute1 3;
BA_ "EventTrans" SG_ 1696 Minute1 0;
BA_ "GenSigSendType" SG_ 1696 Day2 3;
BA_ "EventTrans" SG_ 1696 Day2 0;
BA_ "GenSigSendType" SG_ 1696 Day1 3;
BA_ "EventTrans" SG_ 1696 Day1 0;
BA_ "GenSigSendType" SG_ 1696 Month2 3;
BA_ "EventTrans" SG_ 1696 Month2 0;
BA_ "GenSigSendType" SG_ 1696 Month1 3;
BA_ "EventTrans" SG_ 1696 Month1 0;
BA_ "GenSigSendType" SG_ 1696 Year2 3;
BA_ "EventTrans" SG_ 1696 Year2 0;
BA_ "GenSigSendType" SG_ 1696 Year1 3;
BA_ "EventTrans" SG_ 1696 Year1 0;
BA_ "GenSigSendType" SG_ 1696 Year4 3;
BA_ "EventTrans" SG_ 1696 Year4 0;
BA_ "GenSigSendType" SG_ 1696 Year3 3;
BA_ "EventTrans" SG_ 1696 Year3 0;
BA_ "GenSigSendType" SG_ 1726 CabinLightNightDaySwitch 3;
BA_ "EventTrans" SG_ 1726 CabinLightNightDaySwitch 0;
BA_ "GenSigSendType" SG_ 1726 CabinLight_Feet_Enable 3;
BA_ "EventTrans" SG_ 1726 CabinLight_Feet_Enable 0;
BA_ "GenSigSendType" SG_ 1726 CabinLight_DoorPanel_Enable 3;
BA_ "EventTrans" SG_ 1726 CabinLight_DoorPanel_Enable 0;
BA_ "GenSigSendType" SG_ 1726 AutoDoorsAlert 3;
BA_ "EventTrans" SG_ 1726 AutoDoorsAlert 0;
BA_ "GenSigSendType" SG_ 1726 EManettinoPreset 3;
BA_ "EventTrans" SG_ 1726 EManettinoPreset 0;
BA_ "GenSigSendType" SG_ 1726 SmartOverbrakingEnable 3;
BA_ "EventTrans" SG_ 1726 SmartOverbrakingEnable 0;
BA_ "GenSigSendType" SG_ 1726 CabinLight_Feet_Level 3;
BA_ "EventTrans" SG_ 1726 CabinLight_Feet_Level 0;
BA_ "GenSigSendType" SG_ 1726 CabinLight_DoorPanel_Level 3;
BA_ "EventTrans" SG_ 1726 CabinLight_DoorPanel_Level 0;
BA_ "GenSigSendType" SG_ 1726 InternalLightEnable 3;
BA_ "EventTrans" SG_ 1726 InternalLightEnable 0;
BA_ "GenSigSendType" SG_ 1726 ChargePlugAutoUnlock 3;
BA_ "EventTrans" SG_ 1726 ChargePlugAutoUnlock 0;
BA_ "GenSigSendType" SG_ 1726 ActiveProfile 3;
BA_ "EventTrans" SG_ 1726 ActiveProfile 0;
BA_ "GenSigSendType" SG_ 1726 User_Max_SOC 3;
BA_ "EventTrans" SG_ 1726 User_Max_SOC 0;
BA_ "GenSigSendType" SG_ 1726 PassiveEntryEnable 3;
BA_ "EventTrans" SG_ 1726 PassiveEntryEnable 0;
BA_ "GenSigSendType" SG_ 1726 PresentProfile 3;
BA_ "EventTrans" SG_ 1726 PresentProfile 0;
BA_ "GenSigSendType" SG_ 1726 PersonalDataConsentSts 3;
BA_ "EventTrans" SG_ 1726 PersonalDataConsentSts 0;
BA_ "GenSigSendType" SG_ 1726 StealthModeActive 3;
BA_ "EventTrans" SG_ 1726 StealthModeActive 0;
BA_ "GenSigSendType" SG_ 1726 User_SOC_Preset 3;
BA_ "EventTrans" SG_ 1726 User_SOC_Preset 0;
BA_ "GenSigSendType" SG_ 1726 ChargeFlapUnlock 3;
BA_ "EventTrans" SG_ 1726 ChargeFlapUnlock 0;
BA_ "GenSigSendType" SG_ 1726 AntiTiltAlarmCommand 3;
BA_ "EventTrans" SG_ 1726 AntiTiltAlarmCommand 0;
BA_ "GenSigSendType" SG_ 1735 NPRSts 3;
BA_ "EventTrans" SG_ 1735 NPRSts 0;
BA_ "GenSigSendType" SG_ 1735 NPRFailSts 3;
BA_ "EventTrans" SG_ 1735 NPRFailSts 0;
BA_ "GenSigSendType" SG_ 1735 NPRCurrentConsumption 3;
BA_ "EventTrans" SG_ 1735 NPRCurrentConsumption 0;
BA_ "GenSigSendType" SG_ 1735 NPRActualVoltage 3;
BA_ "EventTrans" SG_ 1735 NPRActualVoltage 0;
BA_ "GenSigSendType" SG_ 1735 NPRLoadFailSts 3;
BA_ "EventTrans" SG_ 1735 NPRLoadFailSts 0;
BA_ "GenSigSendType" SG_ 1735 NPR48VFailSts 3;
BA_ "EventTrans" SG_ 1735 NPR48VFailSts 0;
BA_ "GenSigSendType" SG_ 1735 GLASS_TEMP_NPR 3;
BA_ "EventTrans" SG_ 1735 GLASS_TEMP_NPR 0;
BA_ "GenSigSendType" SG_ 1735 NPRMaxVoltBus48 3;
BA_ "EventTrans" SG_ 1735 NPRMaxVoltBus48 0;
BA_ "GenSigSendType" SG_ 1752 WCM_Status 3;
BA_ "EventTrans" SG_ 1752 WCM_Status 0;
BA_ "InitialValue" SG_ 1764 FSFCWPlusActivationMode 3;
BA_ "GenSigStartValue" SG_ 1764 FSFCWPlusActivationMode 3;
BA_ "GenSigSendType" SG_ 1764 FSFCWPlusActivationMode 3;
BA_ "EventTrans" SG_ 1764 FSFCWPlusActivationMode 0;
BA_ "InitialValue" SG_ 1764 FSFCWPlusSetting 4;
BA_ "GenSigStartValue" SG_ 1764 FSFCWPlusSetting 4;
BA_ "GenSigSendType" SG_ 1764 FSFCWPlusSetting 3;
BA_ "EventTrans" SG_ 1764 FSFCWPlusSetting 0;
BA_ "GenSigSendType" SG_ 1764 AutoHighBeamEnable 3;
BA_ "EventTrans" SG_ 1764 AutoHighBeamEnable 0;
BA_ "InitialValue" SG_ 1764 LDW_Sensibility 3;
BA_ "GenSigStartValue" SG_ 1764 LDW_Sensibility 3;
BA_ "GenSigSendType" SG_ 1764 LDW_Sensibility 3;
BA_ "EventTrans" SG_ 1764 LDW_Sensibility 0;
BA_ "GenSigSendType" SG_ 1764 LDWRequestSts 3;
BA_ "EventTrans" SG_ 1764 LDWRequestSts 0;
BA_ "GenSigSendType" SG_ 1764 TSREnable 3;
BA_ "EventTrans" SG_ 1764 TSREnable 0;
BA_ "InitialValue" SG_ 1764 LDWWarningType 3;
BA_ "GenSigStartValue" SG_ 1764 LDWWarningType 3;
BA_ "GenSigSendType" SG_ 1764 LDWWarningType 3;
BA_ "EventTrans" SG_ 1764 LDWWarningType 0;
BA_ "GenSigSendType" SG_ 1764 DistanceUnit 3;
BA_ "EventTrans" SG_ 1764 DistanceUnit 0;
BA_ "GenSigSendType" SG_ 1764 AFSEnable 3;
BA_ "EventTrans" SG_ 1764 AFSEnable 0;
BA_ "InitialValue" SG_ 1764 BSDEnable 3;
BA_ "GenSigStartValue" SG_ 1764 BSDEnable 3;
BA_ "GenSigSendType" SG_ 1764 BSDEnable 3;
BA_ "EventTrans" SG_ 1764 BSDEnable 0;
BA_ "GenSigSendType" SG_ 1764 HDC_Enable 3;
BA_ "EventTrans" SG_ 1764 HDC_Enable 0;
BA_ "InitialValue" SG_ 1764 LDWAssistType 1;
BA_ "GenSigStartValue" SG_ 1764 LDWAssistType 1;
BA_ "GenSigSendType" SG_ 1764 LDWAssistType 3;
BA_ "EventTrans" SG_ 1764 LDWAssistType 0;
BA_ "InitialValue" SG_ 1764 ACC_DistCmd 5;
BA_ "GenSigStartValue" SG_ 1764 ACC_DistCmd 5;
BA_ "GenSigSendType" SG_ 1764 ACC_DistCmd 3;
BA_ "EventTrans" SG_ 1764 ACC_DistCmd 0;
BA_ "GenSigSendType" SG_ 1767 LanguageSelection 3;
BA_ "EventTrans" SG_ 1767 LanguageSelection 0;
BA_ "GenSigSendType" SG_ 1767 TemperatureUnit 3;
BA_ "EventTrans" SG_ 1767 TemperatureUnit 0;
BA_ "GenSigSendType" SG_ 1767 DistanceUnit 3;
BA_ "EventTrans" SG_ 1767 DistanceUnit 0;
BA_ "GenSigSendType" SG_ 1767 AutomaticMirrorFoldingEnable 3;
BA_ "EventTrans" SG_ 1767 AutomaticMirrorFoldingEnable 0;
BA_ "GenSigSendType" SG_ 1767 HourMode 3;
BA_ "EventTrans" SG_ 1767 HourMode 0;
BA_ "GenSigSendType" SG_ 1767 WiperRLSSensibility 3;
BA_ "EventTrans" SG_ 1767 WiperRLSSensibility 0;
BA_ "GenSigSendType" SG_ 1767 WelcomeInCarEnable 3;
BA_ "EventTrans" SG_ 1767 WelcomeInCarEnable 0;
BA_ "InitialValue" SG_ 1767 BuzzerVolumeWarning 4;
BA_ "GenSigStartValue" SG_ 1767 BuzzerVolumeWarning 4;
BA_ "GenSigSendType" SG_ 1767 BuzzerVolumeWarning 3;
BA_ "EventTrans" SG_ 1767 BuzzerVolumeWarning 0;
BA_ "GenSigSendType" SG_ 1767 SpeedThreshold 3;
BA_ "EventTrans" SG_ 1767 SpeedThreshold 0;
BA_ "Accuracy" SG_ 1767 SpeedThreshold "N/A";
BA_ "InitialValue" SG_ 1767 LockTimeout 3;
BA_ "GenSigStartValue" SG_ 1767 LockTimeout 3;
BA_ "GenSigSendType" SG_ 1767 LockTimeout 3;
BA_ "GenSigSendType" SG_ 1767 ResetTripAReq 3;
BA_ "EventTrans" SG_ 1767 ResetTripAReq 0;
BA_ "GenSigSendType" SG_ 1767 DriverDoorUnlockEnable 3;
BA_ "EventTrans" SG_ 1767 DriverDoorUnlockEnable 0;
BA_ "GenSigSendType" SG_ 1767 SpeedLockDoorEnable 3;
BA_ "EventTrans" SG_ 1767 SpeedLockDoorEnable 0;
BA_ "InitialValue" SG_ 1767 ExternalLightSensorLevel 1;
BA_ "GenSigStartValue" SG_ 1767 ExternalLightSensorLevel 1;
BA_ "GenSigSendType" SG_ 1767 ExternalLightSensorLevel 3;
BA_ "EventTrans" SG_ 1767 ExternalLightSensorLevel 0;
BA_ "GenSigSendType" SG_ 1767 SpeedThresholdEnable 3;
BA_ "EventTrans" SG_ 1767 SpeedThresholdEnable 0;
BA_ "InitialValue" SG_ 1767 WalkAwayEnabled 1;
BA_ "GenSigStartValue" SG_ 1767 WalkAwayEnabled 1;
BA_ "GenSigSendType" SG_ 1767 WalkAwayEnabled 3;
BA_ "EventTrans" SG_ 1767 WalkAwayEnabled 0;
BA_ "GenSigSendType" SG_ 1767 GloveBoxUnlockEnable 3;
BA_ "EventTrans" SG_ 1767 GloveBoxUnlockEnable 0;
BA_ "GenSigSendType" SG_ 1767 Stop_GoEnable 3;
BA_ "EventTrans" SG_ 1767 Stop_GoEnable 0;
BA_ "GenSigSendType" SG_ 1767 EngineSpeedDisplayLedEnable 3;
BA_ "EventTrans" SG_ 1767 EngineSpeedDisplayLedEnable 0;
BA_ "GenSigSendType" SG_ 1767 SnowChainMode 3;
BA_ "EventTrans" SG_ 1767 SnowChainMode 0;
BA_ "GenSigSendType" SG_ 1767 PressureUnit 3;
BA_ "EventTrans" SG_ 1767 PressureUnit 0;
BA_ "InitialValue" SG_ 1767 RPMAreaColor 2;
BA_ "GenSigStartValue" SG_ 1767 RPMAreaColor 2;
BA_ "GenSigSendType" SG_ 1767 RPMAreaColor 3;
BA_ "EventTrans" SG_ 1767 RPMAreaColor 0;
BA_ "GenSigSendType" SG_ 1767 NTPCalibrationReqSts 3;
BA_ "EventTrans" SG_ 1767 NTPCalibrationReqSts 0;
BA_ "GenSigSendType" SG_ 1767 EmergencyStopSignallingEnable 3;
BA_ "EventTrans" SG_ 1767 EmergencyStopSignallingEnable 0;
BA_ "InitialValue" SG_ 1767 RearAutoDoorAlert 1;
BA_ "GenSigStartValue" SG_ 1767 RearAutoDoorAlert 1;
BA_ "GenSigSendType" SG_ 1767 RearAutoDoorAlert 3;
BA_ "EventTrans" SG_ 1767 RearAutoDoorAlert 0;
BA_ "GenSigSendType" SG_ 1767 MirrorAutoTiltEnable 3;
BA_ "EventTrans" SG_ 1767 MirrorAutoTiltEnable 0;
BA_ "GenSigSendType" SG_ 1767 SpeedLimitSignEnable 3;
BA_ "EventTrans" SG_ 1767 SpeedLimitSignEnable 0;
BA_ "GenSigSendType" SG_ 1767 TrafficChangeEnable 3;
BA_ "EventTrans" SG_ 1767 TrafficChangeEnable 0;
BA_ "InitialValue" SG_ 1767 AutolockEnable 1;
BA_ "GenSigStartValue" SG_ 1767 AutolockEnable 1;
BA_ "GenSigSendType" SG_ 1767 AutolockEnable 3;
BA_ "EventTrans" SG_ 1767 AutolockEnable 0;
BA_ "GenSigSendType" SG_ 1772 SingleDoorUnlockEnable 3;
BA_ "EventTrans" SG_ 1772 SingleDoorUnlockEnable 0;
BA_ "InitialValue" SG_ 1772 LongParkingSetting 3;
BA_ "GenSigStartValue" SG_ 1772 LongParkingSetting 3;
BA_ "GenSigSendType" SG_ 1772 LongParkingSetting 3;
BA_ "EventTrans" SG_ 1772 LongParkingSetting 0;
BA_ "GenSigSendType" SG_ 1772 FeetLightKeyOnActivation 3;
BA_ "EventTrans" SG_ 1772 FeetLightKeyOnActivation 0;
BA_ "InitialValue" SG_ 1772 AmbientLightEnable 1;
BA_ "GenSigStartValue" SG_ 1772 AmbientLightEnable 1;
BA_ "GenSigSendType" SG_ 1772 AmbientLightEnable 3;
BA_ "EventTrans" SG_ 1772 AmbientLightEnable 0;
BA_ "GenSigSendType" SG_ 1772 ShowOnDisplay_Seats 3;
BA_ "EventTrans" SG_ 1772 ShowOnDisplay_Seats 0;
BA_ "GenSigSendType" SG_ 1772 ShowOnDisplay_Climate 3;
BA_ "EventTrans" SG_ 1772 ShowOnDisplay_Climate 0;
BA_ "GenSigSendType" SG_ 1772 ShowOnDisplay_Time_Temperature 3;
BA_ "EventTrans" SG_ 1772 ShowOnDisplay_Time_Temperature 0;
BA_ "InitialValue" SG_ 1772 NIT_PassengerExtendedClimate 3;
BA_ "GenSigStartValue" SG_ 1772 NIT_PassengerExtendedClimate 3;
BA_ "GenSigSendType" SG_ 1772 NIT_PassengerExtendedClimate 3;
BA_ "EventTrans" SG_ 1772 NIT_PassengerExtendedClimate 0;
BA_ "InitialValue" SG_ 1772 NIT_DriverExtendedClimate 3;
BA_ "GenSigStartValue" SG_ 1772 NIT_DriverExtendedClimate 3;
BA_ "GenSigSendType" SG_ 1772 NIT_DriverExtendedClimate 3;
BA_ "EventTrans" SG_ 1772 NIT_DriverExtendedClimate 0;
BA_ "GenSigSendType" SG_ 1772 RimHeating_Profile 3;
BA_ "EventTrans" SG_ 1772 RimHeating_Profile 0;
BA_ "GenSigSendType" SG_ 1772 LiftGateAlertEnable 3;
BA_ "EventTrans" SG_ 1772 LiftGateAlertEnable 0;
BA_ "GenSigSendType" SG_ 1772 NIT_RearPassengerExtendedClimate 3;
BA_ "EventTrans" SG_ 1772 NIT_RearPassengerExtendedClimate 0;
BA_ "GenSigSendType" SG_ 1772 Battery_Saving 3;
BA_ "EventTrans" SG_ 1772 Battery_Saving 0;
BA_ "GenSigSendType" SG_ 1772 GmeterReset 3;
BA_ "EventTrans" SG_ 1772 GmeterReset 0;
BA_ "InitialValue" SG_ 1772 SoundFeedbackLevel 2;
BA_ "GenSigStartValue" SG_ 1772 SoundFeedbackLevel 2;
BA_ "GenSigSendType" SG_ 1772 SoundFeedbackLevel 3;
BA_ "EventTrans" SG_ 1772 SoundFeedbackLevel 0;
BA_ "GenSigSendType" SG_ 1772 LongParkingUserAction 3;
BA_ "EventTrans" SG_ 1772 LongParkingUserAction 0;
BA_ "GenSigSendType" SG_ 1792 SystemCommand 3;
BA_ "EventTrans" SG_ 1792 SystemCommand 0;
BA_ "GenSigSendType" SG_ 1796 SystemStatus 3;
BA_ "EventTrans" SG_ 1796 SystemStatus 0;
BA_ "GenSigSendType" SG_ 1801 SystemStatus 3;
BA_ "EventTrans" SG_ 1801 SystemStatus 0;
BA_ "GenSigSendType" SG_ 1802 SystemStatus 3;
BA_ "EventTrans" SG_ 1802 SystemStatus 0;
BA_ "GenSigSendType" SG_ 1810 SystemStatus 3;
BA_ "EventTrans" SG_ 1810 SystemStatus 0;
BA_ "GenSigSendType" SG_ 1815 SystemStatus 3;
BA_ "EventTrans" SG_ 1815 SystemStatus 0;
BA_ "GenSigSendType" SG_ 1816 SystemStatus 3;
BA_ "EventTrans" SG_ 1816 SystemStatus 0;
BA_ "GenSigSendType" SG_ 1823 SystemStatus 3;
BA_ "EventTrans" SG_ 1823 SystemStatus 0;
BA_ "GenSigSendType" SG_ 1860 Digit_10 1;
BA_ "EventTrans" SG_ 1860 Digit_10 0;
BA_ "GenSigSendType" SG_ 1860 Digit_11 1;
BA_ "EventTrans" SG_ 1860 Digit_11 0;
BA_ "GenSigSendType" SG_ 1860 Digit_08 1;
BA_ "EventTrans" SG_ 1860 Digit_08 0;
BA_ "GenSigSendType" SG_ 1860 Digit_09 1;
BA_ "EventTrans" SG_ 1860 Digit_09 0;
BA_ "GenSigSendType" SG_ 1860 Digit_06 1;
BA_ "EventTrans" SG_ 1860 Digit_06 0;
BA_ "GenSigSendType" SG_ 1860 Digit_07 1;
BA_ "EventTrans" SG_ 1860 Digit_07 0;
BA_ "GenSigSendType" SG_ 1860 Digit_04 1;
BA_ "EventTrans" SG_ 1860 Digit_04 0;
BA_ "GenSigSendType" SG_ 1860 Digit_05 1;
BA_ "EventTrans" SG_ 1860 Digit_05 0;
BA_ "GenSigSendType" SG_ 1860 Digit_02 1;
BA_ "EventTrans" SG_ 1860 Digit_02 0;
BA_ "GenSigSendType" SG_ 1860 Digit_03 1;
BA_ "EventTrans" SG_ 1860 Digit_03 0;
BA_ "GenSigSendType" SG_ 1860 Digit_01 1;
BA_ "EventTrans" SG_ 1860 Digit_01 0;
BA_ "GenSigSendType" SG_ 1865 Digit_10 1;
BA_ "EventTrans" SG_ 1865 Digit_10 0;
BA_ "GenSigSendType" SG_ 1865 Digit_11 1;
BA_ "EventTrans" SG_ 1865 Digit_11 0;
BA_ "GenSigSendType" SG_ 1865 Digit_08 1;
BA_ "EventTrans" SG_ 1865 Digit_08 0;
BA_ "GenSigSendType" SG_ 1865 Digit_09 1;
BA_ "EventTrans" SG_ 1865 Digit_09 0;
BA_ "GenSigSendType" SG_ 1865 Digit_06 1;
BA_ "EventTrans" SG_ 1865 Digit_06 0;
BA_ "GenSigSendType" SG_ 1865 Digit_07 1;
BA_ "EventTrans" SG_ 1865 Digit_07 0;
BA_ "GenSigSendType" SG_ 1865 Digit_04 1;
BA_ "EventTrans" SG_ 1865 Digit_04 0;
BA_ "GenSigSendType" SG_ 1865 Digit_05 1;
BA_ "EventTrans" SG_ 1865 Digit_05 0;
BA_ "GenSigSendType" SG_ 1865 Digit_02 1;
BA_ "EventTrans" SG_ 1865 Digit_02 0;
BA_ "GenSigSendType" SG_ 1865 Digit_03 1;
BA_ "EventTrans" SG_ 1865 Digit_03 0;
BA_ "GenSigSendType" SG_ 1865 Digit_01 1;
BA_ "EventTrans" SG_ 1865 Digit_01 0;
BA_ "GenSigSendType" SG_ 1880 Digit_10 1;
BA_ "EventTrans" SG_ 1880 Digit_10 0;
BA_ "GenSigSendType" SG_ 1880 Digit_11 1;
BA_ "EventTrans" SG_ 1880 Digit_11 0;
BA_ "GenSigSendType" SG_ 1880 Digit_08 1;
BA_ "EventTrans" SG_ 1880 Digit_08 0;
BA_ "GenSigSendType" SG_ 1880 Digit_09 1;
BA_ "EventTrans" SG_ 1880 Digit_09 0;
BA_ "GenSigSendType" SG_ 1880 Digit_06 1;
BA_ "EventTrans" SG_ 1880 Digit_06 0;
BA_ "GenSigSendType" SG_ 1880 Digit_07 1;
BA_ "EventTrans" SG_ 1880 Digit_07 0;
BA_ "GenSigSendType" SG_ 1880 Digit_04 1;
BA_ "EventTrans" SG_ 1880 Digit_04 0;
BA_ "GenSigSendType" SG_ 1880 Digit_05 1;
BA_ "EventTrans" SG_ 1880 Digit_05 0;
BA_ "GenSigSendType" SG_ 1880 Digit_02 1;
BA_ "EventTrans" SG_ 1880 Digit_02 0;
BA_ "GenSigSendType" SG_ 1880 Digit_03 1;
BA_ "EventTrans" SG_ 1880 Digit_03 0;
BA_ "GenSigSendType" SG_ 1880 Digit_01 1;
BA_ "EventTrans" SG_ 1880 Digit_01 0;
BA_ "GenSigSendType" SG_ 2564425969 UDS_SGW_NCL_PhyReq_Data 1;
BA_ "GenSigSendType" SG_ 2564430577 UDS_SGW_NAG_PhysReq_Data 1;
BA_ "GenSigSendType" SG_ 2564448241 UDS_SGW_RSR_PhyReq_Data 1;
BA_ "GenSigSendType" SG_ 2564453105 UDS_SGW_ELR_PhysReq_Data 1;
BA_ "GenSigSendType" SG_ 2564453361 UDS_SGW_ELL_PhysReq_Data 1;
BA_ "GenSigSendType" SG_ 2564455665 UDS_SGW_ERL_PhysReq_Data 1;
BA_ "GenSigSendType" SG_ 2564460529 UDS_SGW_NVO_PhyReq_Data 1;
BA_ "GenSigSendType" SG_ 2564463601 UDS_SGW_NAP_PhyReq_Data 1;
BA_ "GenSigSendType" SG_ 2564485384 UDS_NCL_SGW_PhyRes_Data 1;
BA_ "GenSigSendType" SG_ 2564485402 UDS_NAG_SGW_PhyRes_Data 1;
BA_ "GenSigSendType" SG_ 2564485471 UDS_RSR_SGW_PhyRes_Data 1;
BA_ "GenSigSendType" SG_ 2564485490 UDS_ELR_SGW_PhyRes_Data 1;
BA_ "GenSigSendType" SG_ 2564485491 UDS_ELL_SGW_PhyRes_Data 1;
BA_ "GenSigSendType" SG_ 2564485519 UDS_NVO_SGW_PhyRes_Data 1;
BA_ "GenSigSendType" SG_ 2564485531 UDS_NAP_SGW_PhyRes_Data 1;
BA_ "GenSigSendType" SG_ 2564554481 UDS_OBD_to_ALL_FunctionalRequest 1;
BA_ "GenSigSendType" SG_ 2651930624 Digit_10 1;
BA_ "EventTrans" SG_ 2651930624 Digit_10 0;
BA_ "GenSigSendType" SG_ 2651930624 Digit_11 1;
BA_ "EventTrans" SG_ 2651930624 Digit_11 0;
BA_ "GenSigSendType" SG_ 2651930624 Digit_08 1;
BA_ "EventTrans" SG_ 2651930624 Digit_08 0;
BA_ "GenSigSendType" SG_ 2651930624 Digit_09 1;
BA_ "EventTrans" SG_ 2651930624 Digit_09 0;
BA_ "GenSigSendType" SG_ 2651930624 Digit_06 1;
BA_ "EventTrans" SG_ 2651930624 Digit_06 0;
BA_ "GenSigSendType" SG_ 2651930624 Digit_07 1;
BA_ "EventTrans" SG_ 2651930624 Digit_07 0;
BA_ "GenSigSendType" SG_ 2651930624 Digit_04 1;
BA_ "EventTrans" SG_ 2651930624 Digit_04 0;
BA_ "GenSigSendType" SG_ 2651930624 Digit_05 1;
BA_ "EventTrans" SG_ 2651930624 Digit_05 0;
BA_ "GenSigSendType" SG_ 2651930624 Digit_02 1;
BA_ "EventTrans" SG_ 2651930624 Digit_02 0;
BA_ "GenSigSendType" SG_ 2651930624 Digit_03 1;
BA_ "EventTrans" SG_ 2651930624 Digit_03 0;
BA_ "GenSigSendType" SG_ 2651930624 Digit_01 1;
BA_ "EventTrans" SG_ 2651930624 Digit_01 0;
BA_ "GenSigSendType" SG_ 2651930650 Digit_10 1;
BA_ "EventTrans" SG_ 2651930650 Digit_10 0;
BA_ "GenSigSendType" SG_ 2651930650 Digit_11 1;
BA_ "EventTrans" SG_ 2651930650 Digit_11 0;
BA_ "GenSigSendType" SG_ 2651930650 Digit_08 1;
BA_ "EventTrans" SG_ 2651930650 Digit_08 0;
BA_ "GenSigSendType" SG_ 2651930650 Digit_09 1;
BA_ "EventTrans" SG_ 2651930650 Digit_09 0;
BA_ "GenSigSendType" SG_ 2651930650 Digit_06 1;
BA_ "EventTrans" SG_ 2651930650 Digit_06 0;
BA_ "GenSigSendType" SG_ 2651930650 Digit_07 1;
BA_ "EventTrans" SG_ 2651930650 Digit_07 0;
BA_ "GenSigSendType" SG_ 2651930650 Digit_04 1;
BA_ "EventTrans" SG_ 2651930650 Digit_04 0;
BA_ "GenSigSendType" SG_ 2651930650 Digit_05 1;
BA_ "EventTrans" SG_ 2651930650 Digit_05 0;
BA_ "GenSigSendType" SG_ 2651930650 Digit_02 1;
BA_ "EventTrans" SG_ 2651930650 Digit_02 0;
BA_ "GenSigSendType" SG_ 2651930650 Digit_03 1;
BA_ "EventTrans" SG_ 2651930650 Digit_03 0;
BA_ "GenSigSendType" SG_ 2651930650 Digit_01 1;
BA_ "EventTrans" SG_ 2651930650 Digit_01 0;
BA_ "GenSigSendType" SG_ 2651930679 Digit_10_LBSS 1;
BA_ "EventTrans" SG_ 2651930679 Digit_10_LBSS 0;
BA_ "Accuracy" SG_ 2651930679 Digit_10_LBSS "?—";
BA_ "GenSigSendType" SG_ 2651930679 Digit_11_LBSS 1;
BA_ "EventTrans" SG_ 2651930679 Digit_11_LBSS 0;
BA_ "Accuracy" SG_ 2651930679 Digit_11_LBSS "?—";
BA_ "GenSigSendType" SG_ 2651930679 Digit_08_LBSS 1;
BA_ "EventTrans" SG_ 2651930679 Digit_08_LBSS 0;
BA_ "Accuracy" SG_ 2651930679 Digit_08_LBSS "?—";
BA_ "GenSigSendType" SG_ 2651930679 Digit_09_LBSS 1;
BA_ "EventTrans" SG_ 2651930679 Digit_09_LBSS 0;
BA_ "Accuracy" SG_ 2651930679 Digit_09_LBSS "?—";
BA_ "GenSigSendType" SG_ 2651930679 Digit_06_LBSS 1;
BA_ "EventTrans" SG_ 2651930679 Digit_06_LBSS 0;
BA_ "Accuracy" SG_ 2651930679 Digit_06_LBSS "?—";
BA_ "GenSigSendType" SG_ 2651930679 Digit_07_LBSS 1;
BA_ "EventTrans" SG_ 2651930679 Digit_07_LBSS 0;
BA_ "Accuracy" SG_ 2651930679 Digit_07_LBSS "?—";
BA_ "GenSigSendType" SG_ 2651930679 Digit_04_LBSS 1;
BA_ "EventTrans" SG_ 2651930679 Digit_04_LBSS 0;
BA_ "Accuracy" SG_ 2651930679 Digit_04_LBSS "?—";
BA_ "GenSigSendType" SG_ 2651930679 Digit_05_LBSS 1;
BA_ "EventTrans" SG_ 2651930679 Digit_05_LBSS 0;
BA_ "Accuracy" SG_ 2651930679 Digit_05_LBSS "?—";
BA_ "GenSigSendType" SG_ 2651930679 Digit_02_LBSS 1;
BA_ "EventTrans" SG_ 2651930679 Digit_02_LBSS 0;
BA_ "Accuracy" SG_ 2651930679 Digit_02_LBSS "?—";
BA_ "GenSigSendType" SG_ 2651930679 Digit_03_LBSS 1;
BA_ "EventTrans" SG_ 2651930679 Digit_03_LBSS 0;
BA_ "Accuracy" SG_ 2651930679 Digit_03_LBSS "?—";
BA_ "GenSigSendType" SG_ 2651930679 Digit_01_LBSS 1;
BA_ "EventTrans" SG_ 2651930679 Digit_01_LBSS 0;
BA_ "Accuracy" SG_ 2651930679 Digit_01_LBSS "?—";
BA_ "GenSigSendType" SG_ 2651930680 Digit_10_RBSS 1;
BA_ "EventTrans" SG_ 2651930680 Digit_10_RBSS 0;
BA_ "Accuracy" SG_ 2651930680 Digit_10_RBSS "?—";
BA_ "GenSigSendType" SG_ 2651930680 Digit_11_RBSS 1;
BA_ "EventTrans" SG_ 2651930680 Digit_11_RBSS 0;
BA_ "Accuracy" SG_ 2651930680 Digit_11_RBSS "?—";
BA_ "GenSigSendType" SG_ 2651930680 Digit_08_RBSS 1;
BA_ "EventTrans" SG_ 2651930680 Digit_08_RBSS 0;
BA_ "Accuracy" SG_ 2651930680 Digit_08_RBSS "?—";
BA_ "GenSigSendType" SG_ 2651930680 Digit_09_RBSS 1;
BA_ "EventTrans" SG_ 2651930680 Digit_09_RBSS 0;
BA_ "Accuracy" SG_ 2651930680 Digit_09_RBSS "?—";
BA_ "GenSigSendType" SG_ 2651930680 Digit_06_RBSS 1;
BA_ "EventTrans" SG_ 2651930680 Digit_06_RBSS 0;
BA_ "Accuracy" SG_ 2651930680 Digit_06_RBSS "?—";
BA_ "GenSigSendType" SG_ 2651930680 Digit_07_RBSS 1;
BA_ "EventTrans" SG_ 2651930680 Digit_07_RBSS 0;
BA_ "Accuracy" SG_ 2651930680 Digit_07_RBSS "?—";
BA_ "GenSigSendType" SG_ 2651930680 Digit_04_RBSS 1;
BA_ "EventTrans" SG_ 2651930680 Digit_04_RBSS 0;
BA_ "Accuracy" SG_ 2651930680 Digit_04_RBSS "?—";
BA_ "GenSigSendType" SG_ 2651930680 Digit_05_RBSS 1;
BA_ "EventTrans" SG_ 2651930680 Digit_05_RBSS 0;
BA_ "Accuracy" SG_ 2651930680 Digit_05_RBSS "?—";
BA_ "GenSigSendType" SG_ 2651930680 Digit_02_RBSS 1;
BA_ "EventTrans" SG_ 2651930680 Digit_02_RBSS 0;
BA_ "Accuracy" SG_ 2651930680 Digit_02_RBSS "?—";
BA_ "GenSigSendType" SG_ 2651930680 Digit_03_RBSS 1;
BA_ "EventTrans" SG_ 2651930680 Digit_03_RBSS 0;
BA_ "Accuracy" SG_ 2651930680 Digit_03_RBSS "?—";
BA_ "GenSigSendType" SG_ 2651930680 Digit_01_RBSS 1;
BA_ "EventTrans" SG_ 2651930680 Digit_01_RBSS 0;
BA_ "Accuracy" SG_ 2651930680 Digit_01_RBSS "?—";
BA_ "GenSigSendType" SG_ 2651930718 Digit_10_ELL 1;
BA_ "EventTrans" SG_ 2651930718 Digit_10_ELL 0;
BA_ "Accuracy" SG_ 2651930718 Digit_10_ELL "?—";
BA_ "GenSigSendType" SG_ 2651930718 Digit_11_ELL 1;
BA_ "EventTrans" SG_ 2651930718 Digit_11_ELL 0;
BA_ "Accuracy" SG_ 2651930718 Digit_11_ELL "?—";
BA_ "GenSigSendType" SG_ 2651930718 Digit_08_ELL 1;
BA_ "EventTrans" SG_ 2651930718 Digit_08_ELL 0;
BA_ "Accuracy" SG_ 2651930718 Digit_08_ELL "?—";
BA_ "GenSigSendType" SG_ 2651930718 Digit_09_ELL 1;
BA_ "EventTrans" SG_ 2651930718 Digit_09_ELL 0;
BA_ "Accuracy" SG_ 2651930718 Digit_09_ELL "?—";
BA_ "GenSigSendType" SG_ 2651930718 Digit_06_ELL 1;
BA_ "EventTrans" SG_ 2651930718 Digit_06_ELL 0;
BA_ "Accuracy" SG_ 2651930718 Digit_06_ELL "?—";
BA_ "GenSigSendType" SG_ 2651930718 Digit_07_ELL 1;
BA_ "EventTrans" SG_ 2651930718 Digit_07_ELL 0;
BA_ "Accuracy" SG_ 2651930718 Digit_07_ELL "?—";
BA_ "GenSigSendType" SG_ 2651930718 Digit_04_ELL 1;
BA_ "EventTrans" SG_ 2651930718 Digit_04_ELL 0;
BA_ "Accuracy" SG_ 2651930718 Digit_04_ELL "?—";
BA_ "GenSigSendType" SG_ 2651930718 Digit_05_ELL 1;
BA_ "EventTrans" SG_ 2651930718 Digit_05_ELL 0;
BA_ "Accuracy" SG_ 2651930718 Digit_05_ELL "?—";
BA_ "GenSigSendType" SG_ 2651930718 Digit_02_ELL 1;
BA_ "EventTrans" SG_ 2651930718 Digit_02_ELL 0;
BA_ "Accuracy" SG_ 2651930718 Digit_02_ELL "—";
BA_ "GenSigSendType" SG_ 2651930718 Digit_03_ELL 1;
BA_ "EventTrans" SG_ 2651930718 Digit_03_ELL 0;
BA_ "Accuracy" SG_ 2651930718 Digit_03_ELL "?—";
BA_ "GenSigSendType" SG_ 2651930718 Digit_01_ELL 1;
BA_ "EventTrans" SG_ 2651930718 Digit_01_ELL 0;
BA_ "Accuracy" SG_ 2651930718 Digit_01_ELL "—";
BA_ "GenSigSendType" SG_ 2651930719 Digit_10_ELR 1;
BA_ "EventTrans" SG_ 2651930719 Digit_10_ELR 0;
BA_ "Accuracy" SG_ 2651930719 Digit_10_ELR "?—";
BA_ "GenSigSendType" SG_ 2651930719 Digit_11_ELR 1;
BA_ "EventTrans" SG_ 2651930719 Digit_11_ELR 0;
BA_ "Accuracy" SG_ 2651930719 Digit_11_ELR "?—";
BA_ "GenSigSendType" SG_ 2651930719 Digit_08_ELR 1;
BA_ "EventTrans" SG_ 2651930719 Digit_08_ELR 0;
BA_ "Accuracy" SG_ 2651930719 Digit_08_ELR "?—";
BA_ "GenSigSendType" SG_ 2651930719 Digit_09_ELR 1;
BA_ "EventTrans" SG_ 2651930719 Digit_09_ELR 0;
BA_ "Accuracy" SG_ 2651930719 Digit_09_ELR "?—";
BA_ "GenSigSendType" SG_ 2651930719 Digit_06_ELR 1;
BA_ "EventTrans" SG_ 2651930719 Digit_06_ELR 0;
BA_ "Accuracy" SG_ 2651930719 Digit_06_ELR "?—";
BA_ "GenSigSendType" SG_ 2651930719 Digit_07_ELR 1;
BA_ "EventTrans" SG_ 2651930719 Digit_07_ELR 0;
BA_ "Accuracy" SG_ 2651930719 Digit_07_ELR "?—";
BA_ "GenSigSendType" SG_ 2651930719 Digit_04_ELR 1;
BA_ "EventTrans" SG_ 2651930719 Digit_04_ELR 0;
BA_ "Accuracy" SG_ 2651930719 Digit_04_ELR "?—";
BA_ "GenSigSendType" SG_ 2651930719 Digit_05_ELR 1;
BA_ "EventTrans" SG_ 2651930719 Digit_05_ELR 0;
BA_ "Accuracy" SG_ 2651930719 Digit_05_ELR "?—";
BA_ "GenSigSendType" SG_ 2651930719 Digit_02_ELR 1;
BA_ "EventTrans" SG_ 2651930719 Digit_02_ELR 0;
BA_ "Accuracy" SG_ 2651930719 Digit_02_ELR "?—";
BA_ "GenSigSendType" SG_ 2651930719 Digit_03_ELR 1;
BA_ "EventTrans" SG_ 2651930719 Digit_03_ELR 0;
BA_ "Accuracy" SG_ 2651930719 Digit_03_ELR "?—";
BA_ "GenSigSendType" SG_ 2651930719 Digit_01_ELR 1;
BA_ "EventTrans" SG_ 2651930719 Digit_01_ELR 0;
BA_ "Accuracy" SG_ 2651930719 Digit_01_ELR "—";
BA_ "GenSigSendType" SG_ 2651930720 Digit_10_ERL 1;
BA_ "EventTrans" SG_ 2651930720 Digit_10_ERL 0;
BA_ "Accuracy" SG_ 2651930720 Digit_10_ERL "?";
BA_ "GenSigSendType" SG_ 2651930720 Digit_11_ERL 1;
BA_ "EventTrans" SG_ 2651930720 Digit_11_ERL 0;
BA_ "Accuracy" SG_ 2651930720 Digit_11_ERL "?";
BA_ "GenSigSendType" SG_ 2651930720 Digit_08_ERL 1;
BA_ "EventTrans" SG_ 2651930720 Digit_08_ERL 0;
BA_ "Accuracy" SG_ 2651930720 Digit_08_ERL "?";
BA_ "GenSigSendType" SG_ 2651930720 Digit_09_ERL 1;
BA_ "EventTrans" SG_ 2651930720 Digit_09_ERL 0;
BA_ "Accuracy" SG_ 2651930720 Digit_09_ERL "?";
BA_ "GenSigSendType" SG_ 2651930720 Digit_06_ERL 1;
BA_ "EventTrans" SG_ 2651930720 Digit_06_ERL 0;
BA_ "Accuracy" SG_ 2651930720 Digit_06_ERL "?";
BA_ "GenSigSendType" SG_ 2651930720 Digit_07_ERL 1;
BA_ "EventTrans" SG_ 2651930720 Digit_07_ERL 0;
BA_ "Accuracy" SG_ 2651930720 Digit_07_ERL "?";
BA_ "GenSigSendType" SG_ 2651930720 Digit_04_ERL 1;
BA_ "EventTrans" SG_ 2651930720 Digit_04_ERL 0;
BA_ "Accuracy" SG_ 2651930720 Digit_04_ERL "?";
BA_ "GenSigSendType" SG_ 2651930720 Digit_05_ERL 1;
BA_ "EventTrans" SG_ 2651930720 Digit_05_ERL 0;
BA_ "Accuracy" SG_ 2651930720 Digit_05_ERL "?";
BA_ "GenSigSendType" SG_ 2651930720 Digit_02_ERL 1;
BA_ "EventTrans" SG_ 2651930720 Digit_02_ERL 0;
BA_ "Accuracy" SG_ 2651930720 Digit_02_ERL "?—";
BA_ "GenSigSendType" SG_ 2651930720 Digit_03_ERL 1;
BA_ "EventTrans" SG_ 2651930720 Digit_03_ERL 0;
BA_ "Accuracy" SG_ 2651930720 Digit_03_ERL "?";
BA_ "GenSigSendType" SG_ 2651930720 Digit_01_ERL 1;
BA_ "EventTrans" SG_ 2651930720 Digit_01_ERL 0;
BA_ "Accuracy" SG_ 2651930720 Digit_01_ERL "?";
BA_ "GenSigSendType" SG_ 2651930721 Digit_10_ERR 1;
BA_ "EventTrans" SG_ 2651930721 Digit_10_ERR 0;
BA_ "Accuracy" SG_ 2651930721 Digit_10_ERR "?";
BA_ "GenSigSendType" SG_ 2651930721 Digit_11_ERR 1;
BA_ "EventTrans" SG_ 2651930721 Digit_11_ERR 0;
BA_ "Accuracy" SG_ 2651930721 Digit_11_ERR "?";
BA_ "GenSigSendType" SG_ 2651930721 Digit_08_ERR 1;
BA_ "EventTrans" SG_ 2651930721 Digit_08_ERR 0;
BA_ "Accuracy" SG_ 2651930721 Digit_08_ERR "?";
BA_ "GenSigSendType" SG_ 2651930721 Digit_09_ERR 1;
BA_ "EventTrans" SG_ 2651930721 Digit_09_ERR 0;
BA_ "Accuracy" SG_ 2651930721 Digit_09_ERR "?";
BA_ "GenSigSendType" SG_ 2651930721 Digit_06_ERR 1;
BA_ "EventTrans" SG_ 2651930721 Digit_06_ERR 0;
BA_ "Accuracy" SG_ 2651930721 Digit_06_ERR "?";
BA_ "GenSigSendType" SG_ 2651930721 Digit_07_ERR 1;
BA_ "EventTrans" SG_ 2651930721 Digit_07_ERR 0;
BA_ "Accuracy" SG_ 2651930721 Digit_07_ERR "?";
BA_ "GenSigSendType" SG_ 2651930721 Digit_04_ERR 1;
BA_ "EventTrans" SG_ 2651930721 Digit_04_ERR 0;
BA_ "Accuracy" SG_ 2651930721 Digit_04_ERR "?";
BA_ "GenSigSendType" SG_ 2651930721 Digit_05_ERR 1;
BA_ "EventTrans" SG_ 2651930721 Digit_05_ERR 0;
BA_ "Accuracy" SG_ 2651930721 Digit_05_ERR "?";
BA_ "GenSigSendType" SG_ 2651930721 Digit_02_ERR 1;
BA_ "EventTrans" SG_ 2651930721 Digit_02_ERR 0;
BA_ "Accuracy" SG_ 2651930721 Digit_02_ERR "?—";
BA_ "GenSigSendType" SG_ 2651930721 Digit_03_ERR 1;
BA_ "EventTrans" SG_ 2651930721 Digit_03_ERR 0;
BA_ "Accuracy" SG_ 2651930721 Digit_03_ERR "?";
BA_ "GenSigSendType" SG_ 2651930721 Digit_01_ERR 1;
BA_ "EventTrans" SG_ 2651930721 Digit_01_ERR 0;
BA_ "Accuracy" SG_ 2651930721 Digit_01_ERR "?";
BA_ "GenSigSendType" SG_ 2654208055 SystemStatus 3;
BA_ "EventTrans" SG_ 2654208055 SystemStatus 0;
BA_ "GenSigSendType" SG_ 2654208056 SystemStatus 3;
BA_ "EventTrans" SG_ 2654208056 SystemStatus 0;
BA_ "GenSigSendType" SG_ 2654208081 SystemStatus_RSL 3;
BA_ "EventTrans" SG_ 2654208081 SystemStatus_RSL 0;
BA_ "GenSigSendType" SG_ 2654208082 SystemStatus_RSR 3;
BA_ "EventTrans" SG_ 2654208082 SystemStatus_RSR 0;
BA_ "GenSigSendType" SG_ 2654208094 SystemStatus_ELL 3;
BA_ "EventTrans" SG_ 2654208094 SystemStatus_ELL 0;
BA_ "GenSigSendType" SG_ 2654208095 SystemStatus_ELR 3;
BA_ "EventTrans" SG_ 2654208095 SystemStatus_ELR 0;
BA_ "GenSigSendType" SG_ 2654208096 SystemStatus_ERL 3;
BA_ "EventTrans" SG_ 2654208096 SystemStatus_ERL 0;
BA_ "GenSigSendType" SG_ 2654208097 SystemStatus_ERR 3;
BA_ "EventTrans" SG_ 2654208097 SystemStatus_ERR 0;
BA_ "GenSigSendType" SG_ 2654208120 SystemStatus_NPR 3;
BA_ "EventTrans" SG_ 2654208120 SystemStatus_NPR 0;
VAL_ 1428 RRAutoMode 0 "OFF" 1 "ON" ;
VAL_ 1428 RLAutoMode 0 "OFF" 1 "ON" ;
VAL_ 1428 RLAirFlowZone 0 "Vent" 1 "Floor" 2 "All" 3 "Auto" 4 "not_used" 5 "not_used" 6 "not_used" 7 "not_used" ;
VAL_ 1428 RRAirFlowZone 0 "Vent" 1 "Floor" 2 "All" 3 "Auto" 4 "not_used" 5 "not_used" 6 "not_used" 7 "not_used" ;
VAL_ 1428 RearClimateReq 0 "OFF" 1 "ON" ;
VAL_ 1428 RLPresetMode 0 "Other" 1 "Cool_Mode" 2 "Warm_Mode" 3 "Personal_Mode" ;
VAL_ 1428 RBlowerSpeed10L 0 "OFF" 1 "Blower_Level_1" 2 "Blower_Level_2" 3 "Blower_Level_3" 4 "Blower_Level_4" 5 "Blower_Level_5" 6 "Blower_Level_6" 7 "Blower_Level_7" 8 "Blower_Level_8" 9 "AUTO" 10 "Not_used" 11 "Not_used" 12 "Not_used" 13 "Not_used" 14 "Not_used" 15 "Not_used" ;
VAL_ 1428 RBlowerSpeed 0 "OFF" 1 "Blower_Level_1" 2 "Blower_Level_2" 3 "Blower_Level_3" 4 "Blower_Level_4" 5 "Blower_Level_5" 6 "not_used" 7 "not_used" ;
VAL_ 1428 NCL_RearBlowerAutoMode 0 "OFF" 1 "ON" ;
VAL_ 1428 RearSourceCommand 0 "No_Command" 1 "MKF" 2 "NIT" 3 "MKR" 4 "Not_Used" 5 "Not_Used" 6 "Not_Used" 7 "Not_Used" ;
VAL_ 1428 RRPresetMode 0 "Other" 1 "Cool_Mode" 2 "Warm_Mode" 3 "Personal_Mode" ;
VAL_ 1428 RRThermalComfort 0 "'0'" 1 "'_1'" 2 "'_2'" 3 "'_3'" 4 "'_4'" 5 "'_1'" 6 "'_2'" 7 "'_3'" 8 "'_4'" 9 "Not_used" 10 "Not_used" 11 "Not_used" 12 "Not_used" 13 "Not_used" 14 "Not_used" 15 "Not_used" ;
VAL_ 1428 RLThermalComfort 0 "'0'" 1 "'_1'" 2 "'_2'" 3 "'_3'" 4 "'_4'" 5 "'_1'" 6 "'_2'" 7 "'_3'" 8 "'_4'" 9 "Not_used" 10 "Not_used" 11 "Not_used" 12 "Not_used" 13 "Not_used" 14 "Not_used" 15 "Not_used" ;
VAL_ 1429 RSLHeating 0 "Not_active" 1 "Heat_level_1" 2 "Heat_level_2" 3 "Heat_level_3" ;
VAL_ 1429 RSLFans 0 "Not_active" 1 "Fan_level_1" 2 "Fan_level_2" 3 "Fan_level_3" ;
VAL_ 1430 RSRHeating 0 "Not_active" 1 "Heat_level_1" 2 "Heat_level_2" 3 "Heat_level_3" ;
VAL_ 1430 RSRFans 0 "Not_active" 1 "Fan_level_1" 2 "Fan_level_2" 3 "Fan_level_3" ;
VAL_ 1436 RSH_RSLFailSts 0 "Fail_Not_Present" 1 "Fail_Present" ;
VAL_ 1436 RSH_RSRFailSts 0 "Fail_Not_Present" 1 "Fail_Present" ;
VAL_ 1436 RSH_RSLFan 0 "Not_Active" 1 "Fan_level_1" 2 "Fan_level_2" 3 "Fan_level_3" ;
VAL_ 1436 RSH_RSLHeating 0 "Not_Active" 1 "Heat_Level_1" 2 "Heat_Level_2" 3 "Heat_Level_3" ;
VAL_ 1436 RSH_RSRFan 0 "Not_Active" 1 "Fan_Level_1" 2 "Fan_Level_2" 3 "Fan_Level_3" ;
VAL_ 1436 RSH_RSRHeating 0 "Not_Active" 1 "Heat_Level_1" 2 "Heat_Level_2" 3 "Heat_Level_3" ;
VAL_ 1441 ReducePowerAssist 0 "Not_Active" 1 "Active" ;
VAL_ 1441 BatteryDisconnectionWarning 0 "Not_Active" 1 "Active" ;
VAL_ 1441 VCU_EnergyProfileRqt 0 "Normal" 1 "Eco" 2 "Low_Driver" 3 "Low_Auto" 4 "Degraded" 5 "Not_Used" 6 "Not_Used" 7 "Not_Used" ;
VAL_ 1441 VehicleNotInUse 0 "Vehicle_in_Use" 1 "Start_Countdown" 2 "Start_Signalling" 3 "System_Failure" ;
VAL_ 1441 EManettinoSts 1 "Edrive_ECO" 2 "Standard" 3 "Performance" 4 "Qualifying" ;
VAL_ 1441 EManettinoFailSts 0 "Fail_Not_Present" 1 "Fail_Present" ;
VAL_ 1441 EManettinoTransitionInfo 0 "No_Transition" 1 "Status_Not_Allowed" 2 "Setting_Refused" 3 "not_used" 4 "not_used" 5 "not_used" 6 "Status_Modified" 7 "Setting_Accepted" ;
VAL_ 1441 MVLoadEnable_NPR 0 "Disable" 1 "Enable" ;
VAL_ 1441 CruiseControlSts 0 "Not_inserted" 1 "Inserted" ;
VAL_ 1441 CruiseControlLampSts 0 "cruise_off" 1 "cruise_on_not_engaged" 2 "cruise_on_engaged" 3 "cruise_error" ;
VAL_ 1441 RechargeSts 0 "Charging" 1 "Not_charging" ;
VAL_ 1441 BatteryVoltageLevelFailSts 0 "Fail_not_present" 1 "Fail_present" ;
VAL_ 1441 EngineSts 0 "Engine_OFF" 1 "Engine_ON" 2 "Engine_cranking" 3 "Engine_Shut_down" ;
VAL_ 1441 StopStartSts 0 "Off" 1 "On" 2 "Engine_Restart" 3 "Stop_Request" ;
VAL_ 1441 PowertrainSts 0 "OFF" 1 "ON" 2 "Starting" 3 "Shut_down" 4 "Not_used" 5 "Not_used" 6 "Not_used" 7 "Not_used" ;
VAL_ 1441 EDriveSts 0 "Off" 1 "Prepare_E_Drive" 2 "E_Drive" 3 "Stop_E_Drive" ;
VAL_ 1444 MirrorsProfileReq 0 "Not_Active" 1 "MemoryOrAutoTiltReq" 2 "ProfileReq" 3 "Not_Used" ;
VAL_ 1444 NIT_DriverMirrorHorizDirection 0 "Direction_LEFT" 1 "Direction_RIGHT" ;
VAL_ 1444 NIT_DriverMirrorVertDirection 0 "Direction_UP" 1 "Direction_DOWN" ;
VAL_ 1444 PeriodMessage_CmdProfile 0 "Normal" 1 "Fast" ;
VAL_ 1444 ColumnProfileReq 0 "Not_Active" 1 "MemoryReq" 2 "ProfileReq" 3 "Not_Used" ;
VAL_ 1446 NITAmbientLightNightDay 0 "Night" 1 "Day" ;
VAL_ 1446 NITAmbientLightNightDaySwitch 0 "Disabled" 1 "Enabled" ;
VAL_ 1446 NITAmbientLightIntensityNight 0 "Intensity_1" 1 "Intensity_2" 2 "Intensity_3" 3 "Intensity_4" 4 "Intensity_5" 5 "Intensity_6" 6 "Intensity_7" 7 "Intensity_8" ;
VAL_ 1446 NITAmbientLightIntensityDay 0 "Intensity_1" 1 "Intensity_2" 2 "Intensity_3" 3 "Intensity_4" 4 "Intensity_5" 5 "Intensity_6" 6 "Intensity_7" 7 "Intensity_8" ;
VAL_ 1446 MirrorMovementReqCntrl 0 "Movement_Not_requested" 1 "Movement_Request" ;
VAL_ 1446 NITAmbientLightNightEnable 0 "Disabled" 1 "Enabled" ;
VAL_ 1446 NITAmbientLightDayEnable 0 "Disabled" 1 "Enabled" ;
VAL_ 1446 NITAmbientLightColour 0 "Colour_1" 1 "Colour_2" 2 "Colour_3" 3 "Colour_4" 4 "Colour_5" 5 "Colour_6" 6 "Colour_7" 7 "Colour_8" 8 "Colour_9" 9 "Colour_10" 10 "Colour_11" 11 "Colour_12" 12 "Colour_13" 13 "Colour_14" 14 "Colour_15" 15 "Colour_16" ;
VAL_ 1446 NIT_DimmingLevelRoof2 0 "Level1" 1 "Level2" 2 "Level3" 3 "Level4" 4 "Level5" 5 "Level6" 6 "Level7" 7 "Level8" ;
VAL_ 1446 NIT_DimmingLevelRoof1 0 "Level1" 1 "Level2" 2 "Level3" 3 "Level4" 4 "Level5" 5 "Level6" 6 "Level7" 7 "Level8" ;
VAL_ 1446 IDC_Deactivation_DoorOpening_Swi 0 "Not_Active" 1 "Active" ;
VAL_ 1446 NITFailSts 0 "Fail_Not_Present" 1 "Fail_Present" ;
VAL_ 1446 NIT_DimmingLevelRoof4 0 "Level1" 1 "Level2" 2 "Level3" 3 "Level4" 4 "Level5" 5 "Level6" 6 "Level7" 7 "Level8" ;
VAL_ 1446 NIT_DimmingLevelRoof3 0 "Level1" 1 "Level2" 2 "Level3" 3 "Level4" 4 "Level5" 5 "Level6" 6 "Level7" 7 "Level8" ;
VAL_ 1446 NIT_DimmingLevelRoof6 0 "Level1" 1 "Level2" 2 "Level3" 3 "Level4" 4 "Level5" 5 "Level6" 6 "Level7" 7 "Level8" ;
VAL_ 1446 NIT_DimmingLevelRoof5 0 "Level1" 1 "Level2" 2 "Level3" 3 "Level4" 4 "Level5" 5 "Level6" 6 "Level7" 7 "Level8" ;
VAL_ 1446 IDC_Spot_RH_Button_Rear 0 "Not_Active" 1 "Active" ;
VAL_ 1446 IDC_Spot_LH_Button_Rear 0 "Not_Active" 1 "Active" ;
VAL_ 1446 ChargeButtonReq 0 "Not_Active" 1 "OpenCmd" 2 "CloseCmd" 3 "StartCmd" 4 "StopCmd" 5 "Not_Used" 6 "Not_Used" 7 "Not_Used" ;
VAL_ 1446 IDC_RearLightCommand_Left 0 "Not_Active" 1 "Active" ;
VAL_ 1446 IDC_RearLightCommand_Right 0 "Not_Active" 1 "Active" ;
VAL_ 1447 FrontPassengerHeating 0 "Not_active" 1 "Heat_level_1" 2 "Heat_level_2" 3 "Heat_level_3" ;
VAL_ 1447 DriverAirScarf 0 "OFF" 1 "Level_1" 2 "Level_2" 3 "Level_3" ;
VAL_ 1447 FrontDriverHeating 0 "Not_active" 1 "Heat_level_1" 2 "Heat_level_2" 3 "Heat_level_3" ;
VAL_ 1447 DriverFans 0 "Not_active" 1 "Fan_level_1" 2 "Fan_level_2" 3 "Fan_level_3" ;
VAL_ 1447 DriverMassageType 0 "OFF" 1 "Wave" 2 "Stretch" 3 "Shiatsu" 4 "Lumbar" 5 "Shoulder" 6 "not_used" 7 "not_used" ;
VAL_ 1447 DriverMassageLevel 0 "OFF" 1 "Level_1" 2 "Level_2" 3 "Level_3" 4 "Level_4" 5 "Level_5" 6 "Not_used" 7 "Not_used" ;
VAL_ 1447 PassengerFans 0 "Not_active" 1 "Fan_level_1" 2 "Fan_level_2" 3 "Fan_level_3" ;
VAL_ 1447 PsngrMassageType 0 "OFF" 1 "Wave" 2 "Stretch" 3 "Shiatsu" 4 "Lumbar" 5 "Shoulder" 6 "not_used" 7 "not_used" ;
VAL_ 1447 PsngrMassageLevel 0 "OFF" 1 "Level_1" 2 "Level_2" 3 "Level_3" 4 "Level_4" 5 "Level_5" 6 "Not_used" 7 "Not_used" ;
VAL_ 1447 PsngrAirScarf 0 "OFF" 1 "Level_1" 2 "Level_2" 3 "Level_3" ;
VAL_ 1448 DriverAirFlowZone 0 "BLevel" 1 "Vent" 2 "HiLevel" 3 "Defrost" 4 "Heat" 5 "Floor" 6 "All" 7 "Auto" ;
VAL_ 1448 PassengerAirFlowZone 0 "BLevel" 1 "Vent" 2 "HiLevel" 3 "Defrost" 4 "Heat" 5 "Floor" 6 "All" 7 "Auto" ;
VAL_ 1448 CentralVent 0 "Closed" 1 "Opened" ;
VAL_ 1448 AirConditionCompressor 0 "OFF" 1 "ON" ;
VAL_ 1448 BlowerSpeed_Infotainment 0 "OFF" 1 "Blower_Level_1" 2 "Blower_Level_2" 3 "Blower_Level_3" 4 "Blower_Level_4" 5 "Blower_Level_5" 6 "not_used" 7 "not_used" ;
VAL_ 1448 MonoMode 0 "OFF" 1 "ON" ;
VAL_ 1448 PassengerAutoMode 0 "OFF" 1 "ON" ;
VAL_ 1448 DriverAutoMode 0 "OFF" 1 "ON" ;
VAL_ 1448 BlowerSpeed10L 0 "OFF" 1 "Blower_Level_1" 2 "Blower_Level_2" 3 "Blower_Level_3" 4 "Blower_Level_4" 5 "Blower_Level_5" 6 "Blower_Level_6" 7 "Blower_Level_7" 8 "Blower_Level_8" 9 "AUTO" 10 "Not_used" 11 "Not_used" 12 "Not_used" 13 "Not_used" 14 "Not_used" 15 "Not_used" ;
VAL_ 1448 AirRecirculation 0 "OFF" 1 "ON" ;
VAL_ 1448 NIT_BlowerAutoMode 0 "OFF" 1 "ON" ;
VAL_ 1448 ClimateReq 0 "OFF" 1 "ON" ;
VAL_ 1448 AirSanitizer 0 "OFF" 1 "ON" ;
VAL_ 1449 PsngrSeatLengthSts 0 "No_command" 1 "Extension" 2 "Retraction" 3 "Not_used" ;
VAL_ 1449 DriverBolsterSts 0 "No_command" 1 "inflating" 2 "deflating" 3 "not_used" ;
VAL_ 1449 DriverBolsterType 0 "No_command" 1 "Thing" 2 "Side" 3 "Lumbar" 4 "Back" 5 "not_used" 6 "not_used" 7 "not_used" ;
VAL_ 1449 DriverSeatLengthSts 0 "No_command" 1 "Extension" 2 "Retraction" 3 "Not_used" ;
VAL_ 1449 PeriodMessage 0 "Normal" 1 "Fast" ;
VAL_ 1449 PsngrBolsterSts 0 "No_command" 1 "inflating" 2 "deflating" 3 "not_used" ;
VAL_ 1449 PsngrBolsterType 0 "No_command" 1 "Thing" 2 "Side" 3 "Lumbar" 4 "Back" 5 "not_used" 6 "not_used" 7 "not_used" ;
VAL_ 1449 SeatProfileReq 0 "Not_Active" 1 "MemoryReq" 2 "ProfileReq" 3 "Not_Used" ;
VAL_ 1450 AirRecirculation 0 "OFF" 1 "ON" ;
VAL_ 1450 PassengerAutoMode 0 "OFF" 1 "ON" ;
VAL_ 1450 DriverAutoMode 0 "OFF" 1 "ON" ;
VAL_ 1450 DriverAirFlowZone 0 "BLevel" 1 "Vent" 2 "HiLevel" 3 "Defrost" 4 "Heat" 5 "Floor" 6 "All" 7 "No_distribution_visualizations" ;
VAL_ 1450 AirConditionCompressor 0 "OFF" 1 "ON" ;
VAL_ 1450 BlowerSpeed 0 "OFF" 1 "Blower_Level_1" 2 "Blower_Level_2" 3 "Blower_Level_3" 4 "Blower_Level_4" 5 "Blower_Level_5" 6 "not_used" 7 "not_used" ;
VAL_ 1450 PassengerAirFlowZone 0 "BLevel" 1 "Vent" 2 "HiLevel" 3 "Defrost" 4 "Heat" 5 "Floor" 6 "All" 7 "No_distribution_visualizations" ;
VAL_ 1450 MonoMode 0 "OFF" 1 "ON" ;
VAL_ 1450 BlowerSpeed10L 0 "OFF" 1 "Blower_Level_1" 2 "Blower_Level_2" 3 "Blower_Level_3" 4 "Blower_Level_4" 5 "Blower_Level_5" 6 "Blower_Level_6" 7 "Blower_Level_7" 8 "Blower_Level_8" 9 "AUTO" 10 "Not_used" 11 "Not_used" 12 "Not_used" 13 "Not_used" 14 "Not_used" 15 "Not_used" ;
VAL_ 1450 CentralVent 0 "Closed" 1 "Opened" ;
VAL_ 1450 NCL_BlowerAutoMode 0 "OFF" 1 "ON" ;
VAL_ 1450 SourceCommand 0 "No_Command" 1 "Satellite" 2 "NIT" 3 "MKF" 4 "MKR" 5 "Not_Used" 6 "Not_Used" 7 "Not_Used" ;
VAL_ 1450 AirSanitizer 0 "OFF" 1 "ON" ;
VAL_ 1450 ClimateReq 0 "OFF" 1 "ON" ;
VAL_ 1451 NIT_RLHeating 0 "Not_active" 1 "Heat_level_1" 2 "Heat_level_2" 3 "Heat_level_3" ;
VAL_ 1451 NIT_RLFans 0 "Not_active" 1 "Fan_level_1" 2 "Fan_level_2" 3 "Fan_level_3" ;
VAL_ 1451 NIT_RRHeating 0 "Not_active" 1 "Heat_level_1" 2 "Heat_level_2" 3 "Heat_level_3" ;
VAL_ 1451 NIT_RRFans 0 "Not_active" 1 "Fan_level_1" 2 "Fan_level_2" 3 "Fan_level_3" ;
VAL_ 1452 NIT_RLAirFlowZone 0 "Vent" 1 "Floor" 2 "All" 3 "Auto" 4 "not_used" 5 "not_used" 6 "not_used" 7 "not_used" ;
VAL_ 1452 NIT_RRAirFlowZone 0 "Vent" 1 "Floor" 2 "All" 3 "Auto" 4 "not_used" 5 "not_used" 6 "not_used" 7 "not_used" ;
VAL_ 1452 RearClimateReq 0 "OFF" 1 "ON" ;
VAL_ 1452 NIT_RearBlowerSpeed 0 "OFF" 1 "Blower_Level_1" 2 "Blower_Level_2" 3 "Blower_Level_3" 4 "Blower_Level_4" 5 "Blower_Level_5" 6 "not_used" 7 "not_used" ;
VAL_ 1452 NIT_RRAutoMode 0 "OFF" 1 "ON" ;
VAL_ 1452 NIT_RLAutoMode 0 "OFF" 1 "ON" ;
VAL_ 1452 NIT_RRPresetMode 0 "Other" 1 "Cool_Mode" 2 "Warm_Mode" 3 "Personal_Mode" ;
VAL_ 1452 NIT_RLPresetMode 0 "Other" 1 "Cool_Mode" 2 "Warm_Mode" 3 "Personal_Mode" ;
VAL_ 1452 NIT_RearBlowerSpeed10L 0 "OFF" 1 "Blower_Level_1" 2 "Blower_Level_2" 3 "Blower_Level_3" 4 "Blower_Level_4" 5 "Blower_Level_5" 6 "Blower_Level_6" 7 "Blower_Level_7" 8 "Blower_Level_8" 9 "AUTO" 10 "Not_used" 11 "Not_used" 12 "Not_used" 13 "Not_used" 14 "Not_used" 15 "Not_used" ;
VAL_ 1452 NIT_RLAirFlowZonePersPreset 0 "Vent" 1 "Floor" 2 "All" 3 "not_used" 4 "not_used" 5 "not_used" 6 "not_used" 7 "not_used" ;
VAL_ 1452 NIT_RearBlowerAutoMode 0 "OFF" 1 "ON" ;
VAL_ 1452 NIT_RRAirFlowZonePersPreset 0 "Vent" 1 "Floor" 2 "All" 3 "not_used" 4 "not_used" 5 "not_used" 6 "not_used" 7 "not_used" ;
VAL_ 1452 NIT_RearBlowerSpeed10LPersPreset 0 "OFF" 1 "Blower_Level_1" 2 "Blower_Level_2" 3 "Blower_Level_3" 4 "Blower_Level_4" 5 "Blower_Level_5" 6 "Blower_Level_6" 7 "Blower_Level_7" 8 "Blower_Level_8" 9 "AUTO" 10 "Not_used" 11 "Not_used" 12 "Not_used" 13 "Not_used" 14 "Not_used" 15 "Not_used" ;
VAL_ 1454 MKF_DimmingLevelRoof1 0 "Level1" 1 "Level2" 2 "Level3" 3 "Level4" 4 "Level5" 5 "Level6" 6 "Level7" 7 "Level8" ;
VAL_ 1454 MKF_RimHeatingCommand 0 "Not_Active" 1 "Active" ;
VAL_ 1457 NBCAmbientLightNightDay 0 "Night" 1 "Day" ;
VAL_ 1457 NBCAmbientLightNightDaySwitch 0 "Disabled" 1 "Enabled" ;
VAL_ 1457 NBCAmbientLightIntensityNight 0 "Intensity_1" 1 "Intensity_2" 2 "Intensity_3" 3 "Intensity_4" 4 "Intensity_5" 5 "Intensity_6" 6 "Intensity_7" 7 "Intensity_8" ;
VAL_ 1457 NBCAmbientLightIntensityDay 0 "Intensity_1" 1 "Intensity_2" 2 "Intensity_3" 3 "Intensity_4" 4 "Intensity_5" 5 "Intensity_6" 6 "Intensity_7" 7 "Intensity_8" ;
VAL_ 1457 NBCAmbientLightDayEnable 0 "Disabled" 1 "Enabled" ;
VAL_ 1457 NBC_DimmingLevelRoof1 0 "Level1" 1 "Level2" 2 "Level3" 3 "Level4" 4 "Level5" 5 "Level6" 6 "Level7" 7 "Level8" ;
VAL_ 1457 NBCAmbientLightColour 0 "Colour_1" 1 "Colour_2" 2 "Colour_3" 3 "Colour_4" 4 "Colour_5" 5 "Colour_6" 6 "Colour_7" 7 "Colour_8" 8 "Colour_9" 9 "Colour_10" 10 "Colour_11" 11 "Colour_12" 12 "Colour_13" 13 "Colour_14" 14 "Colour_15" 15 "Colour_16" ;
VAL_ 1457 NBCAmbientLightNightEnable 0 "Disabled" 1 "Enabled" ;
VAL_ 1457 NBC_DimmingLevelRoof3 0 "Level1" 1 "Level2" 2 "Level3" 3 "Level4" 4 "Level5" 5 "Level6" 6 "Level7" 7 "Level8" ;
VAL_ 1457 NBC_DimmingLevelRoof2 0 "Level1" 1 "Level2" 2 "Level3" 3 "Level4" 4 "Level5" 5 "Level6" 6 "Level7" 7 "Level8" ;
VAL_ 1457 NBCAmbientLightResponseError 0 "No_Error" 1 "Error" ;
VAL_ 1457 NBCAmbientLightEnable 0 "Disabled" 1 "Enabled" ;
VAL_ 1457 NBC_DimmingLevelRoof5 0 "Level1" 1 "Level2" 2 "Level3" 3 "Level4" 4 "Level5" 5 "Level6" 6 "Level7" 7 "Level8" ;
VAL_ 1457 NBC_DimmingLevelRoof4 0 "Level1" 1 "Level2" 2 "Level3" 3 "Level4" 4 "Level5" 5 "Level6" 6 "Level7" 7 "Level8" ;
VAL_ 1457 NBCAmbientLightGenericFailSts 0 "Fail_not_Present" 1 "Fail_Present" ;
VAL_ 1457 NBCAmbientLightCurrentFailSts 0 "Fail_not_Present" 1 "Fail_Present" ;
VAL_ 1457 WiperWaterLevelLampSts 0 "Not_Active" 1 "Active" ;
VAL_ 1457 WiperWaterLowLevel 0 "OFF" 1 "ON" ;
VAL_ 1457 NBC_DimmingLevelRoof6 0 "Level1" 1 "Level2" 2 "Level3" 3 "Level4" 4 "Level5" 5 "Level6" 6 "Level7" 7 "Level8" ;
VAL_ 1457 NVDFailSts 0 "Fail_not_Present" 1 "Fail_Present" ;
VAL_ 1458 DriverMassageLevel 0 "OFF" 1 "Mode_1" 2 "mode_2" 3 "Mode_3" 4 "Mode_4" 5 "Mode_5" 6 "Not_used" 7 "Not_used" ;
VAL_ 1458 DriverAirScarf 0 "OFF" 1 "Level_1" 2 "Level_2" 3 "Level_3" 4 "Airscarf_not_available" 5 "Not_used" 6 "Not_used" 7 "Not_used" ;
VAL_ 1458 FrontDriverHeating 0 "Not_active" 1 "Heat_level_1" 2 "Heat_level_2" 3 "Heat_level_3" ;
VAL_ 1458 DriverFans 0 "Not_active" 1 "Fan_level_1" 2 "Fan_level_2" 3 "Fan_level_3" ;
VAL_ 1458 DriverMassageType 0 "OFF" 1 "Wave" 2 "Stretch" 3 "Shiatsu" 4 "Lumbar" 5 "Shoulder" 6 "not_used" 7 "not_used" ;
VAL_ 1458 ColumnProfileSts 0 "Ready" 1 "Fail_Present" 2 "ProfileReached" 3 "ManualReached" 4 "ProfileOrMemoryMoving" 5 "ManualMoving" 6 "NAGInternalFunction" 7 "Not_Used" ;
VAL_ 1463 PsngrMassageLevel 0 "OFF" 1 "Mode_1" 2 "mode_2" 3 "Mode_3" 4 "Mode_4" 5 "Mode_5" 6 "Not_used" 7 "Not_used" ;
VAL_ 1463 PsngrAirScarf 0 "OFF" 1 "Level_1" 2 "Level_2" 3 "Level_3" 4 "Airscarf_not_available" 5 "Not_used" 6 "Not_used" 7 "Not_used" ;
VAL_ 1463 FrontPassengerHeating 0 "Not_active" 1 "Heat_level_1" 2 "Heat_level_2" 3 "Heat_level_3" ;
VAL_ 1463 PassengerFans 0 "Not_active" 1 "Fan_level_1" 2 "Fan_level_2" 3 "Fan_level_3" ;
VAL_ 1463 PsngrMassageType 0 "OFF" 1 "Wave" 2 "Stretch" 3 "Shiatsu" 4 "Lumbar" 5 "Shoulder" 6 "not_used" 7 "not_used" ;
VAL_ 1464 SeatProfileSts 0 "Ready" 1 "Fail_Present" 2 "ProfileReached" 3 "ManualReached" 4 "ProfileOrMemoryMoving" 5 "ManualMoving" 6 "NAGInternalFunction" 7 "Not_Used" ;
VAL_ 1464 DriverSeatSetupReq 0 "Not_pressed" 1 "Pressed" ;
VAL_ 1464 DriverSeatLengthFbk 0 "Extented" 1 "Retracted" 2 "Middle_position" 3 "Not_used" ;
VAL_ 1465 PsngrSeatSetupReq 0 "Not_pressed" 1 "Pressed" ;
VAL_ 1465 PsngrSeatLengthFbk 0 "Extented" 1 "Retracted" 2 "Middle_position" 3 "Not_used" ;
VAL_ 1485 LongParkingInfoForDisplay 0 "Not_Active" 1 "Deactivated" 2 "Activated" 3 "Not_Activated" 4 "Automatic_Activated" 5 "Automatic_Activation_Rqt" 6 "not_used" 7 "not_used" ;
VAL_ 1485 HVBBuzzerReq 0 "Not_Active" 1 "Active" ;
VAL_ 1485 HVBChargeWarningForDisplay 0 "No_Failure" 1 "OBC Fail_Communication" 2 "PlugLock_Fail" 3 "OBC_Fail_Power_Conversion" 4 "BOOSTER_Fail" 5 "HVB_Recharge_Fail_ChargingBus" 6 "EVSE_Fail" 7 "Pwr_Limited_By_Grid" 8 "not_used" 9 "not_used" 10 "not_used" 11 "not_used" 12 "not_used" 13 "not_used" 14 "not_used" 15 "not_used" 16 "not_used" 17 "not_used" 18 "not_used" 19 "not_used" 20 "not_used" 21 "not_used" 22 "not_used" 23 "not_used" 24 "not_used" 25 "not_used" 26 "not_used" 27 "not_used" 28 "not_used" 29 "not_used" 30 "not_used" 31 "not_used" ;
VAL_ 1485 LongParkingSts 0 "Not_Active" 1 "Active" ;
VAL_ 1485 HVBSOC_Status_HMI 0 "Not_Present" 1 "Degraded" 2 "Critical" 3 "not_used" ;
VAL_ 1485 HVB_TemperatureFailSts 0 "Not_Active" 1 "Degraded" 2 "Critical" 3 "Not_Used" ;
VAL_ 1485 BatPrecondSts 0 "Not_Active" 1 "Active" 2 "Active_TargetReached" ;
VAL_ 1485 HVSysWarningForDisplay 0 "No_Failure" 1 "MSD_Open" 2 "HVIL_Open" 3 "HV_Insulation_Critical" 4 "HV_Energizing_Error_Critical" 5 "HV_Insulation_Warning" 6 "HV_Energizing_Error_Warning" 7 "not_used" 8 "not_used" 9 "not_used" 10 "not_used" 11 "not_used" 12 "not_used" 13 "not_used" 14 "not_used" 15 "not_used" ;
VAL_ 1485 BatEstTimeToTarget 127 "SNA" ;
VAL_ 1485 MILrequest 0 "MILLampOff" 1 "MILLampOn" ;
VAL_ 1485 BatPrecondProgress 255 "SNA" ;
VAL_ 1485 HVBWarningForDisplay 0 "No_Failure" 1 "HVB_Thermal_runaway" 2 "HVB_Temperature_Critical" 3 "HVB_Electrical_Fault_Critical" 4 "HVB_HW_Fault_Critical" 5 "Communication_Fault_Critical" 6 "HVB_Temperature_Warning" 7 "HVB_Electrical_Fault_Warning" 8 "HVB_HW_Fault_Warning" 9 "Communication_Fault_Warning" 10 "Crash_Warning" 11 "HVB_SOH_warning" 12 "HVB_SOC_low" 13 "HVB_SOC_mid" 14 "HVB_SOC_high" 15 "HVB_Charge_needed_less_than_one_day" 16 "HVB_Charge_needed_less_than_X_days" 17 "not_used" 18 "not_used" 19 "not_used" 20 "not_used" 21 "not_used" 22 "not_used" 23 "not_used" 24 "not_used" 25 "not_used" 26 "not_used" 27 "not_used" 28 "not_used" 29 "not_used" 30 "not_used" 31 "not_used" ;
VAL_ 1485 HVBStatus 0 "Not_Present" 1 "Degraded" 2 "Critical" 3 "Not_Used" ;
VAL_ 1485 HVBSOC_Status_China_HMI 0 "Normal" 1 "Degraded" ;
VAL_ 1533 Fdbk_Pos_Hor_LH_Exmi 255 "Invalid_Signal" ;
VAL_ 1533 Fdbk_Pos_Ver_LH_Exmi 255 "Invalid_Signal" ;
VAL_ 1533 Fdbk_Pos_Hor_RH_Exmi 255 "Invalid_Signal" ;
VAL_ 1533 Fdbk_Pos_Ver_RH_Exmi 255 "Invalid_Signal" ;
VAL_ 1533 MirrorsProfileSts 0 "Ready" 1 "Fail_Present" 2 "ProfileReached" 3 "ManualReached" 4 "ProfileOrMemoryMoving" 5 "ManualMoving" 6 "NBCInternalFunction" 7 "Not_Used" ;
VAL_ 1673 AirQualityIndexExternal 0 "No_visual_feedback" 1 "_1" 2 "_2" 3 "_3" 4 "_4" 5 "_5" 6 "_6" 7 "_7" 8 "_8" 9 "_9" 10 "_10" 11 "_11" 12 "_12" 13 "_13" 14 "_14" 15 "_15" 16 "_16" 17 "_17" 18 "_18" 19 "_19" 20 "_20" 21 "_21" 22 "_22" 23 "_23" 24 "_24" 25 "_25" 26 "_26" 27 "_27" 28 "_28" 29 "_29" 30 "_30" 31 "_31" 32 "_32" 33 "_33" 34 "_34" 35 "_35" 36 "_36" 37 "_37" 38 "_38" 39 "_39" 40 "_40" 41 "_41" 42 "_42" 43 "_43" 44 "_44" 45 "_45" 46 "_46" 47 "_47" 48 "_48" 49 "_49" 50 "_50" 51 "_51" 52 "_52" 53 "_53" 54 "_54" 55 "_55" 56 "_56" 57 "_57" 58 "_58" 59 "_59" 60 "_60" 61 "_61" 62 "_62" 63 "_63" 64 "_64" 65 "_65" 66 "_66" 67 "_67" 68 "_68" 69 "_69" 70 "_70" 71 "_71" 72 "_72" 73 "_73" 74 "_74" 75 "_75" 76 "_76" 77 "_77" 78 "_78" 79 "_79" 80 "_80" 81 "_81" 82 "_82" 83 "_83" 84 "_84" 85 "_85" 86 "_86" 87 "_87" 88 "_88" 89 "_89" 90 "_90" 91 "_91" 92 "_92" 93 "_93" 94 "_94" 95 "_95" 96 "_96" 97 "_97" 98 "_98" 99 "_99" 100 "_100" 101 "_101" 102 "_102" 103 "_103" 104 "_104" 105 "_105" 106 "_106" 107 "_107" 108 "_108" 109 "_109" 110 "_110" 111 "_111" 112 "_112" 113 "_113" 114 "_114" 115 "_115" 116 "_116" 117 "_117" 118 "_118" 119 "_119" 120 "_120" 121 "_121" 122 "_122" 123 "_123" 124 "_124" 125 "_125" 126 "_126" 127 "_127" 128 "_128" 129 "_129" 130 "_130" 131 "_131" 132 "_132" 133 "_133" 134 "_134" 135 "_135" 136 "_136" 137 "_137" 138 "_138" 139 "_139" 140 "_140" 141 "_141" 142 "_142" 143 "_143" 144 "_144" 145 "_145" 146 "_146" 147 "_147" 148 "_148" 149 "_149" 150 "_150" 151 "_151" 152 "_152" 153 "_153" 154 "_154" 155 "_155" 156 "_156" 157 "_157" 158 "_158" 159 "_159" 160 "_160" 161 "_161" 162 "_162" 163 "_163" 164 "_164" 165 "_165" 166 "_166" 167 "_167" 168 "_168" 169 "_169" 170 "_170" 171 "_171" 172 "_172" 173 "_173" 174 "_174" 175 "_175" 176 "_176" 177 "_177" 178 "_178" 179 "_179" 180 "_180" 181 "_181" 182 "_182" 183 "_183" 184 "_184" 185 "_185" 186 "_186" 187 "_187" 188 "_188" 189 "_189" 190 "_190" 191 "_191" 192 "_192" 193 "_193" 194 "_194" 195 "_195" 196 "_196" 197 "_197" 198 "_198" 199 "_199" 200 "_200" 201 "_201" 202 "_202" 203 "_203" 204 "_204" 205 "_205" 206 "_206" 207 "_207" 208 "_208" 209 "_209" 210 "_210" 211 "_211" 212 "_212" 213 "_213" 214 "_214" 215 "_215" 216 "_216" 217 "_217" 218 "_218" 219 "_219" 220 "_220" 221 "_221" 222 "_222" 223 "_223" 224 "_224" 225 "_225" 226 "_226" 227 "_227" 228 "_228" 229 "_229" 230 "_230" 231 "_231" 232 "_232" 233 "_233" 234 "_234" 235 "_235" 236 "_236" 237 "_237" 238 "_238" 239 "_239" 240 "_240" 241 "_241" 242 "_242" 243 "_243" 244 "_244" 245 "_245" 246 "_246" 247 "_247" 248 "_248" 249 "_249" 250 "_250" 251 "_251" 252 "_252" 253 "_253" 254 "_254" 255 "_255" 256 "_256" 257 "_257" 258 "_258" 259 "_259" 260 "_260" 261 "_261" 262 "_262" 263 "_263" 264 "_264" 265 "_265" 266 "_266" 267 "_267" 268 "_268" 269 "_269" 270 "_270" 271 "_271" 272 "_272" 273 "_273" 274 "_274" 275 "_275" 276 "_276" 277 "_277" 278 "_278" 279 "_279" 280 "_280" 281 "_281" 282 "_282" 283 "_283" 284 "_284" 285 "_285" 286 "_286" 287 "_287" 288 "_288" 289 "_289" 290 "_290" 291 "_291" 292 "_292" 293 "_293" 294 "_294" 295 "_295" 296 "_296" 297 "_297" 298 "_298" 299 "_299" 300 "_300" 301 "_301" 302 "_302" 303 "_303" 304 "_304" 305 "_305" 306 "_306" 307 "_307" 308 "_308" 309 "_309" 310 "_310" 311 "_311" 312 "_312" 313 "_313" 314 "_314" 315 "_315" 316 "_316" 317 "_317" 318 "_318" 319 "_319" 320 "_320" 321 "_321" 322 "_322" 323 "_323" 324 "_324" 325 "_325" 326 "_326" 327 "_327" 328 "_328" 329 "_329" 330 "_330" 331 "_331" 332 "_332" 333 "_333" 334 "_334" 335 "_335" 336 "_336" 337 "_337" 338 "_338" 339 "_339" 340 "_340" 341 "_341" 342 "_342" 343 "_343" 344 "_344" 345 "_345" 346 "_346" 347 "_347" 348 "_348" 349 "_349" 350 "_350" 351 "_351" 352 "_352" 353 "_353" 354 "_354" 355 "_355" 356 "_356" 357 "_357" 358 "_358" 359 "_359" 360 "_360" 361 "_361" 362 "_362" 363 "_363" 364 "_364" 365 "_365" 366 "_366" 367 "_367" 368 "_368" 369 "_369" 370 "_370" 371 "_371" 372 "_372" 373 "_373" 374 "_374" 375 "_375" 376 "_376" 377 "_377" 378 "_378" 379 "_379" 380 "_380" 381 "_381" 382 "_382" 383 "_383" 384 "_384" 385 "_385" 386 "_386" 387 "_387" 388 "_388" 389 "_389" 390 "_390" 391 "_391" 392 "_392" 393 "_393" 394 "_394" 395 "_395" 396 "_396" 397 "_397" 398 "_398" 399 "_399" 400 "_400" 401 "_401" 402 "_402" 403 "_403" 404 "_404" 405 "_405" 406 "_406" 407 "_407" 408 "_408" 409 "_409" 410 "_410" 411 "_411" 412 "_412" 413 "_413" 414 "_414" 415 "_415" 416 "_416" 417 "_417" 418 "_418" 419 "_419" 420 "_420" 421 "_421" 422 "_422" 423 "_423" 424 "_424" 425 "_425" 426 "_426" 427 "_427" 428 "_428" 429 "_429" 430 "_430" 431 "_431" 432 "_432" 433 "_433" 434 "_434" 435 "_435" 436 "_436" 437 "_437" 438 "_438" 439 "_439" 440 "_440" 441 "_441" 442 "_442" 443 "_443" 444 "_444" 445 "_445" 446 "_446" 447 "_447" 448 "_448" 449 "_449" 450 "_450" 451 "_451" 452 "_452" 453 "_453" 454 "_454" 455 "_455" 456 "_456" 457 "_457" 458 "_458" 459 "_459" 460 "_460" 461 "_461" 462 "_462" 463 "_463" 464 "_464" 465 "_465" 466 "_466" 467 "_467" 468 "_468" 469 "_469" 470 "_470" 471 "_471" 472 "_472" 473 "_473" 474 "_474" 475 "_475" 476 "_476" 477 "_477" 478 "_478" 479 "_479" 480 "_480" 481 "_481" 482 "_482" 483 "_483" 484 "_484" 485 "_485" 486 "_486" 487 "_487" 488 "_488" 489 "_489" 490 "_490" 491 "_491" 492 "_492" 493 "_493" 494 "_494" 495 "_495" 496 "_496" 497 "_497" 498 "_498" 499 "_499" 500 "_500" 501 "Not_used" 502 "Not_used" 503 "Not_used" 504 "Not_used" 505 "Not_used" 506 "Not_used" 507 "Not_used" 508 "Not_used" 509 "Not_used" 510 "Not_used" 511 "Not_used" ;
VAL_ 1673 NCL_EnergyProfileFbk 0 "Normal" 1 "Eco" 2 "Low_Driver" 3 "Low_Auto" 4 "Degraded" 5 "Not_Used" 6 "Not_Used" 7 "Not_Used" ;
VAL_ 1726 CabinLightNightDaySwitch 0 "Not_Active" 1 "Active" ;
VAL_ 1726 CabinLight_Feet_Enable 0 "Off" 1 "On" ;
VAL_ 1726 CabinLight_DoorPanel_Enable 0 "Off" 1 "On" ;
VAL_ 1726 AutoDoorsAlert 0 "Not_Enable" 1 "Enable" ;
VAL_ 1726 EManettinoPreset 0 "No_Request" 1 "Edrive_ECO" 2 "Standard" 3 "Performance" 4 "Qualifying" 5 "Not_used" 6 "Not_used" 7 "Not_used" ;
VAL_ 1726 SmartOverbrakingEnable 0 "Enable" 1 "Not_Enable" ;
VAL_ 1726 CabinLight_Feet_Level 0 "Level_1" 1 "Level_2" 2 "Level_3" 3 "Level_4" 4 "Level_5" 5 "Level_6" 6 "Level_7" 7 "Level_8" 8 "Level_9" 9 "Level_10" 10 "Not_Used" 11 "Not_Used" 12 "Not_Used" 13 "Not_Used" 14 "Not_Used" 15 "Not_Used" ;
VAL_ 1726 CabinLight_DoorPanel_Level 0 "Level_1" 1 "Level_2" 2 "Level_3" 3 "Level_4" 4 "Level_5" 5 "Level_6" 6 "Level_7" 7 "Level_8" 8 "Level_9" 9 "Level_10" 10 "Not_Used" 11 "Not_Used" 12 "Not_Used" 13 "Not_Used" 14 "Not_Used" 15 "Not_Used" ;
VAL_ 1726 InternalLightEnable 0 "Not_Enable" 1 "Enable" ;
VAL_ 1726 ChargePlugAutoUnlock 0 "Off" 1 "Unlock with vehicle locked" 2 "Unlock at charge completed with vehicle lock" 3 "Not_Used" ;
VAL_ 1726 ActiveProfile 0 "Guest_Profile" 1 "Profile_1" 2 "Profile_2" 3 "Profile_3" 4 "Profile_4" 5 "Profile_5" 6 "Profile_6" 7 "Profile_7" 8 "Profile_8" 9 "Profile_9" 10 "Profile_10" ;
VAL_ 1726 PassiveEntryEnable 0 "Not_Enabled" 1 "Enabled" ;
VAL_ 1726 PersonalDataConsentSts 0 "Init" 1 "Given" 2 "NotGiven" 3 "NotGiven_ResetData" ;
VAL_ 1726 StealthModeActive 0 "Not_Active" 1 "Active" ;
VAL_ 1726 User_SOC_Preset 0 "Not_Active" 1 "Preset1" 2 "Preset2" 3 "Preset3" ;
VAL_ 1726 ChargeFlapUnlock 0 "Not_Enable" 1 "Enable" ;
VAL_ 1726 AntiTiltAlarmCommand 0 "Active" 1 "Not_Active" ;
VAL_ 1728 BatteryType 0 "IBS_not_present" 1 "Reserved" 2 "Reserved" 3 "Reserved" 4 "Reserved" 5 "Reserved" 6 "Reserved" 7 "Reserved" 8 "Reserved" 9 "A123_60Ah" 10 "Odissey_70_Ah" 11 "Odissey_95_Ah" 12 "FIAMM_80_Ah" 13 "FIAMM_95_Ah" 14 "FIAMM_70_Ah" 15 "ERROR" ;
VAL_ 1728 Profile 0 "absent" 1 "present" ;
VAL_ 1735 NPRSts 0 "Not Active" 1 "Active" 2 "Degraded_System" ;
VAL_ 1735 NPRFailSts 0 "Fail_Not_Present" 1 "Fail_Present" ;
VAL_ 1735 NPRLoadFailSts 0 "Fail_Not_Present" 1 "Fail_Present" ;
VAL_ 1735 NPR48VFailSts 0 "Fail_Not_Present" 1 "Fail_Present" ;
VAL_ 1735 GLASS_TEMP_NPR 251 "Not_used" 252 "Not_ready" 253 "Value_exceeds_limits" 254 "Error" 255 "SNA" ;
VAL_ 1752 IntErr_ThmDisconnect 0 "No_Error" 1 "Error" ;
VAL_ 1752 IntErr_CoilDisconnect 0 "No_Error" 1 "Error" ;
VAL_ 1752 IntErr_CoilOverTemp 0 "No_Error" 1 "Error" ;
VAL_ 1752 IntErr_I2C_CommFault 0 "NoError" 1 "Error" ;
VAL_ 1752 WCM_Status 0 "READY TO CHARGE" 1 "BASIC POWER PROFILE CHARGE" 2 "EXTENDED POWER PROFILE CHARGE" 3 "SAMSUNG FAST CHARGE" 4 "APPLE FAST CHARGE" 5 "CHARGE COMPLETE" 6 "SCAN FOR RX" 7 "BATTERY STAND BY" 8 "FOB STAND BY" 9 "FOREIGN OBJ DETECT ON CHARGE" 10 "FOREIGN OBJ DETECT Not CHARGING" 11 "Not used" 12 "Not used" 13 "Not used" 14 "Not used" 15 "SYSTEM ERROR" ;
VAL_ 1752 IntErr_Eeprom_failure 0 "No_Error" 1 "Error" ;
VAL_ 1752 IntErr_Reflash_aborted 0 "No_Error" 1 "Error" ;
VAL_ 1752 WCM_Node 0 "Absent" 1 "Present" ;
VAL_ 1752 ResponseErrorWCM 0 "No_Error" 1 "Error" ;
VAL_ 1752 KeepAliveWCM 0 "no_Request_By_slave" 1 "Request_By_slave" ;
VAL_ 1752 CurrentFailWCM 0 "No_Error" 1 "Error" ;
VAL_ 1752 GenericFailWCM 0 "No_Error" 1 "Error" ;
VAL_ 1764 FSFCWPlusActivationMode 0 "Near" 1 "Med" 2 "Far" 3 "INIT" ;
VAL_ 1764 FSFCWPlusSetting 0 "Off" 1 "Audio" 2 "Brake" 3 "Audio_Brake" 4 "INIT" 5 "not_used" ;
VAL_ 1764 AutoHighBeamEnable 0 "Not_Enable" 1 "Enable" ;
VAL_ 1764 LDW_Sensibility 0 "Early" 1 "Med" 2 "Late" 3 "Init" ;
VAL_ 1764 LDWRequestSts 0 "Init" 1 "Not_Active" 2 "Active" 3 "Not_used" ;
VAL_ 1764 TSREnable 0 "Init" 1 "Not_Enable" 2 "Enable" 3 "not_used" ;
VAL_ 1764 LDWWarningType 0 "Acoustic" 1 "Vibration" 2 "Acoustic_Vibration" 3 "Init" ;
VAL_ 1764 DistanceUnit 0 "Km" 1 "Miles" ;
VAL_ 1764 AFSEnable 0 "OFF" 1 "ON" ;
VAL_ 1764 BSDEnable 0 "Not_Enable" 1 "Enable_LED" 2 "Enable_LED_Chime" 3 "Init" ;
VAL_ 1764 DDA_Enable 0 "Init" 1 "Enable" 2 "Not_Enable" 3 "not_used" ;
VAL_ 1764 HDC_Enable 0 "OFF" 1 "ON" ;
VAL_ 1764 LDWAssistType 0 "Warning_Only" 1 "Warning_Keeping" ;
VAL_ 1764 ACC_DistCmd 0 "No_Setting" 1 "D1" 2 "D2" 3 "D3" 4 "D4" 5 "INIT" 6 "not_used" 7 "not_used" ;
VAL_ 1767 LanguageSelection 0 "Italian" 1 "Deutch" 2 "English" 3 "Espanol" 4 "Francais" 5 "Russian" 6 "American" 7 "Portuguese" 8 "Chinese" 9 "Japanese" 10 "Arabic" 11 "Turkish" 12 "Not_used" 13 "FrancaisCA" 14 "SpanishMX" 15 "Polish" 16 "Reserved" 17 "Reserved" 18 "Reserved" 19 "Reserved" 20 "Reserved" 21 "Reserved" 22 "Reserved" 23 "Reserved" 24 "Reserved" 25 "Reserved" 26 "Reserved" 27 "Reserved" 28 "Reserved" 29 "Reserved" 30 "Reserved" 31 "Reserved" 32 "Reserved" 33 "Reserved" 34 "Reserved" 35 "Reserved" 36 "Reserved" 37 "Reserved" 38 "Reserved" 39 "Reserved" 40 "Reserved" 41 "Reserved" 42 "Reserved" 43 "Reserved" 44 "Reserved" 45 "Reserved" 46 "Reserved" 47 "Reserved" 48 "Reserved" 49 "Reserved" 50 "Reserved" 51 "Reserved" 52 "Reserved" 53 "Reserved" 54 "Reserved" 55 "Reserved" 56 "Reserved" 57 "Reserved" 58 "Reserved" 59 "Reserved" 60 "Reserved" 61 "Reserved" 62 "Reserved" 63 "Reserved" ;
VAL_ 1767 TemperatureUnit 0 "_C" 1 "_F" ;
VAL_ 1767 DistanceUnit 0 "Km" 1 "Miles" ;
VAL_ 1767 AutomaticMirrorFoldingEnable 0 "Not_Enable" 1 "Enable" ;
VAL_ 1767 HourMode 0 "_0_24_h" 1 "_0_12_h" ;
VAL_ 1767 WiperRLSSensibility 0 "position_1" 1 "position_2" 2 "position_3" 3 "position_4" ;
VAL_ 1767 WelcomeInCarEnable 0 "Not_Enable" 1 "Enable" ;
VAL_ 1767 BuzzerVolumeWarning 0 "Level_0_min_volume" 1 "Level_1" 2 "Level_2" 3 "Level_3" 4 "Level_4" 5 "Level_5" 6 "Level_6" 7 "Level_7_max_volume" ;
VAL_ 1767 LockTimeout 0 "_15s" 1 "_30s" 2 "_45s" 3 "Init" ;
VAL_ 1767 ResetTripAReq 0 "No_request" 1 "Reset_Trip_Request" ;
VAL_ 1767 DriverDoorUnlockEnable 0 "Not_Enable" 1 "Enable" ;
VAL_ 1767 SpeedLockDoorEnable 0 "Not_Enable" 1 "Enable" ;
VAL_ 1767 ExternalLightSensorLevel 0 "Level_3" 1 "Level_2" 2 "Level_1" 3 "Level_0_Not_Used" ;
VAL_ 1767 SpeedThresholdEnable 0 "Not_Enable" 1 "Enable" ;
VAL_ 1767 WalkAwayEnabled 0 "Disable" 1 "Enable" ;
VAL_ 1767 GloveBoxUnlockEnable 0 "Enable" 1 "Not_Enable" ;
VAL_ 1767 Stop_GoEnable 0 "Disable" 1 "Enable" ;
VAL_ 1767 EngineSpeedDisplayLedEnable 0 "Disable" 1 "Enable" ;
VAL_ 1767 SnowChainMode 0 "Not_Active" 1 "Active" ;
VAL_ 1767 PressureUnit 0 "bar" 1 "psi" ;
VAL_ 1767 RPMAreaColor 0 "Yellow" 1 "Red" 2 "Black" 3 "White" 4 "Silver" 5 "not_used" 6 "not_used" 7 "not_used" ;
VAL_ 1767 NTPCalibrationReqSts 0 "no_Request" 1 "Request" ;
VAL_ 1767 EmergencyStopSignallingEnable 0 "Disable" 1 "Enable" ;
VAL_ 1767 RearAutoDoorAlert 0 "Not_Enable" 1 "Enable" ;
VAL_ 1767 MirrorAutoTiltEnable 0 "Not_Enable" 1 "Enable" ;
VAL_ 1767 SpeedLimitSignEnable 0 "Not_Enable" 1 "Enable" ;
VAL_ 1767 TrafficChangeEnable 0 "INIT" 1 "active" 2 "Not_Active" 3 "Not_used" ;
VAL_ 1767 AutolockEnable 0 "Disabled" 1 "Enabled" ;
VAL_ 1772 SingleDoorUnlockEnable 0 "All" 1 "Single" ;
VAL_ 1772 LongParkingSetting 0 "OFF" 1 "ON" 2 "not_used" 3 "INIT" ;
VAL_ 1772 FeetLightKeyOnActivation 0 "Off" 1 "All_On" 2 "Front_On" 3 "Rear_On" ;
VAL_ 1772 AmbientLightEnable 0 "Not_Enabled" 1 "Enabled" ;
VAL_ 1772 ShowOnDisplay_Seats 0 "On" 1 "Auto" 2 "Off" 3 "Not_used" ;
VAL_ 1772 ShowOnDisplay_Climate 0 "On" 1 "Auto" 2 "Off" 3 "Not_used" ;
VAL_ 1772 ShowOnDisplay_Time_Temperature 0 "ON" 1 "OFF" ;
VAL_ 1772 EasyEntrySet 0 "Init" 1 "Off" 2 "SteeringWheel" 3 "SteeringWheel_Seat" ;
VAL_ 1772 NIT_PassengerExtendedClimate 0 "OFF" 1 "SeatHeating" 2 "SeatVenting" 3 "ALL" ;
VAL_ 1772 NIT_DriverExtendedClimate 0 "OFF" 1 "SeatHeating" 2 "SeatVenting" 3 "ALL" ;
VAL_ 1772 RimHeating_Profile 0 "Not_Active" 1 "Active" ;
VAL_ 1772 LiftGateAlertEnable 0 "Not_Enabled" 1 "Enabled" ;
VAL_ 1772 NIT_RearPassengerExtendedClimate 0 "OFF" 1 "SeatHeating" 2 "SeatVenting" 3 "ALL" ;
VAL_ 1772 Battery_Saving 0 "Not_Active" 1 "Active" ;
VAL_ 1772 RimHeatingCommand 0 "Not_Active" 1 "Active" ;
VAL_ 1772 GmeterReset 0 "Not_Active" 1 "Active" ;
VAL_ 1772 SoundFeedbackLevel 0 "Off" 1 "Low" 2 "Medium" 3 "High" ;
VAL_ 1772 LongParkingUserAction 0 "No_Action" 1 "User_Action" ;
VAL_ 1792 Zero_byte 0 "Fixed" ;
VAL_ 1792 SystemCommand 0 "WU_wake_up_request" 1 "Not_used" 2 "SA_system_Stay_Active_req" 3 "S_system_go_to_Sleep_req" ;
VAL_ 1792 ActiveLoadMaster 0 "No_active_loads_in_master" 1 "Active_loads_in_master" ;
VAL_ 1792 EOL 0 "No_EOL_prog_At_FIAT" 1 "EOL_prog_At_FIAT" ;
VAL_ 1792 GenericFailSts 0 "No_functional_fail_is_present" 1 "At_least_one_funct_fail_pres" ;
VAL_ 1792 P_ES 0 "Fail_Not_Present" 1 "Fail_Present" ;
VAL_ 1792 D_ES 0 "Error_Active_State" 1 "Error_Passive_Warning_State" 2 "Bus_Off_State" 3 "Not_used" ;
VAL_ 1792 Node_24 0 "Currently_not_active_on_the_bus" 1 "Is_currently_active_on_the_bus" ;
VAL_ 1792 Node_25 0 "Currently_not_active_on_the_bus" 1 "Is_currently_active_on_the_bus" ;
VAL_ 1792 Node_26 0 "Currently_not_active_on_the_bus" 1 "Is_currently_active_on_the_bus" ;
VAL_ 1792 Node_27 0 "Currently_not_active_on_the_bus" 1 "Is_currently_active_on_the_bus" ;
VAL_ 1792 Node_28 0 "Currently_not_active_on_the_bus" 1 "Is_currently_active_on_the_bus" ;
VAL_ 1792 Node_29 0 "Currently_not_active_on_the_bus" 1 "Is_currently_active_on_the_bus" ;
VAL_ 1792 Node_30 0 "Currently_not_active_on_the_bus" 1 "Is_currently_active_on_the_bus" ;
VAL_ 1792 Node_31 0 "Currently_not_active_on_the_bus" 1 "Is_currently_active_on_the_bus" ;
VAL_ 1792 Node_16 0 "Currently_not_active_on_the_bus" 1 "Is_currently_active_on_the_bus" ;
VAL_ 1792 Node_17 0 "Currently_not_active_on_the_bus" 1 "Is_currently_active_on_the_bus" ;
VAL_ 1792 Node_18 0 "Currently_not_active_on_the_bus" 1 "Is_currently_active_on_the_bus" ;
VAL_ 1792 Node_19 0 "Currently_not_active_on_the_bus" 1 "Is_currently_active_on_the_bus" ;
VAL_ 1792 Node_20 0 "Currently_not_active_on_the_bus" 1 "Is_currently_active_on_the_bus" ;
VAL_ 1792 Node_21 0 "Currently_not_active_on_the_bus" 1 "Is_currently_active_on_the_bus" ;
VAL_ 1792 Node_22 0 "Currently_not_active_on_the_bus" 1 "Is_currently_active_on_the_bus" ;
VAL_ 1792 Node_23 0 "Currently_not_active_on_the_bus" 1 "Is_currently_active_on_the_bus" ;
VAL_ 1792 Node_08 0 "Currently_not_active_on_the_bus" 1 "Is_currently_active_on_the_bus" ;
VAL_ 1792 Node_09 0 "Currently_not_active_on_the_bus" 1 "Is_currently_active_on_the_bus" ;
VAL_ 1792 Node_10 0 "Currently_not_active_on_the_bus" 1 "Is_currently_active_on_the_bus" ;
VAL_ 1792 Node_11 0 "Currently_not_active_on_the_bus" 1 "Is_currently_active_on_the_bus" ;
VAL_ 1792 Node_12 0 "Currently_not_active_on_the_bus" 1 "Is_currently_active_on_the_bus" ;
VAL_ 1792 Node_13 0 "Currently_not_active_on_the_bus" 1 "Is_currently_active_on_the_bus" ;
VAL_ 1792 Node_14 0 "Currently_not_active_on_the_bus" 1 "Is_currently_active_on_the_bus" ;
VAL_ 1792 Node_15 0 "Currently_not_active_on_the_bus" 1 "Is_currently_active_on_the_bus" ;
VAL_ 1792 Node_00 0 "Currently_not_active_on_the_bus" 1 "Is_currently_active_on_the_bus" ;
VAL_ 1792 Node_01 0 "Currently_not_active_on_the_bus" 1 "Is_currently_active_on_the_bus" ;
VAL_ 1792 Node_02 0 "Currently_not_active_on_the_bus" 1 "Is_currently_active_on_the_bus" ;
VAL_ 1792 Node_03 0 "Currently_not_active_on_the_bus" 1 "Is_currently_active_on_the_bus" ;
VAL_ 1792 Node_04 0 "Currently_not_active_on_the_bus" 1 "Is_currently_active_on_the_bus" ;
VAL_ 1792 Node_05 0 "Currently_not_active_on_the_bus" 1 "Is_currently_active_on_the_bus" ;
VAL_ 1792 Node_06 0 "Currently_not_active_on_the_bus" 1 "Is_currently_active_on_the_bus" ;
VAL_ 1792 Node_07 0 "Currently_not_active_on_the_bus" 1 "Is_currently_active_on_the_bus" ;
VAL_ 1796 Zero_byte 0 "Fixed" ;
VAL_ 1796 SystemStatus 0 "WU_wake_up_request" 1 "Not_used" 2 "SA_system_Stay_Active_req" 3 "Not_used" ;
VAL_ 1796 ActiveLoadSlave 0 "No_active_loads_in_slave" 1 "Active_loads_in_slave" ;
VAL_ 1796 EOL 0 "No_EOL_prog_At_FIAT" 1 "EOL_prog_At_FIAT" ;
VAL_ 1796 GenericFailSts 0 "No_functional_fail_is_present" 1 "At_least_one_funct_fail_pres" ;
VAL_ 1796 CurrentFailSts 0 "No_functional_fail_is_present" 1 "DTCStatus_present" ;
VAL_ 1796 D_ES 0 "Error_Active_State" 1 "Error_Passive_Warning_State" 2 "Bus_Off_State" 3 "Not_used" ;
VAL_ 1801 Zero_byte 0 "Fixed" ;
VAL_ 1801 SystemStatus 0 "WU_wake_up_request" 1 "Not_used" 2 "SA_system_Stay_Active_req" 3 "Not_used" ;
VAL_ 1801 ActiveLoadSlave 0 "No_active_loads_in_slave" 1 "Active_loads_in_slave" ;
VAL_ 1801 EOL 0 "No_EOL_prog_At_FIAT" 1 "EOL_prog_At_FIAT" ;
VAL_ 1801 GenericFailSts 0 "No_functional_fail_is_present" 1 "At_least_one_funct_fail_pres" ;
VAL_ 1801 CurrentFailSts 0 "No_functional_fail_is_present" 1 "DTCStatus_present" ;
VAL_ 1801 D_ES 0 "Error_Active_State" 1 "Error_Passive_Warning_State" 2 "Bus_Off_State" 3 "Not_used" ;
VAL_ 1802 Zero_byte 0 "Fixed" ;
VAL_ 1802 SystemStatus 0 "WU_wake_up_request" 1 "Not_used" 2 "SA_system_Stay_Active_req" 3 "Not_used" ;
VAL_ 1802 ActiveLoadSlave 0 "No_active_loads_in_slave" 1 "Active_loads_in_slave" ;
VAL_ 1802 EOL 0 "No_EOL_prog_At_FIAT" 1 "EOL_prog_At_FIAT" ;
VAL_ 1802 GenericFailSts 0 "No_functional_fail_is_present" 1 "At_least_one_funct_fail_pres" ;
VAL_ 1802 CurrentFailSts 0 "No_functional_fail_is_present" 1 "DTCStatus_present" ;
VAL_ 1802 D_ES 0 "Error_Active_State" 1 "Error_Passive_Warning_State" 2 "Bus_Off_State" 3 "Not_used" ;
VAL_ 1810 Zero_byte 0 "Fixed" ;
VAL_ 1810 SystemStatus 0 "WU_wake_up_request" 1 "Not_used" 2 "SA_system_Stay_Active_req" 3 "Not_used" ;
VAL_ 1810 ActiveLoadSlave 0 "No_active_loads_in_slave" 1 "Active_loads_in_slave" ;
VAL_ 1810 EOL 0 "No_EOL_prog_At_FIAT" 1 "EOL_prog_At_FIAT" ;
VAL_ 1810 GenericFailSts 0 "No_functional_fail_is_present" 1 "At_least_one_funct_fail_pres" ;
VAL_ 1810 CurrentFailSts 0 "No_functional_fail_is_present" 1 "DTCStatus_present" ;
VAL_ 1810 D_ES 0 "Error_Active_State" 1 "Error_Passive_Warning_State" 2 "Bus_Off_State" 3 "Not_used" ;
VAL_ 1815 Zero_byte 0 "Fixed" ;
VAL_ 1815 SystemStatus 0 "WU_wake_up_request" 1 "Not_used" 2 "SA_system_Stay_Active_req" 3 "Not_used" ;
VAL_ 1815 ActiveLoadSlave 0 "No_active_loads_in_slave" 1 "Active_loads_in_slave" ;
VAL_ 1815 EOL 0 "No_EOL_prog_At_FIAT" 1 "EOL_prog_At_FIAT" ;
VAL_ 1815 GenericFailSts 0 "No_functional_fail_is_present" 1 "At_least_one_funct_fail_pres" ;
VAL_ 1815 CurrentFailSts 0 "No_functional_fail_is_present" 1 "DTCStatus_present" ;
VAL_ 1815 D_ES 0 "Error_Active_State" 1 "Error_Passive_Warning_State" 2 "Bus_Off_State" 3 "Not_used" ;
VAL_ 1816 Zero_byte 0 "Fixed" ;
VAL_ 1816 SystemStatus 0 "WU_wake_up_request" 1 "Not_used" 2 "SA_system_Stay_Active_req" 3 "Not_used" ;
VAL_ 1816 ActiveLoadSlave 0 "No_active_loads_in_slave" 1 "Active_loads_in_slave" ;
VAL_ 1816 EOL 0 "No_EOL_prog_At_FIAT" 1 "EOL_prog_At_FIAT" ;
VAL_ 1816 GenericFailSts 0 "No_functional_fail_is_present" 1 "At_least_one_funct_fail_pres" ;
VAL_ 1816 CurrentFailSts 0 "No_functional_fail_is_present" 1 "DTCStatus_present" ;
VAL_ 1816 D_ES 0 "Error_Active_State" 1 "Error_Passive_Warning_State" 2 "Bus_Off_State" 3 "Not_used" ;
VAL_ 1823 Zero_byte 0 "Fixed" ;
VAL_ 1823 SystemStatus 0 "WU_wake_up_request" 1 "Not_used" 2 "SA_system_Stay_Active_req" 3 "Not_used" ;
VAL_ 1823 ActiveLoadSlave 0 "No_active_loads_in_slave" 1 "Active_loads_in_slave" ;
VAL_ 1823 EOL 0 "No_EOL_prog_At_FIAT" 1 "EOL_prog_At_FIAT" ;
VAL_ 1823 GenericFailSts 0 "No_functional_fail_is_present" 1 "At_least_one_funct_fail_pres" ;
VAL_ 1823 CurrentFailSts 0 "No_functional_fail_is_present" 1 "DTCStatus_present" ;
VAL_ 1823 D_ES 0 "Error_Active_State" 1 "Error_Passive_Warning_State" 2 "Bus_Off_State" 3 "Not_used" ;
VAL_ 2510948868 blower_warning 0 "Normal" 1 "Warning" ;
VAL_ 2510948868 blower_critical 0 "Normal" 1 "Critical" ;
VAL_ 2510948868 blower_low_voltage 0 "Normal_Voltage" 1 "Low_Voltage" ;
VAL_ 2510948869 Roof_Present02 0 "not_activated" 1 "activated" ;
VAL_ 2510948869 EVDC_enabled02 0 "not_activated" 1 "activated" ;
VAL_ 2510948869 stop_and_start02 0 "not_activated" 1 "activated" ;
VAL_ 2510948869 driver_side02 0 "left" 1 "right" ;
VAL_ 2510948869 CarModel 0 "_151M" 1 "_152M" 2 "_164" 3 "not_used" ;
VAL_ 2510948869 MMI_buttons_type_2_count02 0 "AUTO" 1 "Rear" 2 "not_used" 3 "not_used" 4 "not_used" 5 "not_used" 6 "not_used" 7 "not_used" ;
VAL_ 2510948869 MMI_buttons_type_1_count02 0 "Fan" 1 "Max_Defrost" 2 "Recirculation" 3 "activated" 4 "Mode" 5 "not_used" 6 "not_used" 7 "not_used" ;
VAL_ 2654208034 Zero_byte_KHD 0 "Fixed" ;
VAL_ 2654208034 SystemStatus_KHD 0 "WU_wake_up_request" 1 "Not_used" 2 "SA_system_Stay_Active_req" 3 "Not_used" ;
VAL_ 2654208034 ActiveLoadSlave_KHD 0 "No_active_loads_in_slave" 1 "Active_loads_in_slave" ;
VAL_ 2654208034 EOL_KHD 0 "No_EOL_programming_at_Fiat" 1 "EOL_programming_at_Fiat" ;
VAL_ 2654208034 GenericFailSts_KHD 0 "No_functional_fail_is_present" 1 "At_least_one_funct_fail_pres" ;
VAL_ 2654208034 CurrentFailSts_KHD 0 "No_functional_fail_is_present" 1 "At_least_a_DTC_present_is_set" ;
VAL_ 2654208034 D_ES_KHD 0 "Error_Active_State" 1 "Error_Passive_Warning_State" 2 "Bus_Off_State" 3 "Not_used" ;
VAL_ 2654208055 Zero_byte 0 "Fixed" ;
VAL_ 2654208055 SystemStatus 0 "WU_wake_up_request" 1 "Not_used" 2 "SA_system_Stay_Active_req" 3 "Not_used" ;
VAL_ 2654208055 ActiveLoadSlave 0 "No_active_loads_in_slave" 1 "Active_loads_in_slave" ;
VAL_ 2654208055 EOL 0 "No_EOL_prog_At_FIAT" 1 "EOL_prog_At_FIAT" ;
VAL_ 2654208055 GenericFailSts 0 "No_functional_fail_is_present" 1 "At_least_one_funct_fail_pres" ;
VAL_ 2654208055 CurrentFailSts 0 "No_functional_fail_is_present" 1 "DTCStatus_present" ;
VAL_ 2654208055 D_ES 0 "Error_Active_State" 1 "Error_Passive_Warning_State" 2 "Bus_Off_State" 3 "Not_used" ;
VAL_ 2654208056 Zero_byte 0 "Fixed" ;
VAL_ 2654208056 SystemStatus 0 "WU_wake_up_request" 1 "Not_used" 2 "SA_system_Stay_Active_req" 3 "Not_used" ;
VAL_ 2654208056 ActiveLoadSlave 0 "No_active_loads_in_slave" 1 "Active_loads_in_slave" ;
VAL_ 2654208056 EOL 0 "No_EOL_prog_At_FIAT" 1 "EOL_prog_At_FIAT" ;
VAL_ 2654208056 GenericFailSts 0 "No_functional_fail_is_present" 1 "At_least_one_funct_fail_pres" ;
VAL_ 2654208056 CurrentFailSts 0 "No_functional_fail_is_present" 1 "DTCStatus_present" ;
VAL_ 2654208056 D_ES 0 "Error_Active_State" 1 "Error_Passive_Warning_State" 2 "Bus_Off_State" 3 "Not_used" ;
VAL_ 2654208081 Zero_byte_RSL 0 "Fixed" ;
VAL_ 2654208081 SystemStatus_RSL 0 "WU_wake_up_request" 1 "Not_used" 2 "SA_system_Stay_Active_req" 3 "Not_used" ;
VAL_ 2654208081 ActiveLoadSlave_RSL 0 "No_active_loads_in_slave" 1 "Active_loads_in_slave" ;
VAL_ 2654208081 EOL_RSL 0 "No_EOL_programming_at_Fiat" 1 "EOL_programming_at_Fiat" ;
VAL_ 2654208081 GenericFailSts_RSL 0 "No_functional_fail_is_present" 1 "At_least_one_funct_fail_pres" ;
VAL_ 2654208081 CurrentFailSts_RSL 0 "No_functional_fail_is_present" 1 "At_least_a_DTC_present_is_set" ;
VAL_ 2654208081 D_ES_RSL 0 "Error_Active_State" 1 "Error_Passive_Warning_State" 2 "Bus_Off_State" 3 "Not_used" ;
VAL_ 2654208082 Zero_byte_RSR 0 "Fixed" ;
VAL_ 2654208082 SystemStatus_RSR 0 "WU_wake_up_request" 1 "Not_used" 2 "SA_system_Stay_Active_req" 3 "Not_used" ;
VAL_ 2654208082 ActiveLoadSlave_RSR 0 "No_active_loads_in_slave" 1 "Active_loads_in_slave" ;
VAL_ 2654208082 EOL_RSR 0 "No_EOL_programming_at_Fiat" 1 "EOL_programming_at_Fiat" ;
VAL_ 2654208082 GenericFailSts_RSR 0 "No_functional_fail_is_present" 1 "At_least_one_funct_fail_pres" ;
VAL_ 2654208082 CurrentFailSts_RSR 0 "No_functional_fail_is_present" 1 "At_least_a_DTC_present_is_set" ;
VAL_ 2654208082 D_ES_RSR 0 "Error_Active_State" 1 "Error_Passive_Warning_State" 2 "Bus_Off_State" 3 "Not_used" ;
VAL_ 2654208094 Zero_byte_ELL 0 "Fixed" ;
VAL_ 2654208094 SystemStatus_ELL 0 "WU_wake_up_request" 1 "Not_used" 2 "SA_system_Stay_Active_req" 3 "Not_used" ;
VAL_ 2654208094 ActiveLoadSlave_ELL 0 "No_active_loads_in_slave" 1 "Active_loads_in_slave" ;
VAL_ 2654208094 EOL_ELL 0 "No_EOL_programming_at_Fiat" 1 "EOL_programming_at_Fiat" ;
VAL_ 2654208094 GenericFailSts_ELL 0 "No_functional_fail_is_present" 1 "At_least_one_funct_fail_pres" ;
VAL_ 2654208094 CurrentFailSts_ELL 0 "No_functional_fail_is_present" 1 "At_least_a_DTC_present_is_set" ;
VAL_ 2654208094 D_ES_ELL 0 "Error_Active_State" 1 "Error_Passive_Warning_State" 2 "Bus_Off_State" 3 "Not_used" ;
VAL_ 2654208095 Zero_byte_ELR 0 "Fixed" ;
VAL_ 2654208095 SystemStatus_ELR 0 "WU_wake_up_request" 1 "Not_used" 2 "SA_system_Stay_Active_req" 3 "Not_used" ;
VAL_ 2654208095 ActiveLoadSlave_ELR 0 "No_active_loads_in_slave" 1 "Active_loads_in_slave" ;
VAL_ 2654208095 EOL_ELR 0 "No_EOL_programming_at_Fiat" 1 "EOL_programming_at_Fiat" ;
VAL_ 2654208095 GenericFailSts_ELR 0 "No_functional_fail_is_present" 1 "At_least_one_funct_fail_pres" ;
VAL_ 2654208095 CurrentFailSts_ELR 0 "No_functional_fail_is_present" 1 "At_least_a_DTC_present_is_set" ;
VAL_ 2654208095 D_ES_ELR 0 "Error_Active_State" 1 "Error_Passive_Warning_State" 2 "Bus_Off_State" 3 "Not_used" ;
VAL_ 2654208096 Zero_byte_ERL 0 "Fixed" ;
VAL_ 2654208096 SystemStatus_ERL 0 "WU_wake_up_request" 1 "Not_used" 2 "SA_system_Stay_Active_req" 3 "Not_used" ;
VAL_ 2654208096 ActiveLoadSlave_ERL 0 "No_active_loads_in_slave" 1 "Active_loads_in_slave" ;
VAL_ 2654208096 EOL_ERL 0 "No_EOL_programming_at_Fiat" 1 "EOL_programming_at_Fiat" ;
VAL_ 2654208096 GenericFailSts_ERL 0 "No_functional_fail_is_present" 1 "At_least_one_funct_fail_pres" ;
VAL_ 2654208096 CurrentFailSts_ERL 0 "No_functional_fail_is_present" 1 "At_least_a_DTC_present_is_set" ;
VAL_ 2654208096 D_ES_ERL 0 "Error_Active_State" 1 "Error_Passive_Warning_State" 2 "Bus_Off_State" 3 "Not_used" ;
VAL_ 2654208097 Zero_byte_ERR 0 "Fixed" ;
VAL_ 2654208097 SystemStatus_ERR 0 "WU_wake_up_request" 1 "Not_used" 2 "SA_system_Stay_Active_req" 3 "Not_used" ;
VAL_ 2654208097 ActiveLoadSlave_ERR 0 "No_active_loads_in_slave" 1 "Active_loads_in_slave" ;
VAL_ 2654208097 EOL_ERR 0 "No_EOL_programming_at_Fiat" 1 "EOL_programming_at_Fiat" ;
VAL_ 2654208097 GenericFailSts_ERR 0 "No_functional_fail_is_present" 1 "At_least_one_funct_fail_pres" ;
VAL_ 2654208097 CurrentFailSts_ERR 0 "No_functional_fail_is_present" 1 "At_least_a_DTC_present_is_set" ;
VAL_ 2654208097 D_ES_ERR 0 "Error_Active_State" 1 "Error_Passive_Warning_State" 2 "Bus_Off_State" 3 "Not_used" ;
VAL_ 2654208120 Zero_byte_NPR 0 "Fixed" ;
VAL_ 2654208120 SystemStatus_NPR 0 "WU_wake_up_request" 1 "Not_used" 2 "SA_system_Stay_Active_req" 3 "Not_used" ;
VAL_ 2654208120 ActiveLoadSlave_NPR 0 "No_active_loads_in_slave" 1 "Active_loads_in_slave" ;
VAL_ 2654208120 EOL_NPR 0 "No_EOL_prog_At_FIAT" 1 "EOL_prog_At_FIAT" ;
VAL_ 2654208120 GenericFailSts_NPR 0 "No_functional_fail_is_present" 1 "At_least_one_funct_fail_pres" ;
VAL_ 2654208120 CurrentFailSts_NPR 0 "No_functional_fail_is_present" 1 "DTCStatus_present" ;
VAL_ 2654208120 D_ES_NPR 0 "Error_Active_State" 1 "Error_Passive_Warning_State" 2 "Bus_Off_State" 3 "Not_used" ;
VAL_ 2654208121 Zero_byte_N3P 0 "Fixed" ;
VAL_ 2654208121 SystemStatus_N3P 0 "WU_wake_up_request" 1 "Not_used" 2 "SA_system_Stay_Active_req" 3 "Not_used" ;
VAL_ 2654208121 ActiveLoadSlave_N3P 0 "No_active_loads_in_slave" 1 "Active_loads_in_slave" ;
VAL_ 2654208121 EOL_N3P 0 "No_EOL_prog_At_FIAT" 1 "EOL_prog_At_FIAT" ;
VAL_ 2654208121 GenericFailSts_N3P 0 "No_functional_fail_is_present" 1 "At_least_one_funct_fail_pres" ;
VAL_ 2654208121 CurrentFailSts_N3P 0 "No_functional_fail_is_present" 1 "DTCStatus_present" ;
VAL_ 2654208121 D_ES_N3P 0 "Error_Active_State" 1 "Error_Passive_Warning_State" 2 "Bus_Off_State" 3 "Not_used" ;
VAL_ 2654208122 Zero_byte_RSH 0 "Fixed" ;
VAL_ 2654208122 SystemStatus_RSH 0 "WU_wake_up_request" 1 "Not_used" 2 "SA_system_Stay_Active_req" 3 "Not_used" ;
VAL_ 2654208122 ActiveLoadSlave_RSH 0 "No_active_loads_in_slave" 1 "Active_loads_in_slave" ;
VAL_ 2654208122 EOL_RSH 0 "No_EOL_prog_At_FIAT" 1 "EOL_prog_At_FIAT" ;
VAL_ 2654208122 GenericFailSts_RSH 0 "No_functional_fail_is_present" 1 "At_least_one_funct_fail_pres" ;
VAL_ 2654208122 CurrentFailSts_RSH 0 "No_functional_fail_is_present" 1 "DTCStatus_present" ;
VAL_ 2654208122 D_ES_RSH 0 "Error_Active_State" 1 "Error_Passive_Warning_State" 2 "Bus_Off_State" 3 "Not_used" ;
SIG_GROUP_ 1485 HVB_HMI_STS_SigGroup 1 : BatEstTimeToTarget BatPrecondProgress BatPrecondSts CRC_HVB_HMI_STS HVBBuzzerReq HVBChargeWarningForDisplay HVBSOC_Status_China_HMI HVBSOC_Status_HMI HVBStatus HVBWarningForDisplay HVB_SOC_BEV_HMI HVB_TemperatureFailSts HVSysWarningForDisplay LongParkingInfoForDisplay LongParkingSts MILrequest MsgCnt_HVB_HMI_STS;
